VERSION ""

NS_ :

BS_:

BU_: Dummy_PHS EBOOST_OBD_PHS EOCM2cp_IMX6_PHS EOCM2cp_K1_PHS EPSb_PHS EBCM_PHS EPSa_PHS CMMb_PHS CGM3a_PHS CMMa_PHS ADIMb_PHS

BO_ 386 Environment_Id_Resp_4_PHS: 8 EBCM_PHS
 SG_ AHAct : 31|1@0+ (1,0) [0|1] ""  CGM3a_PHS
 SG_ AHEnbld : 30|1@0+ (1,0) [0|1] ""  CGM3a_PHS
 SG_ ShfToPrkBfExtngIO : 29|1@0+ (1,0) [0|1] ""  CGM3a_PHS
 SG_ AHServcIO : 28|1@0+ (1,0) [0|1] ""  CGM3a_PHS
 SG_ AHAppBrkPedlIO : 27|1@0+ (1,0) [0|1] ""  CGM3a_PHS
 SG_ AHDisbldStbltIO : 26|1@0+ (1,0) [0|1] ""  CGM3a_PHS
 SG_ AHDisbldDrOpnIO : 25|1@0+ (1,0) [0|1] ""  CGM3a_PHS
 SG_ PMVSS_Disps : 58|3@0+ (1,0) [0|7] ""  CGM3a_PHS
 SG_ PMVSS_Exhst : 61|3@0+ (1,0) [0|7] ""  CGM3a_PHS
 SG_ PMVSS_PsngrSeat : 48|3@0+ (1,0) [0|7] ""  CGM3a_PHS
 SG_ PMVSS_DrvrSeat : 51|3@0+ (1,0) [0|7] ""  CGM3a_PHS
 SG_ PMVSS_AdptCrsCnt : 54|3@0+ (1,0) [0|7] ""  CGM3a_PHS
 SG_ PMVSS_Drvln : 41|3@0+ (1,0) [0|7] ""  CGM3a_PHS
 SG_ PMVSS_Susp : 44|3@0+ (1,0) [0|7] ""  CGM3a_PHS
 SG_ PMVSS_Strng : 47|3@0+ (1,0) [0|7] ""  CGM3a_PHS
 SG_ PMVSS_Trans : 34|3@0+ (1,0) [0|7] ""  CGM3a_PHS
 SG_ PMVSS_Eng : 37|3@0+ (1,0) [0|7] ""  CGM3a_PHS
 SG_ PMVSS_Snd : 24|3@0+ (1,0) [0|7] ""  CGM3a_PHS
 SG_ AdptCruzCtrlStg : 20|3@0+ (1,0) [0|7] ""  CGM3a_PHS
 SG_ AWDRecmndIO : 21|1@0+ (1,0) [0|1] ""  CGM3a_PHS
 SG_ EnvIdRsp4 : 7|16@0+ (1,0) [0|65535] ""  CGM3a_PHS
 SG_ EnvIdRspSt4 : 17|2@0+ (1,0) [0|3] ""  CGM3a_PHS

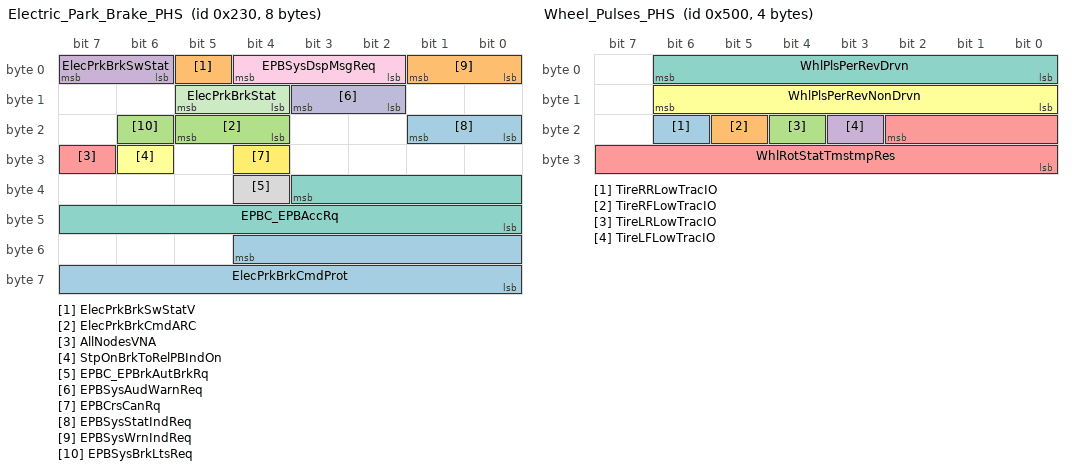
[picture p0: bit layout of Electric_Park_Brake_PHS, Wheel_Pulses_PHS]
BO_ 560 Electric_Park_Brake_PHS: 8 EBCM_PHS
 SG_ ElecPrkBrkCmdProt : 52|13@0+ (1,0) [0|8191] ""  CGM3a_PHS
 SG_ ElecPrkBrkSwStatV : 5|1@0+ (1,0) [0|1] ""  CGM3a_PHS
 SG_ ElecPrkBrkCmdARC : 21|2@0+ (1,0) [0|3] ""  CGM3a_PHS
 SG_ ElecPrkBrkSwStat : 7|2@0+ (1,0) [0|3] ""  CGM3a_PHS
 SG_ AllNodesVNA : 31|1@0+ (1,0) [0|1] ""  CGM3a_PHS
 SG_ StpOnBrkToRelPBIndOn : 30|1@0+ (1,0) [0|1] ""  CGM3a_PHS
 SG_ EPBC_EPBAccRq : 35|12@0- (0.01,0) [-20.48|20.47] "m/s^2"  CGM3a_PHS
 SG_ EPBC_EPBrkAutBrkRq : 36|1@0+ (1,0) [0|1] ""  CGM3a_PHS
 SG_ EPBSysDspMsgReq : 4|3@0+ (1,0) [0|7] ""  CGM3a_PHS
 SG_ EPBSysAudWarnReq : 11|2@0+ (1,0) [0|3] ""  CGM3a_PHS
 SG_ ElecPrkBrkStat : 13|2@0+ (1,0) [0|3] ""  CGM3a_PHS
 SG_ EPBCrsCanRq : 28|1@0+ (1,0) [0|1] ""  CGM3a_PHS
 SG_ EPBSysStatIndReq : 17|2@0+ (1,0) [0|3] ""  CGM3a_PHS
 SG_ EPBSysWrnIndReq : 1|2@0+ (1,0) [0|3] ""  CGM3a_PHS
 SG_ EPBSysBrkLtsReq : 22|1@0+ (1,0) [0|1] ""  CGM3a_PHS

BO_ 1280 Wheel_Pulses_PHS: 4 EBCM_PHS
 SG_ TireRRLowTracIO : 22|1@0+ (1,0) [0|1] ""  CGM3a_PHS,EOCM2cp_K1_PHS
 SG_ TireRFLowTracIO : 21|1@0+ (1,0) [0|1] ""  CGM3a_PHS,EOCM2cp_K1_PHS
 SG_ TireLRLowTracIO : 20|1@0+ (1,0) [0|1] ""  CGM3a_PHS,EOCM2cp_K1_PHS
 SG_ TireLFLowTracIO : 19|1@0+ (1,0) [0|1] ""  CGM3a_PHS,EOCM2cp_K1_PHS
 SG_ WhlRotStatTmstmpRes : 18|11@0+ (0.002,0) [0|4.094] "uSec"  CGM3a_PHS,EOCM2cp_K1_PHS
 SG_ WhlPlsPerRevNonDrvn : 14|7@0+ (1,0) [0|127] ""  CGM3a_PHS,EOCM2cp_K1_PHS
 SG_ WhlPlsPerRevDrvn : 6|7@0+ (1,0) [0|127] ""  CGM3a_PHS,EOCM2cp_K1_PHS

BO_ 761 PPEI_Chassis_Generl_Status_2_PHS: 7 EBCM_PHS
 SG_ BrkSysHRBkCtrlAvail : 24|1@0+ (1,0) [0|1] ""  CGM3a_PHS
 SG_ BrkSysHRBkCtrlStat : 26|2@0+ (1,0) [0|3] ""  CGM3a_PHS
 SG_ BrkSysHSAAval : 27|1@0+ (1,0) [0|1] ""  CGM3a_PHS
 SG_ BrkSysHSAStat : 30|3@0+ (1,0) [0|7] ""  CGM3a_PHS
 SG_ HillDscntCtrlStatPVal : 17|2@0+ (1,0) [0|3] ""  CGM3a_PHS
 SG_ HillDscntCtrlStatARC : 19|2@0+ (1,0) [0|3] ""  CGM3a_PHS
 SG_ HillDscntCtrlStat : 21|2@0+ (1,0) [0|3] ""  CGM3a_PHS
 SG_ AutoBrkFeatInhbtPVal : 49|2@0+ (1,0) [0|3] ""  CGM3a_PHS
 SG_ AutoBrkFeatInhbtARC : 51|2@0+ (1,0) [0|3] ""  CGM3a_PHS
 SG_ ABFI_CollPrepSysInhbt : 52|1@0+ (1,0) [0|1] ""  CGM3a_PHS
 SG_ ABFI_RrVirtlBmprInh : 53|1@0+ (1,0) [0|1] ""  CGM3a_PHS
 SG_ BrkPdlDrvApplPresV : 12|1@0+ (1,0) [0|1] ""  CGM3a_PHS
 SG_ BrkPdlDrvApplPres : 47|8@0+ (75,0) [0|19125] "kPa"  CGM3a_PHS
 SG_ AutoBrkPTReqStat : 15|3@0+ (1,0) [0|7] ""  CGM3a_PHS
 SG_ WhlSpdSnsgDTCIndex : 7|5@0+ (1,0) [0|31] ""  CGM3a_PHS
 SG_ WhlSpdSnsgDTCStat : 2|3@0+ (1,0) [0|7] ""  CGM3a_PHS
 SG_ SprTireSt : 10|3@0+ (1,0) [0|7] ""  CGM3a_PHS

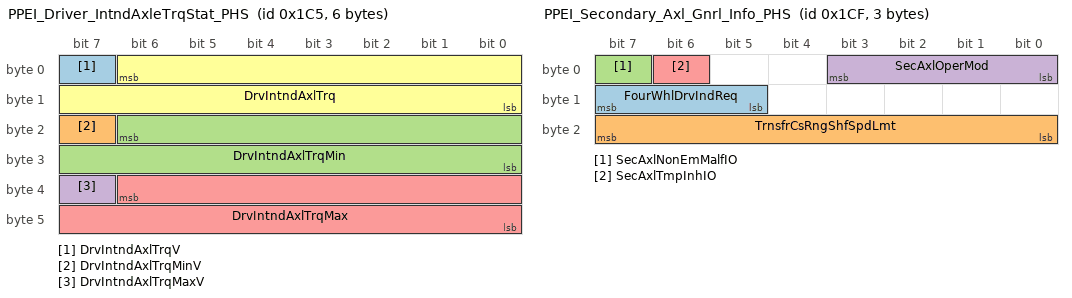
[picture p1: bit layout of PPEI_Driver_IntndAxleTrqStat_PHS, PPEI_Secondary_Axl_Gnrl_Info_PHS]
BO_ 453 PPEI_Driver_IntndAxleTrqStat_PHS: 6 CGM3a_PHS
 SG_ DrvIntndAxlTrqV : 7|1@0+ (1,0) [0|1] ""  EBCM_PHS
 SG_ DrvIntndAxlTrqMinV : 23|1@0+ (1,0) [0|1] "" Vector__XXX
 SG_ DrvIntndAxlTrqMin : 22|15@0+ (2,-22534) [-22534|43000] "Nm" Vector__XXX
 SG_ DrvIntndAxlTrqMaxV : 39|1@0+ (1,0) [0|1] "" Vector__XXX
 SG_ DrvIntndAxlTrqMax : 38|15@0+ (2,-22534) [-22534|43000] "Nm" Vector__XXX
 SG_ DrvIntndAxlTrq : 6|15@0+ (2,-22534) [-22534|43000] "Nm"  EBCM_PHS

BO_ 463 PPEI_Secondary_Axl_Gnrl_Info_PHS: 3 CGM3a_PHS
 SG_ FourWhlDrvIndReq : 15|3@0+ (1,0) [0|7] "" Vector__XXX
 SG_ TrnsfrCsRngShfSpdLmt : 23|8@0+ (1,0) [0|255] "km / h" Vector__XXX
 SG_ SecAxlNonEmMalfIO : 7|1@0+ (1,0) [0|1] "" Vector__XXX
 SG_ SecAxlOperMod : 3|4@0+ (1,0) [0|15] ""  EBCM_PHS
 SG_ SecAxlTmpInhIO : 6|1@0+ (1,0) [0|1] "" Vector__XXX

BO_ 419 PTEI_Engine_Common_Use_1_PHS: 1 CGM3a_PHS
 SG_ ClrCGMLgsDgInf : 6|1@0+ (1,0) [0|1] ""  EBCM_PHS
 SG_ EngRunng : 7|1@0+ (1,0) [0|1] ""  EBCM_PHS

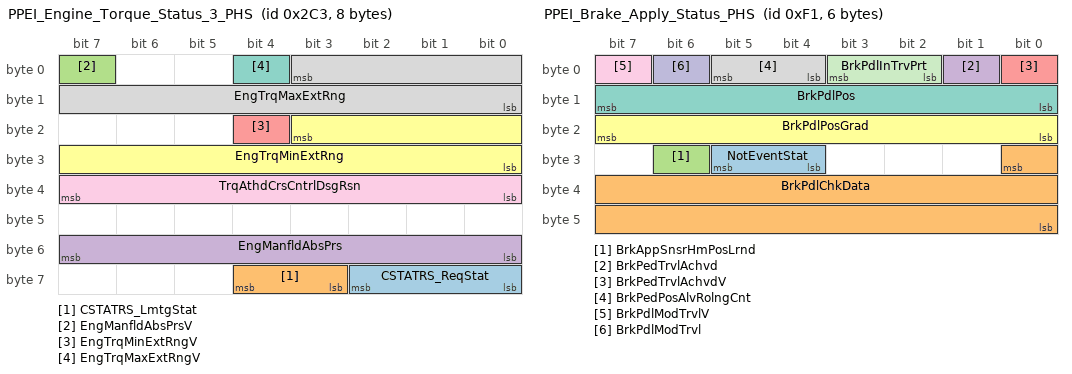
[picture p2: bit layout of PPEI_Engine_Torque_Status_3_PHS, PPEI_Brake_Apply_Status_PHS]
BO_ 707 PPEI_Engine_Torque_Status_3_PHS: 8 CGM3a_PHS
 SG_ CSTATRS_ReqStat : 58|3@0+ (1,0) [0|7] ""  EBCM_PHS
 SG_ CSTATRS_LmtgStat : 60|2@0+ (1,0) [0|3] ""  EBCM_PHS
 SG_ EngManfldAbsPrsV : 7|1@0+ (1,0) [0|1] ""  EBCM_PHS
 SG_ EngManfldAbsPrs : 55|8@0+ (0.5,0) [0|127.5] "kPa"  EBCM_PHS
 SG_ EngTrqMinExtRngV : 20|1@0+ (1,0) [0|1] ""  EBCM_PHS
 SG_ EngTrqMinExtRng : 19|12@0+ (0.5,-848) [-848|1199.5] "Nm"  EBCM_PHS
 SG_ EngTrqMaxExtRngV : 4|1@0+ (1,0) [0|1] ""  EBCM_PHS
 SG_ EngTrqMaxExtRng : 3|12@0+ (0.5,-848) [-848|1199.5] "Nm"  EBCM_PHS
 SG_ TrqAthdCrsCntrlDsgRsn : 39|8@0+ (1,0) [0|255] "" Vector__XXX

BO_ 451 PPEI_Engine_Torque_Status_2_PHS: 8 CGM3a_PHS
 SG_ HillDscntCtrlSwStatPVal : 57|2@0+ (1,0) [0|3] ""  EBCM_PHS
 SG_ HillDscntCtrlSwStatARC : 45|2@0+ (1,0) [0|3] ""  EBCM_PHS
 SG_ HillDscntCtrlSwStat : 47|2@0+ (1,0) [0|3] ""  EBCM_PHS
 SG_ GlwPlgCrnkDelAct : 58|1@0+ (1,0) [0|1] "" Vector__XXX
 SG_ AuxHtrAlwd : 23|1@0+ (1,0) [0|1] "" Vector__XXX
 SG_ AppCltchAutSrtIO : 59|1@0+ (1,0) [0|1] "" Vector__XXX
 SG_ AccPosV : 21|1@0+ (1,0) [0|1] ""  EBCM_PHS
 SG_ AccPos : 55|8@0+ (0.392157,0) [0|100.000035] "%"  EBCM_PHS
 SG_ FuelFltRmnLf : 39|8@0+ (0.392157,0) [0|100.000035] "%" Vector__XXX
 SG_ EngTrqRdFlrSt : 7|3@0+ (1,0) [0|7] ""  EBCM_PHS
 SG_ EngTrqDrRqdExtRngV : 20|1@0+ (1,0) [0|1] ""  EBCM_PHS
 SG_ EngTrqDrRqdExtRng : 19|12@0+ (0.5,-848) [-848|1199.5] "Nm"  EBCM_PHS
 SG_ EngTrqActExtRngV : 4|1@0+ (1,0) [0|1] ""  EBCM_PHS
 SG_ EngTrqActExtRng : 3|12@0+ (0.5,-848) [-848|1199.5] "Nm"  EBCM_PHS
 SG_ TrqAthdCrsCntrlAtv : 22|1@0+ (1,0) [0|1] "" Vector__XXX
 SG_ CrsCntrlRsmSet : 41|1@0+ (1,0) [0|1] "" Vector__XXX
 SG_ CrsCntrlSetSpdRtnd : 42|1@0+ (1,0) [0|1] "" Vector__XXX
 SG_ CrsCntrlSet : 40|1@0+ (1,0) [0|1] "" Vector__XXX

BO_ 241 PPEI_Brake_Apply_Status_PHS: 6 CGM3a_PHS
 SG_ NotEventStat : 29|2@0+ (1,0) [0|3] ""  EOCM2cp_K1_PHS
 SG_ BrkPdlChkData : 24|17@0+ (1,0) [0|131071] ""  EOCM2cp_K1_PHS
 SG_ BrkAppSnsrHmPosLrnd : 30|1@0+ (1,0) [0|1] ""  EOCM2cp_K1_PHS,EBCM_PHS
 SG_ BrkPedTrvlAchvd : 1|1@0+ (1,0) [0|1] ""  EOCM2cp_K1_PHS,EBCM_PHS
 SG_ BrkPedTrvlAchvdV : 0|1@0+ (1,0) [0|1] ""  EOCM2cp_K1_PHS,EBCM_PHS
 SG_ BrkPdlPosGrad : 23|8@0- (40,0) [-5120|5080] "%/s"  EOCM2cp_K1_PHS,EBCM_PHS
 SG_ BrkPdlPos : 15|8@0+ (0.392157,0) [0|100.000035] "% full"  EOCM2cp_K1_PHS,EBCM_PHS
 SG_ BrkPedPosAlvRolngCnt : 5|2@0+ (1,0) [0|3] ""  EOCM2cp_K1_PHS,EBCM_PHS
 SG_ BrkPdlModTrvlV : 7|1@0+ (1,0) [0|1] ""  EOCM2cp_K1_PHS
 SG_ BrkPdlModTrvl : 6|1@0+ (1,0) [0|1] ""  EOCM2cp_K1_PHS
 SG_ BrkPdlInTrvPrt : 3|2@0+ (1,0) [0|3] ""  EOCM2cp_K1_PHS,EBCM_PHS

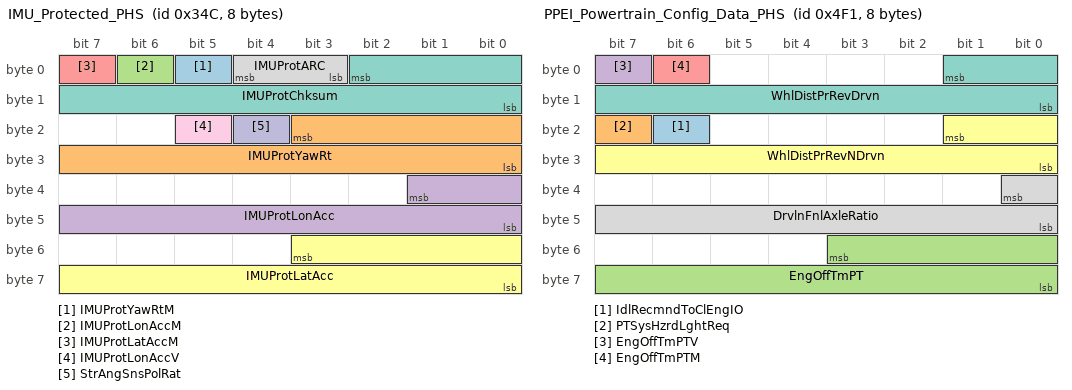
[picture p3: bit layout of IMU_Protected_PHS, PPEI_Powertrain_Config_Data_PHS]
BO_ 844 IMU_Protected_PHS: 8 EBCM_PHS
 SG_ IMUProtYawRtM : 5|1@0+ (1,0) [0|1] ""  CGM3a_PHS
 SG_ IMUProtYawRt : 19|12@0- (0.0625,0) [-128|127.9375] "deg/sec"  CGM3a_PHS
 SG_ IMUProtLonAccM : 6|1@0+ (1,0) [0|1] ""  CGM3a_PHS
 SG_ IMUProtLonAcc : 33|10@0- (0.03,0) [-15.36|15.33] "m/s^2"  CGM3a_PHS
 SG_ IMUProtLatAccM : 7|1@0+ (1,0) [0|1] ""  CGM3a_PHS
 SG_ IMUProtLatAcc : 51|12@0- (0.015625,0) [-32|31.984375] "m/s^2"  CGM3a_PHS
 SG_ IMUProtChksum : 2|11@0+ (1,0) [0|2047] ""  CGM3a_PHS
 SG_ IMUProtARC : 4|2@0+ (1,0) [0|3] ""  CGM3a_PHS
 SG_ IMUProtLonAccV : 21|1@0+ (1,0) [0|1] ""  CGM3a_PHS
 SG_ StrAngSnsPolRat : 20|1@0+ (1,0) [0|1] ""  CGM3a_PHS

BO_ 501 PPEI_Trans_General_Status_2_PHS: 8 CGM3a_PHS
 SG_ ElcRngSelDrvAct : 39|1@0+ (1,0) [0|1] "" Vector__XXX
 SG_ TmpDrvrShftCtlAct : 45|1@0+ (1,0) [0|1] ""  EOCM2cp_K1_PHS
 SG_ EngRecDwnshftIO : 54|1@0+ (1,0) [0|1] ""  EOCM2cp_K1_PHS
 SG_ TrnsPattSelEcnMdOCm : 52|1@0+ (1,0) [0|1] ""  EOCM2cp_K1_PHS
 SG_ CltStartSwAtvV : 38|1@0+ (1,0) [0|1] ""  EOCM2cp_K1_PHS
 SG_ CltStartSwAtv : 37|1@0+ (1,0) [0|1] ""  EOCM2cp_K1_PHS
 SG_ CltchPdlActPosV : 55|1@0+ (1,0) [0|1] ""  EBCM_PHS,EOCM2cp_K1_PHS
 SG_ CltchPdlActPos : 63|8@0+ (0.392157,0) [0|100.000035] "%"  EBCM_PHS,EOCM2cp_K1_PHS
 SG_ TrnsEngdStateV : 50|1@0+ (1,0) [0|1] ""  EOCM2cp_IMX6_PHS,EOCM2cp_K1_PHS,EBCM_PHS
 SG_ TrnsEngdState : 49|2@0+ (1,0) [0|3] ""  EOCM2cp_IMX6_PHS,EOCM2cp_K1_PHS,EBCM_PHS
 SG_ TrnsShftLvrLckRqd : 47|1@0+ (1,0) [0|1] ""  EOCM2cp_K1_PHS
 SG_ TransTUDMdStat : 41|2@0+ (1,0) [0|3] ""  EBCM_PHS,EOCM2cp_K1_PHS
 SG_ TrnCrpMdAtv : 46|1@0+ (1,0) [0|1] ""  EOCM2cp_K1_PHS
 SG_ TrnsSkpShftIO : 23|1@0+ (1,0) [0|1] ""  EOCM2cp_K1_PHS
 SG_ TrnsSftMdStat : 34|3@0+ (1,0) [0|7] ""  EBCM_PHS,EOCM2cp_K1_PHS
 SG_ TrnsRngInhbtStat : 31|3@0+ (1,0) [0|7] ""  EOCM2cp_K1_PHS
 SG_ TopTrvlCltchSwActV : 15|1@0+ (1,0) [0|1] ""  EOCM2cp_K1_PHS,EBCM_PHS
 SG_ TopTrvlCltchSwAct : 14|1@0+ (1,0) [0|1] ""  EOCM2cp_K1_PHS,EBCM_PHS
 SG_ EngRecmndUpshftIO : 22|1@0+ (1,0) [0|1] ""  EOCM2cp_K1_PHS
 SG_ DrvtShftCntrlTrgtGear : 19|4@0+ (1,0) [0|15] ""  EOCM2cp_K1_PHS
 SG_ DrShftCntrlReqDndIO : 21|1@0+ (1,0) [0|1] ""  EOCM2cp_K1_PHS
 SG_ TrnShftPtrnActStat : 44|3@0+ (1,0) [0|7] ""  EOCM2cp_K1_PHS,EBCM_PHS
 SG_ TrnsFldPrsPrsnt : 51|1@0+ (1,0) [0|1] ""  EOCM2cp_K1_PHS
 SG_ TrnsShftLvrPos : 27|4@0+ (1,0) [0|15] ""  EOCM2cp_IMX6_PHS,EOCM2cp_K1_PHS,EBCM_PHS
 SG_ TrnsShftLvrPosV : 28|1@0+ (1,0) [0|1] ""  EOCM2cp_IMX6_PHS,EOCM2cp_K1_PHS,EBCM_PHS
 SG_ TrnsTrqCnvCltCmndMd : 7|3@0+ (1,0) [0|7] ""  EOCM2cp_K1_PHS
 SG_ AutoTransComndGear : 11|4@0+ (1,0) [0|15] ""  EOCM2cp_IMX6_PHS,EBCM_PHS,EOCM2cp_K1_PHS
 SG_ AutoTransGrSftDirect : 13|2@0+ (1,0) [0|3] ""  EOCM2cp_IMX6_PHS,EBCM_PHS,EOCM2cp_K1_PHS
 SG_ TransEstGear : 3|4@0+ (1,0) [0|15] ""  EOCM2cp_IMX6_PHS,EOCM2cp_K1_PHS,EBCM_PHS
 SG_ TransEstGearV : 4|1@0+ (1,0) [0|1] ""  EOCM2cp_IMX6_PHS,EOCM2cp_K1_PHS,EBCM_PHS

BO_ 211 PPEI_Hybrid_General_Status_3_PHS: 2 CGM3a_PHS
 SG_ ActAxleTrqV : 7|1@0+ (1,0) [0|1] ""  EBCM_PHS
 SG_ ActAxleTrq : 6|15@0+ (2,-22534) [-22534|43000] "Nm"  EBCM_PHS

BO_ 1265 PPEI_Powertrain_Config_Data_PHS: 8 CGM3a_PHS
 SG_ IdlRecmndToClEngIO : 22|1@0+ (1,0) [0|1] "" Vector__XXX
 SG_ PTSysHzrdLghtReq : 23|1@0+ (1,0) [0|1] ""  EOCM2cp_K1_PHS
 SG_ EngOffTmPT : 51|12@0+ (0.5,0) [0|2047.5] "min"  EOCM2cp_K1_PHS,EBCM_PHS
 SG_ EngOffTmPTV : 7|1@0+ (1,0) [0|1] ""  EOCM2cp_K1_PHS,EBCM_PHS
 SG_ EngOffTmPTM : 6|1@0+ (1,0) [0|1] ""  EOCM2cp_K1_PHS,EBCM_PHS
 SG_ WhlDistPrRevNDrvn : 17|10@0+ (3,800) [800|3869] "mm"  EOCM2cp_K1_PHS,EBCM_PHS
 SG_ WhlDistPrRevDrvn : 1|10@0+ (3,800) [800|3869] "mm"  EOCM2cp_K1_PHS,EBCM_PHS
 SG_ DrvlnFnlAxleRatio : 32|9@0+ (0.01,2) [2|7.11] ""  EOCM2cp_K1_PHS,EBCM_PHS

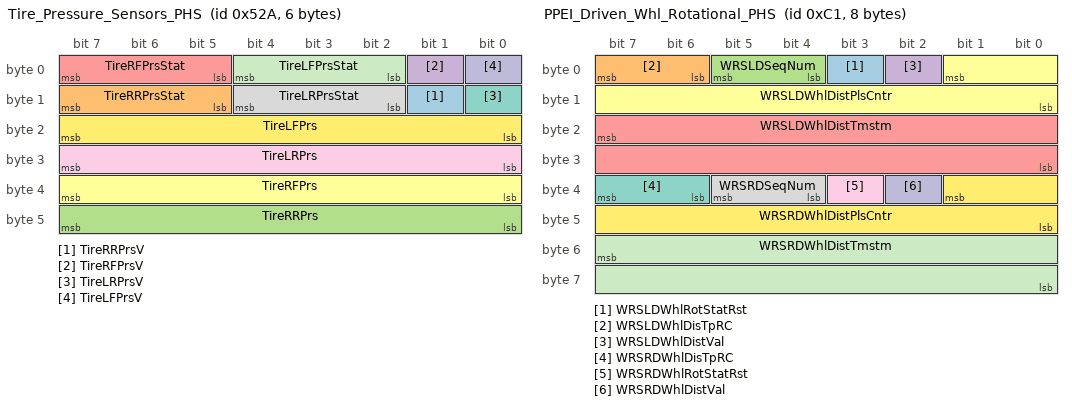
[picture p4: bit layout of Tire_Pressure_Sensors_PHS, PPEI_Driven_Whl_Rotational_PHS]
BO_ 1322 Tire_Pressure_Sensors_PHS: 6 CGM3a_PHS
 SG_ TireRRPrsV : 9|1@0+ (1,0) [0|1] ""  EBCM_PHS
 SG_ TireRRPrsStat : 15|3@0+ (1,0) [0|7] ""  EBCM_PHS
 SG_ TireRRPrs : 47|8@0+ (4,0) [0|1020] "kPaG"  EBCM_PHS
 SG_ TireRFPrsV : 1|1@0+ (1,0) [0|1] ""  EBCM_PHS
 SG_ TireRFPrsStat : 7|3@0+ (1,0) [0|7] ""  EBCM_PHS
 SG_ TireRFPrs : 39|8@0+ (4,0) [0|1020] "kPaG"  EBCM_PHS
 SG_ TireLRPrsV : 8|1@0+ (1,0) [0|1] ""  EBCM_PHS
 SG_ TireLRPrsStat : 12|3@0+ (1,0) [0|7] ""  EBCM_PHS
 SG_ TireLRPrs : 31|8@0+ (4,0) [0|1020] "kPaG"  EBCM_PHS
 SG_ TireLFPrsV : 0|1@0+ (1,0) [0|1] ""  EBCM_PHS
 SG_ TireLFPrsStat : 4|3@0+ (1,0) [0|7] ""  EBCM_PHS
 SG_ TireLFPrs : 23|8@0+ (4,0) [0|1020] "kPaG"  EBCM_PHS

BO_ 193 PPEI_Driven_Whl_Rotational_PHS: 8 EBCM_PHS
 SG_ WRSLDWhlRotStatRst : 3|1@0+ (1,0) [0|1] ""  ADIMb_PHS,CGM3a_PHS
 SG_ WRSLDWhlDisTpRC : 7|2@0+ (1,0) [0|3] "counts"  ADIMb_PHS,CGM3a_PHS
 SG_ WRSLDSeqNum : 5|2@0+ (1,0) [0|3] "counts"  ADIMb_PHS,CGM3a_PHS
 SG_ WRSLDWhlDistVal : 2|1@0+ (1,0) [0|1] ""  ADIMb_PHS,CGM3a_PHS
 SG_ WRSLDWhlDistTmstm : 23|16@0+ (1,0) [0|65535] "counts"  ADIMb_PHS,CGM3a_PHS
 SG_ WRSLDWhlDistPlsCntr : 1|10@0+ (1,0) [0|1023] "counts"  ADIMb_PHS,CGM3a_PHS
 SG_ WRSRDWhlDisTpRC : 39|2@0+ (1,0) [0|3] "counts"  ADIMb_PHS,CGM3a_PHS
 SG_ WRSRDSeqNum : 37|2@0+ (1,0) [0|3] "counts"  ADIMb_PHS,CGM3a_PHS
 SG_ WRSRDWhlRotStatRst : 35|1@0+ (1,0) [0|1] ""  ADIMb_PHS,CGM3a_PHS
 SG_ WRSRDWhlDistVal : 34|1@0+ (1,0) [0|1] ""  ADIMb_PHS,CGM3a_PHS
 SG_ WRSRDWhlDistTmstm : 55|16@0+ (1,0) [0|65535] "counts"  ADIMb_PHS,CGM3a_PHS
 SG_ WRSRDWhlDistPlsCntr : 33|10@0+ (1,0) [0|1023] "counts"  ADIMb_PHS,CGM3a_PHS

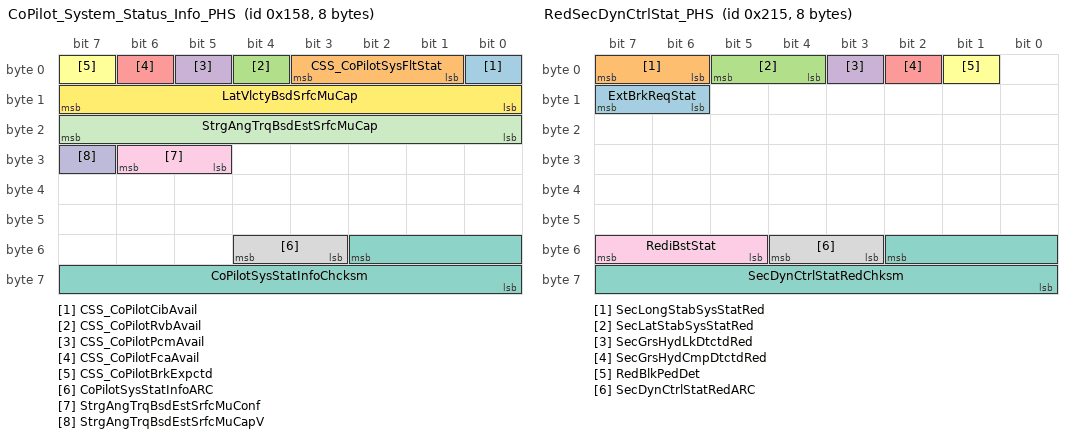
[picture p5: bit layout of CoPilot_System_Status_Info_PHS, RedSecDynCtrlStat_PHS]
BO_ 344 CoPilot_System_Status_Info_PHS: 8 EOCM2cp_K1_PHS
 SG_ CSS_CoPilotCibAvail : 0|1@0+ (1,0) [0|1] ""  EBOOST_OBD_PHS,EBCM_PHS,ADIMb_PHS
 SG_ CSS_CoPilotSysFltStat : 3|3@0+ (1,0) [0|7] ""  EBOOST_OBD_PHS,EBCM_PHS,ADIMb_PHS
 SG_ CSS_CoPilotRvbAvail : 4|1@0+ (1,0) [0|1] ""  EBOOST_OBD_PHS,EBCM_PHS,ADIMb_PHS
 SG_ CSS_CoPilotPcmAvail : 5|1@0+ (1,0) [0|1] ""  EBOOST_OBD_PHS,EBCM_PHS,ADIMb_PHS
 SG_ CSS_CoPilotFcaAvail : 6|1@0+ (1,0) [0|1] ""  EBOOST_OBD_PHS,EBCM_PHS,ADIMb_PHS
 SG_ CSS_CoPilotBrkExpctd : 7|1@0+ (1,0) [0|1] ""  EBOOST_OBD_PHS,EBCM_PHS,ADIMb_PHS
 SG_ CoPilotSysStatInfoChcksm : 50|11@0+ (1,0) [0|2047] ""  EBOOST_OBD_PHS,EBCM_PHS,ADIMb_PHS
 SG_ CoPilotSysStatInfoARC : 52|2@0+ (1,0) [0|0] ""  EBOOST_OBD_PHS,EBCM_PHS,ADIMb_PHS
 SG_ StrgAngTrqBsdEstSrfcMuConf : 30|2@0+ (1,0) [0|3] ""  EBOOST_OBD_PHS,EBCM_PHS,ADIMb_PHS
 SG_ StrgAngTrqBsdEstSrfcMuCapV : 31|1@0+ (1,0) [0|1] ""  EBOOST_OBD_PHS,EBCM_PHS,ADIMb_PHS
 SG_ StrgAngTrqBsdEstSrfcMuCap : 23|8@0+ (0.01,0) [0|2.55] ""  EBOOST_OBD_PHS,EBCM_PHS,ADIMb_PHS
 SG_ LatVlctyBsdSrfcMuCap : 15|8@0+ (0.01,0) [0|2.55] ""  EBOOST_OBD_PHS,EBCM_PHS,ADIMb_PHS

BO_ 533 RedSecDynCtrlStat_PHS: 8 EBOOST_OBD_PHS
 SG_ ExtBrkReqStat : 15|2@0+ (1,0) [0|3] ""  EBCM_PHS
 SG_ SecLongStabSysStatRed : 7|2@0+ (1,0) [0|3] ""  ADIMb_PHS,EBCM_PHS
 SG_ SecLatStabSysStatRed : 5|2@0+ (1,0) [0|0] ""  ADIMb_PHS,EBCM_PHS
 SG_ SecGrsHydLkDtctdRed : 3|1@0+ (1,0) [0|1] ""  ADIMb_PHS,EBCM_PHS
 SG_ SecGrsHydCmpDtctdRed : 2|1@0+ (1,0) [0|1] ""  ADIMb_PHS,EBCM_PHS
 SG_ RedBlkPedDet : 1|1@0+ (1,0) [0|1] ""  ADIMb_PHS,EBCM_PHS
 SG_ SecDynCtrlStatRedChksm : 50|11@0+ (1,0) [0|2047] ""  ADIMb_PHS,EBCM_PHS
 SG_ SecDynCtrlStatRedARC : 52|2@0+ (1,0) [0|3] ""  ADIMb_PHS,EBCM_PHS
 SG_ RediBstStat : 55|3@0+ (1,0) [0|7] ""  EBCM_PHS,ADIMb_PHS

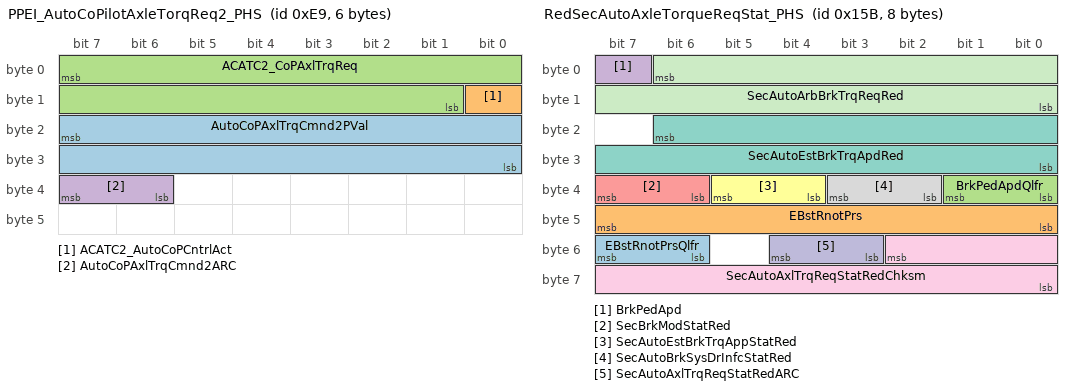
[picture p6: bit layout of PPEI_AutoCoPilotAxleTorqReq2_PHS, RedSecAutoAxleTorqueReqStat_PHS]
BO_ 233 PPEI_AutoCoPilotAxleTorqReq2_PHS: 6 EOCM2cp_K1_PHS
 SG_ AutoCoPAxlTrqCmnd2PVal : 23|16@0+ (1,0) [0|65535] ""  ADIMb_PHS,CGM3a_PHS
 SG_ ACATC2_AutoCoPCntrlAct : 8|1@0+ (1,0) [0|1] ""  ADIMb_PHS,CGM3a_PHS
 SG_ ACATC2_CoPAxlTrqReq : 7|15@0+ (2,-22534) [-22534|43000] "Nm"  ADIMb_PHS,CGM3a_PHS
 SG_ AutoCoPAxlTrqCmnd2ARC : 39|2@0+ (1,0) [0|3] ""  ADIMb_PHS,CGM3a_PHS

BO_ 347 RedSecAutoAxleTorqueReqStat_PHS: 8 EBOOST_OBD_PHS
 SG_ EBstRnotPrsQlfr : 55|2@0+ (1,0) [0|3] ""  EBCM_PHS
 SG_ EBstRnotPrs : 47|8@0+ (1,0) [0|255] "bar"  EBCM_PHS
 SG_ BrkPedApdQlfr : 33|2@0+ (1,0) [0|3] ""  EBCM_PHS
 SG_ BrkPedApd : 7|1@0+ (1,0) [0|1] ""  EBCM_PHS
 SG_ SecBrkModStatRed : 39|2@0+ (1,0) [0|3] ""  EBCM_PHS,ADIMb_PHS
 SG_ SecAutoEstBrkTrqAppStatRed : 37|2@0+ (1,0) [0|3] ""  EBCM_PHS,ADIMb_PHS
 SG_ SecAutoEstBrkTrqApdRed : 22|15@0+ (2,-65534) [-65534|0] "Nm"  EBCM_PHS,ADIMb_PHS
 SG_ SecAutoBrkSysDrInfcStatRed : 35|2@0+ (1,0) [0|3] ""  ADIMb_PHS,EBCM_PHS
 SG_ SecAutoAxlTrqReqStatRedChksm : 50|11@0+ (1,0) [0|2047] ""  EBCM_PHS,ADIMb_PHS
 SG_ SecAutoAxlTrqReqStatRedARC : 52|2@0+ (1,0) [0|3] ""  EBCM_PHS,ADIMb_PHS
 SG_ SecAutoArbBrkTrqReqRed : 6|15@0+ (2,-65534) [-65534|0] "Nm"  EBCM_PHS,ADIMb_PHS

BO_ 479 PPEI_Propulsion_Gen_Stat_1_PHS: 3 CGM3a_PHS
 SG_ EngAutoStpNotProb : 2|1@0+ (1,0) [0|1] "" Vector__XXX
 SG_ EASSI_UnsdRsrvd2 : 8|1@0+ (1,0) [0|1] ""  EBCM_PHS
 SG_ EASSI_StlDetd : 10|1@0+ (1,0) [0|1] ""  EBCM_PHS
 SG_ EASSI_TrqDetd : 11|1@0+ (1,0) [0|1] ""  EBCM_PHS
 SG_ EASSI_FuelReqOn : 12|1@0+ (1,0) [0|1] ""  EBCM_PHS
 SG_ EASSI_StrtTyp : 15|3@0+ (1,0) [0|7] ""  EBCM_PHS
 SG_ EASSI_StrtStpSt : 1|2@0+ (1,0) [0|3] ""  EBCM_PHS
 SG_ EASSI_TorqDetdIndet : 9|1@0+ (1,0) [0|1] ""  EBCM_PHS
 SG_ ASIRI_Indication08 : 16|1@0+ (1,0) [0|1] "" Vector__XXX
 SG_ ASIRI_Indication07 : 17|1@0+ (1,0) [0|1] "" Vector__XXX
 SG_ ASIRI_Indication06 : 18|1@0+ (1,0) [0|1] "" Vector__XXX
 SG_ ASIRI_Indication05 : 19|1@0+ (1,0) [0|1] "" Vector__XXX
 SG_ ASIRI_Indication04 : 20|1@0+ (1,0) [0|1] "" Vector__XXX
 SG_ ASIRI_Indication03 : 21|1@0+ (1,0) [0|1] "" Vector__XXX
 SG_ ASIRI_Indication02 : 22|1@0+ (1,0) [0|1] "" Vector__XXX
 SG_ ASIRI_Indication01 : 23|1@0+ (1,0) [0|1] "" Vector__XXX
 SG_ PTWrmgWtToShftIO : 5|1@0+ (1,0) [0|1] "" Vector__XXX
 SG_ PrplsnSysAtv : 7|1@0+ (1,0) [0|1] ""  CMMb_PHS,CMMa_PHS,EBOOST_OBD_PHS,EBCM_PHS
 SG_ PTShftLvrLckRqd : 6|1@0+ (1,0) [0|1] "" Vector__XXX

BO_ 452 PPEI_Torque_Request_Status_PHS: 8 CGM3a_PHS
 SG_ FSpRgACCSwADdPVal : 50|2@0+ (1,0) [0|3] ""  EBCM_PHS
 SG_ FSpRgACCSwADdARC : 6|2@0+ (1,0) [0|3] ""  EBCM_PHS
 SG_ FSpRgACCSwADd : 7|1@0+ (1,0) [0|1] ""  EBCM_PHS
 SG_ AutBrkAccActPsStRC : 34|2@0+ (1,0) [0|3] ""  EBCM_PHS
 SG_ AutBrkAccActPsStPVal : 48|9@0+ (1,0) [0|511] ""  EBCM_PHS
 SG_ ABAAPS_AccPos : 47|8@0+ (0.392157,0) [0|100.000035] "%"  EBCM_PHS
 SG_ ABAAPS_AccPosV : 32|1@0+ (1,0) [0|1] ""  EBCM_PHS
 SG_ ACCATCS_LmtgStat : 12|2@0+ (1,0) [0|3] "" Vector__XXX
 SG_ ACCATCS_RqStat : 15|3@0+ (1,0) [0|7] "" Vector__XXX
 SG_ RdLdNomAxlTrq : 10|19@0+ (0.125,-22534) [-22534|43001.875] "Nm" Vector__XXX
 SG_ AccPdlOvrrdAtvProtVal : 1|2@0+ (1,0) [0|3] ""  EBCM_PHS
 SG_ AccPdlOvrrdAtvARC : 3|2@0+ (1,0) [0|3] ""  EBCM_PHS
 SG_ AccPdlOvrrdAtv : 4|1@0+ (1,0) [0|1] ""  EBCM_PHS
 SG_ CPSATCS_ReqStatus : 37|3@0+ (1,0) [0|7] "" Vector__XXX
 SG_ CPSATCS_LmtngStatus : 39|2@0+ (1,0) [0|3] "" Vector__XXX
 SG_ RVBATCS_ReqStat : 53|3@0+ (1,0) [0|7] "" Vector__XXX
 SG_ RVBATCS_LmtngStat : 55|2@0+ (1,0) [0|3] "" Vector__XXX

BO_ 298 Body_Information_PHS: 8 CGM3a_PHS
 SG_ DrvrDrAjrSwVDA : 58|1@0+ (1,0) [0|1] "" Vector__XXX
 SG_ ValetMdAct : 59|1@0+ (1,0) [0|1] ""  EBCM_PHS
 SG_ AutoMdSpdLmtCnfrmd : 57|1@0+ (1,0) [0|1] ""  EOCM2cp_IMX6_PHS
 SG_ TCSysDisSwAtvARC : 61|2@0+ (1,0) [0|3] ""  EOCM2cp_IMX6_PHS,EBCM_PHS
 SG_ TCSysDisSwAtv_12A : 62|1@0+ (1,0) [0|1] ""  EOCM2cp_IMX6_PHS
 SG_ ChmAct : 55|1@0+ (1,0) [0|1] ""  EOCM2cp_IMX6_PHS
 SG_ Ky_IdDevPr : 56|1@0+ (1,0) [0|1] ""  EOCM2cp_IMX6_PHS,EBCM_PHS
 SG_ DDAjrSwAtvM : 63|1@0+ (1,0) [0|1] ""  EOCM2cp_IMX6_PHS,EBCM_PHS
 SG_ PsSbltAtcV : 54|1@0+ (1,0) [0|1] ""  EOCM2cp_IMX6_PHS
 SG_ PsSbltAtc : 53|1@0+ (1,0) [0|1] ""  EOCM2cp_IMX6_PHS
 SG_ TrlrBrkDsplyAct : 51|1@0+ (1,0) [0|1] ""  EOCM2cp_IMX6_PHS
 SG_ RdSpdCatType : 45|2@0+ (1,0) [0|3] ""  EOCM2cp_IMX6_PHS
 SG_ LnCat : 47|2@0+ (1,0) [0|3] ""  EOCM2cp_IMX6_PHS
 SG_ FncRdClass : 50|3@0+ (1,0) [0|7] ""  EOCM2cp_IMX6_PHS
 SG_ SprtLnRd : 43|1@0+ (1,0) [0|1] ""  EOCM2cp_IMX6_PHS
 SG_ CntrldAccRd : 39|1@0+ (1,0) [0|1] ""  EOCM2cp_IMX6_PHS
 SG_ BldUpArDet : 11|1@0+ (1,0) [0|1] ""  EOCM2cp_IMX6_PHS
 SG_ MpDataAvlbl : 3|1@0+ (1,0) [0|1] ""  EOCM2cp_IMX6_PHS
 SG_ SusCustStngReq : 42|3@0+ (1,0) [0|7] ""  EOCM2cp_IMX6_PHS,EBCM_PHS
 SG_ StrCustStngReq : 38|3@0+ (1,0) [0|7] ""  EOCM2cp_IMX6_PHS,EBCM_PHS
 SG_ RstrCustFctrDef : 35|1@0+ (1,0) [0|1] ""  EOCM2cp_IMX6_PHS,EBCM_PHS
 SG_ DrvlnCustStngReq : 34|3@0+ (1,0) [0|7] ""  EOCM2cp_IMX6_PHS,EBCM_PHS
 SG_ ChmMstrVDA : 22|1@0+ (1,0) [0|1] ""  EOCM2cp_IMX6_PHS
 SG_ IPCVDA : 21|1@0+ (1,0) [0|1] ""  EOCM2cp_IMX6_PHS,EBCM_PHS
 SG_ HeadUpDispVDA : 20|1@0+ (1,0) [0|1] ""  EOCM2cp_IMX6_PHS
 SG_ HapticSeatVDA : 52|1@0+ (1,0) [0|1] ""  EOCM2cp_IMX6_PHS
 SG_ RRDoorAjarSwAct : 23|1@0+ (1,0) [0|1] ""  EOCM2cp_IMX6_PHS
 SG_ PDAjrSwAtv : 10|1@0+ (1,0) [0|1] ""  EOCM2cp_IMX6_PHS
 SG_ DDAjrSwAtv : 9|1@0+ (1,0) [0|1] ""  EOCM2cp_IMX6_PHS,EBCM_PHS
 SG_ TrlrHWIntrfcVDA : 4|1@0+ (1,0) [0|1] ""  EOCM2cp_IMX6_PHS,EBCM_PHS
 SG_ DrId : 15|3@0+ (1,0) [0|7] ""  EOCM2cp_IMX6_PHS,EBCM_PHS
 SG_ EnrgMgtLdShdRq : 19|4@0+ (1,0) [0|15] ""  EOCM2cp_IMX6_PHS,EBOOST_OBD_PHS,EPSb_PHS,EBCM_PHS,EPSa_PHS
 SG_ DrSbltAtcV : 2|1@0+ (1,0) [0|1] ""  EOCM2cp_IMX6_PHS,EBCM_PHS
 SG_ TrlrHtchSwAtv : 0|1@0+ (1,0) [0|1] ""  EOCM2cp_IMX6_PHS,EBCM_PHS
 SG_ TreInfMonSysRstReq : 7|1@0+ (1,0) [0|1] ""  EOCM2cp_IMX6_PHS,EBCM_PHS
 SG_ HUDActv : 6|1@0+ (1,0) [0|1] ""  EOCM2cp_IMX6_PHS
 SG_ BatVltV : 1|1@0+ (1,0) [0|1] ""  EOCM2cp_IMX6_PHS
 SG_ BatVlt : 31|8@0+ (0.1,3) [3|28.5] "volts"  EOCM2cp_IMX6_PHS
 SG_ RLDoorAjarSwAct : 8|1@0+ (1,0) [0|1] ""  EOCM2cp_IMX6_PHS
 SG_ DrSbltAtc : 12|1@0+ (1,0) [0|1] ""  EOCM2cp_IMX6_PHS,EBCM_PHS

BO_ 1366 UUDT_Resp_From_CMMb_PHS: 8 CMMb_PHS
 SG_ DgnInf_HS556 : 7|64@0+ (1,0) [0|1.84467440737096E+019] ""  CGM3a_PHS

CM_ SG_ 707 TrqAthdCrsCntrlDsgRsn "VeACZC_e_DisengageCodeTmp";
CM_ SG_ 451 TrqAthdCrsCntrlAtv "VeCRZC_b_TorqAuthEnbldCruise";
CM_ SG_ 451 CrsCntrlRsmSet "VeACZC_b_RsmHasBeenSet";
CM_ SG_ 451 CrsCntrlSetSpdRtnd "VeACZC_b_MAIN_HasMemSpd";
CM_ SG_ 451 CrsCntrlSet "VeACZC_b_CruzHasBeenSet";
CM_ SG_ 241 BrkPdlModTrvlV "Indicates that the brake pedal position has passed a threshold for brake torque management and some 2 channel Vehicle Dynamics Control systems.";
CM_ SG_ 241 BrkPdlModTrvl "Indicates that the brake pedal position has passed a threshold for brake torque management and some 2 channel Vehicle Dynamics Control systems.";
CM_ SG_ 501 TrnShftPtrnActStat "(PT = Powertrain)";
CM_ SG_ 344 CSS_CoPilotCibAvail "Indicates if the CIB function is currently operational";
CM_ SG_ 344 CSS_CoPilotSysFltStat "

";
CM_ SG_ 344 CSS_CoPilotRvbAvail "CoPilot RVB Available";
CM_ SG_ 344 CSS_CoPilotPcmAvail "Indicates if the PCM function is currently operational";
CM_ SG_ 344 CSS_CoPilotFcaAvail "Indicates if the FCA function is currentlay operational";
CM_ SG_ 344 CSS_CoPilotBrkExpctd "Is Emergency Braking function expected to be functioning";
CM_ SG_ 298 DrId "Driver 8 changed to Unknown on 3/30/99";
BA_DEF_ SG_  "VNSigSLHSSharedDiagnostic" ENUM  "No","Yes";
BA_DEF_ SG_  "SignalType" STRING ;
BA_DEF_ SG_  "PacketOrder" INT 0 65535;
BA_DEF_ SG_  "SignalLongName" STRING ;
BA_DEF_ SG_  "GenSigStartValue" INT 0 65535;
BA_DEF_ SG_  "VNSigAllNodes" ENUM  "No","Yes";
BA_DEF_ SG_  "GenSigSendType" ENUM  "not used","not used","not used","not used","not used","not used","not used","NoSigSendType","not used","not used","OnAnyChange","OnChangeIfActive","OnDelta";
BA_DEF_ SG_  "GenSigSendOnInit" ENUM  "Not Initialized","Application","Handler";
BA_DEF_ BO_  "AppGenMsgCycleTime" INT 0 0;
BA_DEF_ BO_  "GenMsgILSupport" ENUM  "No","Yes";
BA_DEF_ BO_  "TpApplType" STRING ;
BA_DEF_ BO_  "Prio" INT 0 7;
BA_DEF_ BO_  "MessageSubnet" ENUM  "LS","HS","CE","PE","HV","FO","LE","HE2","PHS","PCE","DLCLS","DLCHS","DLCCE","DLCFO";
BA_DEF_ BO_  "DiagState" ENUM  "No","Yes";
BA_DEF_ BO_  "GenMsgStartDelayTime" INT 0 100000;
BA_DEF_ BO_  "GenMsgDelayTime" INT 0 100000;
BA_DEF_ BO_  "GenMsgCycleTime" INT 0 100000;
BA_DEF_ BO_  "GenMsgSendType" ENUM  "cyclicX","spontanX","cyclicIfActiveX","spontanWithDelay","cyclicAndSpontanX","cyclicAndSpontanWithDelay","spontanWithRepitition","cyclicIfActiveAndSpontanWD";
BA_DEF_ BO_  "DiagResponse" ENUM  "No","Yes";
BA_DEF_ BO_  "DiagRequest" ENUM  "No","Yes";
BA_DEF_ BO_  "NmMessage" ENUM  "No","Yes";
BA_DEF_REL_ BU_SG_REL_  "GenSigSuprvRespComment" STRING ;
BA_DEF_REL_ BU_SG_REL_  "GenSigVBitResp" ENUM  "No","Yes";
BA_DEF_REL_ BU_SG_REL_  "GenSigVBitRespComment" STRING ;
BA_DEF_REL_ BU_SG_REL_  "GenSigVDAFailComment" STRING ;
BA_DEF_REL_ BU_SG_REL_  "GenSigVDAFailResp" ENUM  "No","Yes";
BA_DEF_REL_ BU_SG_REL_  "GenSigRxStartValue" STRING ;
BA_DEF_REL_ BU_SG_REL_  "GenSigSuprvResp" ENUM  "None","Notify App","Substitute Default";
BA_DEF_REL_ BU_SG_REL_  "GenSigTimeoutMsg" HEX 0 268435455;
BA_DEF_REL_ BU_SG_REL_  "GenSigTimeoutTime" INT 0 15000;
BA_DEF_DEF_  "VNSigSLHSSharedDiagnostic" "No";
BA_DEF_DEF_  "SignalType" "";
BA_DEF_DEF_  "PacketOrder" 0;
BA_DEF_DEF_  "SignalLongName" "";
BA_DEF_DEF_  "GenSigStartValue" 0;
BA_DEF_DEF_  "VNSigAllNodes" "No";
BA_DEF_DEF_  "GenSigSendType" "NoSigSendType";
BA_DEF_DEF_  "GenSigSendOnInit" "Not Initialized";
BA_DEF_DEF_  "AppGenMsgCycleTime" 0;
BA_DEF_DEF_  "GenMsgILSupport" "Yes";
BA_DEF_DEF_  "TpApplType" "";
BA_DEF_DEF_  "Prio" 4;
BA_DEF_DEF_  "MessageSubnet" "LS";
BA_DEF_DEF_  "DiagState" "No";
BA_DEF_DEF_  "GenMsgStartDelayTime" 0;
BA_DEF_DEF_  "GenMsgDelayTime" 0;
BA_DEF_DEF_  "GenMsgCycleTime" 0;
BA_DEF_DEF_  "GenMsgSendType" "spontanX";
BA_DEF_DEF_  "DiagResponse" "No";
BA_DEF_DEF_  "DiagRequest" "No";
BA_DEF_DEF_  "NmMessage" "No";
BA_DEF_DEF_REL_ "GenSigSuprvRespComment" "";
BA_DEF_DEF_REL_ "GenSigVBitResp" "No";
BA_DEF_DEF_REL_ "GenSigVBitRespComment" "";
BA_DEF_DEF_REL_ "GenSigVDAFailComment" "";
BA_DEF_DEF_REL_ "GenSigVDAFailResp" "No";
BA_DEF_DEF_REL_ "GenSigRxStartValue" "";
BA_DEF_DEF_REL_ "GenSigSuprvResp" "None";
BA_DEF_DEF_REL_ "GenSigTimeoutMsg" 0;
BA_DEF_DEF_REL_ "GenSigTimeoutTime" 0;
BA_ "Prio" BO_ 386 0;
BA_ "MessageSubnet" BO_ 386 8;
BA_ "GenMsgCycleTime" BO_ 386 100;
BA_ "GenMsgSendType" BO_ 386 0;
BA_ "Prio" BO_ 560 0;
BA_ "MessageSubnet" BO_ 560 8;
BA_ "GenMsgCycleTime" BO_ 560 50;
BA_ "GenMsgSendType" BO_ 560 0;
BA_ "Prio" BO_ 1280 0;
BA_ "MessageSubnet" BO_ 1280 8;
BA_ "GenMsgCycleTime" BO_ 1280 1000;
BA_ "GenMsgSendType" BO_ 1280 0;
BA_ "Prio" BO_ 761 0;
BA_ "MessageSubnet" BO_ 761 8;
BA_ "GenMsgCycleTime" BO_ 761 50;
BA_ "GenMsgSendType" BO_ 761 0;
BA_ "Prio" BO_ 453 0;
BA_ "MessageSubnet" BO_ 453 8;
BA_ "GenMsgCycleTime" BO_ 453 25;
BA_ "GenMsgSendType" BO_ 453 0;
BA_ "Prio" BO_ 463 0;
BA_ "MessageSubnet" BO_ 463 8;
BA_ "GenMsgCycleTime" BO_ 463 100;
BA_ "GenMsgSendType" BO_ 463 0;
BA_ "Prio" BO_ 419 0;
BA_ "MessageSubnet" BO_ 419 8;
BA_ "GenMsgCycleTime" BO_ 419 25;
BA_ "GenMsgSendType" BO_ 419 0;
BA_ "Prio" BO_ 707 0;
BA_ "MessageSubnet" BO_ 707 8;
BA_ "GenMsgCycleTime" BO_ 707 50;
BA_ "GenMsgSendType" BO_ 707 0;
BA_ "Prio" BO_ 451 0;
BA_ "MessageSubnet" BO_ 451 8;
BA_ "GenMsgCycleTime" BO_ 451 25;
BA_ "GenMsgSendType" BO_ 451 0;
BA_ "Prio" BO_ 241 0;
BA_ "MessageSubnet" BO_ 241 8;
BA_ "GenMsgCycleTime" BO_ 241 10;
BA_ "GenMsgSendType" BO_ 241 0;
BA_ "Prio" BO_ 844 0;
BA_ "MessageSubnet" BO_ 844 8;
BA_ "GenMsgCycleTime" BO_ 844 50;
BA_ "GenMsgSendType" BO_ 844 0;
BA_ "Prio" BO_ 501 0;
BA_ "MessageSubnet" BO_ 501 8;
BA_ "GenMsgCycleTime" BO_ 501 25;
BA_ "GenMsgSendType" BO_ 501 0;
BA_ "Prio" BO_ 211 0;
BA_ "MessageSubnet" BO_ 211 8;
BA_ "GenMsgCycleTime" BO_ 211 12;
BA_ "GenMsgSendType" BO_ 211 0;
BA_ "Prio" BO_ 1265 0;
BA_ "MessageSubnet" BO_ 1265 8;
BA_ "GenMsgCycleTime" BO_ 1265 1000;
BA_ "GenMsgSendType" BO_ 1265 0;
BA_ "Prio" BO_ 1322 0;
BA_ "MessageSubnet" BO_ 1322 8;
BA_ "GenMsgStartDelayTime" BO_ 1322 40;
BA_ "GenMsgCycleTime" BO_ 1322 1000;
BA_ "GenMsgSendType" BO_ 1322 0;
BA_ "Prio" BO_ 193 0;
BA_ "MessageSubnet" BO_ 193 8;
BA_ "GenMsgCycleTime" BO_ 193 10;
BA_ "GenMsgSendType" BO_ 193 0;
BA_ "Prio" BO_ 344 0;
BA_ "MessageSubnet" BO_ 344 8;
BA_ "GenMsgCycleTime" BO_ 344 10;
BA_ "GenMsgSendType" BO_ 344 0;
BA_ "Prio" BO_ 533 0;
BA_ "MessageSubnet" BO_ 533 8;
BA_ "GenMsgCycleTime" BO_ 533 20;
BA_ "GenMsgSendType" BO_ 533 0;
BA_ "MessageSubnet" BO_ 233 8;
BA_ "GenMsgCycleTime" BO_ 233 10;
BA_ "GenMsgSendType" BO_ 233 0;
BA_ "Prio" BO_ 347 0;
BA_ "MessageSubnet" BO_ 347 8;
BA_ "GenMsgCycleTime" BO_ 347 10;
BA_ "GenMsgSendType" BO_ 347 0;
BA_ "Prio" BO_ 479 0;
BA_ "MessageSubnet" BO_ 479 8;
BA_ "GenMsgCycleTime" BO_ 479 25;
BA_ "GenMsgSendType" BO_ 479 0;
BA_ "Prio" BO_ 452 0;
BA_ "MessageSubnet" BO_ 452 8;
BA_ "GenMsgCycleTime" BO_ 452 25;
BA_ "GenMsgSendType" BO_ 452 0;
BA_ "Prio" BO_ 298 0;
BA_ "MessageSubnet" BO_ 298 8;
BA_ "GenMsgStartDelayTime" BO_ 298 40;
BA_ "GenMsgCycleTime" BO_ 298 100;
BA_ "GenMsgSendType" BO_ 298 0;
BA_ "GenMsgILSupport" BO_ 1366 0;
BA_ "TpApplType" BO_ 1366 "DiagUUDTResponse";
BA_ "Prio" BO_ 1366 0;
BA_ "MessageSubnet" BO_ 1366 8;
BA_ "SignalType" SG_ 386 AHAct "BLN";
BA_ "SignalLongName" SG_ 386 AHAct "Auto Hold Active";
BA_ "VNSigAllNodes" SG_ 386 AHAct 1;
BA_ "SignalType" SG_ 386 AHEnbld "BLN";
BA_ "SignalLongName" SG_ 386 AHEnbld "Auto Hold Enabled";
BA_ "VNSigAllNodes" SG_ 386 AHEnbld 1;
BA_ "SignalType" SG_ 386 ShfToPrkBfExtngIO "BLN";
BA_ "SignalLongName" SG_ 386 ShfToPrkBfExtngIO "Shift To Park Before Exiting Indication On";
BA_ "VNSigAllNodes" SG_ 386 ShfToPrkBfExtngIO 1;
BA_ "SignalType" SG_ 386 AHServcIO "BLN";
BA_ "SignalLongName" SG_ 386 AHServcIO "Auto Hold Service Indication On";
BA_ "VNSigAllNodes" SG_ 386 AHServcIO 1;
BA_ "SignalType" SG_ 386 AHAppBrkPedlIO "BLN";
BA_ "SignalLongName" SG_ 386 AHAppBrkPedlIO "Auto Hold Apply Brake Pedal Indication On";
BA_ "VNSigAllNodes" SG_ 386 AHAppBrkPedlIO 1;
BA_ "SignalType" SG_ 386 AHDisbldStbltIO "BLN";
BA_ "SignalLongName" SG_ 386 AHDisbldStbltIO "Auto Hold Disabled Seatbelt Indication On";
BA_ "VNSigAllNodes" SG_ 386 AHDisbldStbltIO 1;
BA_ "SignalType" SG_ 386 AHDisbldDrOpnIO "BLN";
BA_ "SignalLongName" SG_ 386 AHDisbldDrOpnIO "Auto Hold Disabled Door Open Indication On";
BA_ "VNSigAllNodes" SG_ 386 AHDisbldDrOpnIO 1;
BA_ "SignalType" SG_ 386 PMVSS_Disps "ENM";
BA_ "PacketOrder" SG_ 386 PMVSS_Disps 11;
BA_ "SignalLongName" SG_ 386 PMVSS_Disps "Performance Mode Visualization Screen Status : Displays";
BA_ "VNSigAllNodes" SG_ 386 PMVSS_Disps 1;
BA_ "SignalType" SG_ 386 PMVSS_Exhst "ENM";
BA_ "PacketOrder" SG_ 386 PMVSS_Exhst 10;
BA_ "SignalLongName" SG_ 386 PMVSS_Exhst "Performance Mode Visualization Screen Status : Exhaust";
BA_ "VNSigAllNodes" SG_ 386 PMVSS_Exhst 1;
BA_ "SignalType" SG_ 386 PMVSS_PsngrSeat "ENM";
BA_ "PacketOrder" SG_ 386 PMVSS_PsngrSeat 9;
BA_ "SignalLongName" SG_ 386 PMVSS_PsngrSeat "Performance Mode Visualization Screen Status : Passenger Seat";
BA_ "VNSigAllNodes" SG_ 386 PMVSS_PsngrSeat 1;
BA_ "SignalType" SG_ 386 PMVSS_DrvrSeat "ENM";
BA_ "PacketOrder" SG_ 386 PMVSS_DrvrSeat 8;
BA_ "SignalLongName" SG_ 386 PMVSS_DrvrSeat "Performance Mode Visualization Screen Status : Driver Seat";
BA_ "VNSigAllNodes" SG_ 386 PMVSS_DrvrSeat 1;
BA_ "SignalType" SG_ 386 PMVSS_AdptCrsCnt "ENM";
BA_ "PacketOrder" SG_ 386 PMVSS_AdptCrsCnt 7;
BA_ "SignalLongName" SG_ 386 PMVSS_AdptCrsCnt "Performance Mode Visualization Screen Status : Adaptive Cruise Control";
BA_ "VNSigAllNodes" SG_ 386 PMVSS_AdptCrsCnt 1;
BA_ "SignalType" SG_ 386 PMVSS_Drvln "ENM";
BA_ "PacketOrder" SG_ 386 PMVSS_Drvln 6;
BA_ "SignalLongName" SG_ 386 PMVSS_Drvln "Performance Mode Visualization Screen Status : Driveline";
BA_ "VNSigAllNodes" SG_ 386 PMVSS_Drvln 1;
BA_ "SignalType" SG_ 386 PMVSS_Susp "ENM";
BA_ "PacketOrder" SG_ 386 PMVSS_Susp 5;
BA_ "SignalLongName" SG_ 386 PMVSS_Susp "Performance Mode Visualization Screen Status : Suspension";
BA_ "VNSigAllNodes" SG_ 386 PMVSS_Susp 1;
BA_ "SignalType" SG_ 386 PMVSS_Strng "ENM";
BA_ "PacketOrder" SG_ 386 PMVSS_Strng 4;
BA_ "SignalLongName" SG_ 386 PMVSS_Strng "Performance Mode Visualization Screen Status : Steering";
BA_ "VNSigAllNodes" SG_ 386 PMVSS_Strng 1;
BA_ "SignalType" SG_ 386 PMVSS_Trans "ENM";
BA_ "PacketOrder" SG_ 386 PMVSS_Trans 3;
BA_ "SignalLongName" SG_ 386 PMVSS_Trans "Performance Mode Visualization Screen Status : Transmission";
BA_ "VNSigAllNodes" SG_ 386 PMVSS_Trans 1;
BA_ "SignalType" SG_ 386 PMVSS_Eng "ENM";
BA_ "PacketOrder" SG_ 386 PMVSS_Eng 2;
BA_ "SignalLongName" SG_ 386 PMVSS_Eng "Performance Mode Visualization Screen Status : Engine";
BA_ "VNSigAllNodes" SG_ 386 PMVSS_Eng 1;
BA_ "SignalType" SG_ 386 PMVSS_Snd "ENM";
BA_ "PacketOrder" SG_ 386 PMVSS_Snd 1;
BA_ "SignalLongName" SG_ 386 PMVSS_Snd "Performance Mode Visualization Screen Status : Sound";
BA_ "VNSigAllNodes" SG_ 386 PMVSS_Snd 1;
BA_ "SignalType" SG_ 386 AdptCruzCtrlStg "ENM";
BA_ "SignalLongName" SG_ 386 AdptCruzCtrlStg "Adaptive Cruise Control Setting";
BA_ "VNSigAllNodes" SG_ 386 AdptCruzCtrlStg 1;
BA_ "SignalType" SG_ 386 AWDRecmndIO "BLN";
BA_ "SignalLongName" SG_ 386 AWDRecmndIO "All Wheel Drive Recommended Indication On";
BA_ "VNSigAllNodes" SG_ 386 AWDRecmndIO 1;
BA_ "SignalType" SG_ 386 EnvIdRsp4 "UNM";
BA_ "SignalLongName" SG_ 386 EnvIdRsp4 "Environment Identification Response 4";
BA_ "VNSigAllNodes" SG_ 386 EnvIdRsp4 1;
BA_ "SignalType" SG_ 386 EnvIdRspSt4 "ENM";
BA_ "SignalLongName" SG_ 386 EnvIdRspSt4 "Environment Identification Response Status 4";
BA_ "VNSigAllNodes" SG_ 386 EnvIdRspSt4 1;
BA_ "SignalType" SG_ 560 ElecPrkBrkCmdProt "UNM";
BA_ "SignalLongName" SG_ 560 ElecPrkBrkCmdProt "Electric Park Brake Command Protection";
BA_ "VNSigAllNodes" SG_ 560 ElecPrkBrkCmdProt 1;
BA_ "SignalType" SG_ 560 ElecPrkBrkSwStatV "ENM";
BA_ "SignalLongName" SG_ 560 ElecPrkBrkSwStatV "Electric Park Brake Switch Status Validity";
BA_ "VNSigAllNodes" SG_ 560 ElecPrkBrkSwStatV 1;
BA_ "SignalType" SG_ 560 ElecPrkBrkCmdARC "UNM";
BA_ "SignalLongName" SG_ 560 ElecPrkBrkCmdARC "Electric Park Brake Command Alive Rolling Count";
BA_ "VNSigAllNodes" SG_ 560 ElecPrkBrkCmdARC 1;
BA_ "SignalType" SG_ 560 ElecPrkBrkSwStat "ENM";
BA_ "SignalLongName" SG_ 560 ElecPrkBrkSwStat "Electric Park Brake Switch Status";
BA_ "VNSigAllNodes" SG_ 560 ElecPrkBrkSwStat 1;
BA_ "SignalType" SG_ 560 AllNodesVNA "ENM";
BA_ "SignalLongName" SG_ 560 AllNodesVNA "All Nodes Virtual Network Activation";
BA_ "VNSigAllNodes" SG_ 560 AllNodesVNA 1;
BA_ "SignalType" SG_ 560 StpOnBrkToRelPBIndOn "BLN";
BA_ "SignalLongName" SG_ 560 StpOnBrkToRelPBIndOn "Step On Brake To Release Park Brake Indication On";
BA_ "VNSigAllNodes" SG_ 560 StpOnBrkToRelPBIndOn 1;
BA_ "SignalType" SG_ 560 EPBC_EPBAccRq "SNM";
BA_ "PacketOrder" SG_ 560 EPBC_EPBAccRq 2;
BA_ "SignalLongName" SG_ 560 EPBC_EPBAccRq "Electric Park Brake Command : Electric Park Brake Acceleration Requested";
BA_ "VNSigAllNodes" SG_ 560 EPBC_EPBAccRq 1;
BA_ "SignalType" SG_ 560 EPBC_EPBrkAutBrkRq "BLN";
BA_ "PacketOrder" SG_ 560 EPBC_EPBrkAutBrkRq 1;
BA_ "SignalLongName" SG_ 560 EPBC_EPBrkAutBrkRq "Electric Park Brake Command : Electric Park Brake Automatic Braking Requested";
BA_ "VNSigAllNodes" SG_ 560 EPBC_EPBrkAutBrkRq 1;
BA_ "SignalType" SG_ 560 EPBSysDspMsgReq "ENM";
BA_ "SignalLongName" SG_ 560 EPBSysDspMsgReq "Electric Park Brake System Display Message Request";
BA_ "VNSigAllNodes" SG_ 560 EPBSysDspMsgReq 1;
BA_ "SignalType" SG_ 560 EPBSysAudWarnReq "ENM";
BA_ "SignalLongName" SG_ 560 EPBSysAudWarnReq "Electric Park Brake System Audible Warning Request";
BA_ "VNSigAllNodes" SG_ 560 EPBSysAudWarnReq 1;
BA_ "SignalType" SG_ 560 ElecPrkBrkStat "ENM";
BA_ "SignalLongName" SG_ 560 ElecPrkBrkStat "Electric Park Brake Status";
BA_ "VNSigAllNodes" SG_ 560 ElecPrkBrkStat 1;
BA_ "SignalType" SG_ 560 EPBCrsCanRq "BLN";
BA_ "SignalLongName" SG_ 560 EPBCrsCanRq "Electric Park Brake Cruise Control Cancel Requested";
BA_ "VNSigAllNodes" SG_ 560 EPBCrsCanRq 1;
BA_ "SignalType" SG_ 560 EPBSysStatIndReq "ENM";
BA_ "SignalLongName" SG_ 560 EPBSysStatIndReq "Electric Park Brake System Status Indication Request";
BA_ "VNSigAllNodes" SG_ 560 EPBSysStatIndReq 1;
BA_ "SignalType" SG_ 560 EPBSysWrnIndReq "ENM";
BA_ "SignalLongName" SG_ 560 EPBSysWrnIndReq "Electric Park Brake System Warning Indication Request";
BA_ "VNSigAllNodes" SG_ 560 EPBSysWrnIndReq 1;
BA_ "SignalType" SG_ 560 EPBSysBrkLtsReq "BLN";
BA_ "SignalLongName" SG_ 560 EPBSysBrkLtsReq "Electric Park Brake System Brake Lights Requested";
BA_ "VNSigAllNodes" SG_ 560 EPBSysBrkLtsReq 1;
BA_ "SignalType" SG_ 1280 TireRRLowTracIO "BLN";
BA_ "SignalLongName" SG_ 1280 TireRRLowTracIO "Tire Right Rear Low Traction Indication On";
BA_ "VNSigAllNodes" SG_ 1280 TireRRLowTracIO 1;
BA_ "SignalType" SG_ 1280 TireRFLowTracIO "BLN";
BA_ "SignalLongName" SG_ 1280 TireRFLowTracIO "Tire Right Front Low Traction Indication On";
BA_ "VNSigAllNodes" SG_ 1280 TireRFLowTracIO 1;
BA_ "SignalType" SG_ 1280 TireLRLowTracIO "BLN";
BA_ "SignalLongName" SG_ 1280 TireLRLowTracIO "Tire Left Rear Low Traction Indication On";
BA_ "VNSigAllNodes" SG_ 1280 TireLRLowTracIO 1;
BA_ "SignalType" SG_ 1280 TireLFLowTracIO "BLN";
BA_ "SignalLongName" SG_ 1280 TireLFLowTracIO "Tire Left Front Low Traction Indication On";
BA_ "VNSigAllNodes" SG_ 1280 TireLFLowTracIO 1;
BA_ "SignalType" SG_ 1280 WhlRotStatTmstmpRes "UNM";
BA_ "SignalLongName" SG_ 1280 WhlRotStatTmstmpRes "Wheel Rotational Status Timestamp Resolution";
BA_ "VNSigAllNodes" SG_ 1280 WhlRotStatTmstmpRes 1;
BA_ "SignalType" SG_ 1280 WhlPlsPerRevNonDrvn "UNM";
BA_ "SignalLongName" SG_ 1280 WhlPlsPerRevNonDrvn "Wheel Pulses Per Revolution Non Driven";
BA_ "VNSigAllNodes" SG_ 1280 WhlPlsPerRevNonDrvn 1;
BA_ "SignalType" SG_ 1280 WhlPlsPerRevDrvn "UNM";
BA_ "SignalLongName" SG_ 1280 WhlPlsPerRevDrvn "Wheel Pulses Per Revolution Driven";
BA_ "VNSigAllNodes" SG_ 1280 WhlPlsPerRevDrvn 1;
BA_ "SignalType" SG_ 761 BrkSysHRBkCtrlAvail "BLN";
BA_ "SignalLongName" SG_ 761 BrkSysHRBkCtrlAvail "Brake System Hill Rollback Control Available";
BA_ "VNSigAllNodes" SG_ 761 BrkSysHRBkCtrlAvail 1;
BA_ "SignalType" SG_ 761 BrkSysHRBkCtrlStat "ENM";
BA_ "SignalLongName" SG_ 761 BrkSysHRBkCtrlStat "Brake System Hill Rollback Control Status";
BA_ "VNSigAllNodes" SG_ 761 BrkSysHRBkCtrlStat 1;
BA_ "SignalType" SG_ 761 BrkSysHSAAval "BLN";
BA_ "SignalLongName" SG_ 761 BrkSysHSAAval "Brake System Hill Start Assist Available";
BA_ "VNSigAllNodes" SG_ 761 BrkSysHSAAval 1;
BA_ "SignalType" SG_ 761 BrkSysHSAStat "ENM";
BA_ "SignalLongName" SG_ 761 BrkSysHSAStat "Brake System Hill Start Assist Status";
BA_ "VNSigAllNodes" SG_ 761 BrkSysHSAStat 1;
BA_ "SignalType" SG_ 761 HillDscntCtrlStatPVal "UNM";
BA_ "SignalLongName" SG_ 761 HillDscntCtrlStatPVal "Hill Descent Control Status Protection Value";
BA_ "VNSigAllNodes" SG_ 761 HillDscntCtrlStatPVal 1;
BA_ "SignalType" SG_ 761 HillDscntCtrlStatARC "UNM";
BA_ "SignalLongName" SG_ 761 HillDscntCtrlStatARC "Hill Descent Control Status Alive Rolling Count";
BA_ "VNSigAllNodes" SG_ 761 HillDscntCtrlStatARC 1;
BA_ "SignalType" SG_ 761 HillDscntCtrlStat "ENM";
BA_ "SignalLongName" SG_ 761 HillDscntCtrlStat "Hill Descent Control Status";
BA_ "VNSigAllNodes" SG_ 761 HillDscntCtrlStat 1;
BA_ "SignalType" SG_ 761 AutoBrkFeatInhbtPVal "UNM";
BA_ "SignalLongName" SG_ 761 AutoBrkFeatInhbtPVal "Automatic Braking Feature Inhibit Protection Value";
BA_ "VNSigAllNodes" SG_ 761 AutoBrkFeatInhbtPVal 1;
BA_ "SignalType" SG_ 761 AutoBrkFeatInhbtARC "UNM";
BA_ "SignalLongName" SG_ 761 AutoBrkFeatInhbtARC "Automatic Braking Feature Inhibit Alive Rolling Count";
BA_ "VNSigAllNodes" SG_ 761 AutoBrkFeatInhbtARC 1;
BA_ "SignalType" SG_ 761 ABFI_CollPrepSysInhbt "BLN";
BA_ "PacketOrder" SG_ 761 ABFI_CollPrepSysInhbt 2;
BA_ "SignalLongName" SG_ 761 ABFI_CollPrepSysInhbt "Automatic Braking Feature Inhibit : Collision Preparation System Inhibit";
BA_ "VNSigAllNodes" SG_ 761 ABFI_CollPrepSysInhbt 1;
BA_ "SignalType" SG_ 761 ABFI_RrVirtlBmprInh "BLN";
BA_ "PacketOrder" SG_ 761 ABFI_RrVirtlBmprInh 1;
BA_ "SignalLongName" SG_ 761 ABFI_RrVirtlBmprInh "Automatic Braking Feature Inhibit : Rear Virtual Bumper Inhibit";
BA_ "VNSigAllNodes" SG_ 761 ABFI_RrVirtlBmprInh 1;
BA_ "SignalType" SG_ 761 BrkPdlDrvApplPresV "ENM";
BA_ "SignalLongName" SG_ 761 BrkPdlDrvApplPresV "Brake Pedal Driver Applied Pressure Validity";
BA_ "VNSigAllNodes" SG_ 761 BrkPdlDrvApplPresV 1;
BA_ "SignalType" SG_ 761 BrkPdlDrvApplPres "UNM";
BA_ "SignalLongName" SG_ 761 BrkPdlDrvApplPres "Brake Pedal Driver Applied Pressure";
BA_ "VNSigAllNodes" SG_ 761 BrkPdlDrvApplPres 1;
BA_ "SignalType" SG_ 761 AutoBrkPTReqStat "ENM";
BA_ "SignalLongName" SG_ 761 AutoBrkPTReqStat "Automatic Braking Powertrain Request Status";
BA_ "VNSigAllNodes" SG_ 761 AutoBrkPTReqStat 1;
BA_ "SignalType" SG_ 761 WhlSpdSnsgDTCIndex "UNM";
BA_ "PacketOrder" SG_ 761 WhlSpdSnsgDTCIndex 1;
BA_ "SignalLongName" SG_ 761 WhlSpdSnsgDTCIndex "Wheel Speed Sensing Legislated Diagnostic Status : Diagnostic Trouble Code Index";
BA_ "VNSigAllNodes" SG_ 761 WhlSpdSnsgDTCIndex 1;
BA_ "SignalType" SG_ 761 WhlSpdSnsgDTCStat "ENM";
BA_ "PacketOrder" SG_ 761 WhlSpdSnsgDTCStat 2;
BA_ "SignalLongName" SG_ 761 WhlSpdSnsgDTCStat "Wheel Speed Sensing Legislated Diagnostic Status : Diagnostic Trouble Code Status";
BA_ "VNSigAllNodes" SG_ 761 WhlSpdSnsgDTCStat 1;
BA_ "SignalType" SG_ 761 SprTireSt "ENM";
BA_ "SignalLongName" SG_ 761 SprTireSt "Spare Tire Status";
BA_ "VNSigAllNodes" SG_ 761 SprTireSt 1;
BA_ "SignalType" SG_ 453 DrvIntndAxlTrqV "ENM";
BA_ "SignalLongName" SG_ 453 DrvIntndAxlTrqV "Driver Intended Axle Torque Validity";
BA_ "VNSigAllNodes" SG_ 453 DrvIntndAxlTrqV 1;
BA_ "SignalType" SG_ 453 DrvIntndAxlTrqMinV "ENM";
BA_ "SignalLongName" SG_ 453 DrvIntndAxlTrqMinV "Driver Intended Axle Torque Minimum Validity";
BA_ "VNSigAllNodes" SG_ 453 DrvIntndAxlTrqMinV 1;
BA_ "SignalType" SG_ 453 DrvIntndAxlTrqMin "UNM";
BA_ "SignalLongName" SG_ 453 DrvIntndAxlTrqMin "Driver Intended Axle Torque Minimum";
BA_ "VNSigAllNodes" SG_ 453 DrvIntndAxlTrqMin 1;
BA_ "SignalType" SG_ 453 DrvIntndAxlTrqMaxV "ENM";
BA_ "SignalLongName" SG_ 453 DrvIntndAxlTrqMaxV "Driver Intended Axle Torque Maximum Validity";
BA_ "VNSigAllNodes" SG_ 453 DrvIntndAxlTrqMaxV 1;
BA_ "SignalType" SG_ 453 DrvIntndAxlTrqMax "UNM";
BA_ "SignalLongName" SG_ 453 DrvIntndAxlTrqMax "Driver Intended Axle Torque Maximum";
BA_ "GenSigStartValue" SG_ 453 DrvIntndAxlTrqMax 32767;
BA_ "VNSigAllNodes" SG_ 453 DrvIntndAxlTrqMax 1;
BA_ "SignalType" SG_ 453 DrvIntndAxlTrq "UNM";
BA_ "SignalLongName" SG_ 453 DrvIntndAxlTrq "Driver Intended Axle Torque";
BA_ "GenSigStartValue" SG_ 453 DrvIntndAxlTrq 11267;
BA_ "VNSigAllNodes" SG_ 453 DrvIntndAxlTrq 1;
BA_ "SignalType" SG_ 463 FourWhlDrvIndReq "ENM";
BA_ "SignalLongName" SG_ 463 FourWhlDrvIndReq "Four Wheel Drive Indication Request";
BA_ "VNSigAllNodes" SG_ 463 FourWhlDrvIndReq 1;
BA_ "SignalType" SG_ 463 TrnsfrCsRngShfSpdLmt "UNM";
BA_ "SignalLongName" SG_ 463 TrnsfrCsRngShfSpdLmt "Transfer Case Range Shift Speed Limit";
BA_ "VNSigAllNodes" SG_ 463 TrnsfrCsRngShfSpdLmt 1;
BA_ "SignalType" SG_ 463 SecAxlNonEmMalfIO "BLN";
BA_ "SignalLongName" SG_ 463 SecAxlNonEmMalfIO "Secondary Axle Non-emissions Malf Ind On";
BA_ "VNSigAllNodes" SG_ 463 SecAxlNonEmMalfIO 1;
BA_ "SignalType" SG_ 463 SecAxlOperMod "ENM";
BA_ "SignalLongName" SG_ 463 SecAxlOperMod "Secondary Axle Operational Mode";
BA_ "VNSigAllNodes" SG_ 463 SecAxlOperMod 1;
BA_ "SignalType" SG_ 463 SecAxlTmpInhIO "BLN";
BA_ "SignalLongName" SG_ 463 SecAxlTmpInhIO "Secondary Axle Temporary Inhibit Indication On";
BA_ "VNSigAllNodes" SG_ 463 SecAxlTmpInhIO 1;
BA_ "SignalType" SG_ 419 ClrCGMLgsDgInf "BLN";
BA_ "SignalLongName" SG_ 419 ClrCGMLgsDgInf "Clear Central Gateway Module Legislated Diagnostic Information";
BA_ "VNSigAllNodes" SG_ 419 ClrCGMLgsDgInf 1;
BA_ "SignalType" SG_ 419 EngRunng "BLN";
BA_ "SignalLongName" SG_ 419 EngRunng "Engine Running";
BA_ "VNSigAllNodes" SG_ 419 EngRunng 1;
BA_ "SignalType" SG_ 707 CSTATRS_ReqStat "ENM";
BA_ "PacketOrder" SG_ 707 CSTATRS_ReqStat 2;
BA_ "SignalLongName" SG_ 707 CSTATRS_ReqStat "Chassis System Total Axle Torque Request Status : Request Status";
BA_ "VNSigAllNodes" SG_ 707 CSTATRS_ReqStat 1;
BA_ "SignalType" SG_ 707 CSTATRS_LmtgStat "ENM";
BA_ "PacketOrder" SG_ 707 CSTATRS_LmtgStat 1;
BA_ "SignalLongName" SG_ 707 CSTATRS_LmtgStat "Chassis System Total Axle Torque Request Status : Limiting Status";
BA_ "VNSigAllNodes" SG_ 707 CSTATRS_LmtgStat 1;
BA_ "SignalType" SG_ 707 EngManfldAbsPrsV "ENM";
BA_ "SignalLongName" SG_ 707 EngManfldAbsPrsV "Engine Manifold Absolute Pressure Validity";
BA_ "VNSigAllNodes" SG_ 707 EngManfldAbsPrsV 1;
BA_ "SignalType" SG_ 707 EngManfldAbsPrs "UNM";
BA_ "SignalLongName" SG_ 707 EngManfldAbsPrs "Engine Manifold Absolute Pressure";
BA_ "VNSigAllNodes" SG_ 707 EngManfldAbsPrs 1;
BA_ "SignalType" SG_ 707 EngTrqMinExtRngV "ENM";
BA_ "SignalLongName" SG_ 707 EngTrqMinExtRngV "Engine Torque Minimum Extended Range Validity";
BA_ "VNSigAllNodes" SG_ 707 EngTrqMinExtRngV 1;
BA_ "SignalType" SG_ 707 EngTrqMinExtRng "UNM";
BA_ "SignalLongName" SG_ 707 EngTrqMinExtRng "Engine Torque Minimum Extended Range";
BA_ "GenSigStartValue" SG_ 707 EngTrqMinExtRng 1696;
BA_ "VNSigAllNodes" SG_ 707 EngTrqMinExtRng 1;
BA_ "SignalType" SG_ 707 EngTrqMaxExtRngV "ENM";
BA_ "SignalLongName" SG_ 707 EngTrqMaxExtRngV "Engine Torque Maximum Extended Range Validity";
BA_ "VNSigAllNodes" SG_ 707 EngTrqMaxExtRngV 1;
BA_ "SignalType" SG_ 707 EngTrqMaxExtRng "UNM";
BA_ "SignalLongName" SG_ 707 EngTrqMaxExtRng "Engine Torque Maximum Extended Range";
BA_ "GenSigStartValue" SG_ 707 EngTrqMaxExtRng 1696;
BA_ "VNSigAllNodes" SG_ 707 EngTrqMaxExtRng 1;
BA_ "SignalType" SG_ 707 TrqAthdCrsCntrlDsgRsn "ENM";
BA_ "SignalLongName" SG_ 707 TrqAthdCrsCntrlDsgRsn "Torque Authorized Cruise Control Disengage Reason";
BA_ "GenSigStartValue" SG_ 707 TrqAthdCrsCntrlDsgRsn 12;
BA_ "VNSigAllNodes" SG_ 707 TrqAthdCrsCntrlDsgRsn 1;
BA_ "SignalType" SG_ 451 HillDscntCtrlSwStatPVal "UNM";
BA_ "SignalLongName" SG_ 451 HillDscntCtrlSwStatPVal "Hill Descent Control Switch Status Protection Value";
BA_ "VNSigAllNodes" SG_ 451 HillDscntCtrlSwStatPVal 1;
BA_ "SignalType" SG_ 451 HillDscntCtrlSwStatARC "UNM";
BA_ "SignalLongName" SG_ 451 HillDscntCtrlSwStatARC "Hill Descent Control Switch Status Alive Rolling Count";
BA_ "VNSigAllNodes" SG_ 451 HillDscntCtrlSwStatARC 1;
BA_ "SignalType" SG_ 451 HillDscntCtrlSwStat "ENM";
BA_ "SignalLongName" SG_ 451 HillDscntCtrlSwStat "Hill Descent Control Switch Status";
BA_ "VNSigAllNodes" SG_ 451 HillDscntCtrlSwStat 1;
BA_ "SignalType" SG_ 451 GlwPlgCrnkDelAct "BLN";
BA_ "SignalLongName" SG_ 451 GlwPlgCrnkDelAct "Glow Plugs Crank Delay Active";
BA_ "VNSigAllNodes" SG_ 451 GlwPlgCrnkDelAct 1;
BA_ "SignalType" SG_ 451 AuxHtrAlwd "BLN";
BA_ "SignalLongName" SG_ 451 AuxHtrAlwd "Auxiliary Heater Allowed";
BA_ "VNSigAllNodes" SG_ 451 AuxHtrAlwd 1;
BA_ "SignalType" SG_ 451 AppCltchAutSrtIO "BLN";
BA_ "SignalLongName" SG_ 451 AppCltchAutSrtIO "Apply Clutch For Automatic Start Indication On";
BA_ "VNSigAllNodes" SG_ 451 AppCltchAutSrtIO 1;
BA_ "SignalType" SG_ 451 AccPosV "ENM";
BA_ "SignalLongName" SG_ 451 AccPosV "Accelerator Effective Position Validity";
BA_ "VNSigAllNodes" SG_ 451 AccPosV 1;
BA_ "SignalType" SG_ 451 AccPos "UNM";
BA_ "SignalLongName" SG_ 451 AccPos "Accelerator Effective Position";
BA_ "VNSigAllNodes" SG_ 451 AccPos 1;
BA_ "SignalType" SG_ 451 FuelFltRmnLf "UNM";
BA_ "SignalLongName" SG_ 451 FuelFltRmnLf "Fuel Filter Remaining Life";
BA_ "VNSigAllNodes" SG_ 451 FuelFltRmnLf 1;
BA_ "SignalType" SG_ 451 EngTrqRdFlrSt "ENM";
BA_ "SignalLongName" SG_ 451 EngTrqRdFlrSt "Engine Torque Reduction Failure Status";
BA_ "VNSigAllNodes" SG_ 451 EngTrqRdFlrSt 1;
BA_ "SignalType" SG_ 451 EngTrqDrRqdExtRngV "ENM";
BA_ "SignalLongName" SG_ 451 EngTrqDrRqdExtRngV "Engine Torque Driver Requested Extended Range Validity";
BA_ "VNSigAllNodes" SG_ 451 EngTrqDrRqdExtRngV 1;
BA_ "SignalType" SG_ 451 EngTrqDrRqdExtRng "UNM";
BA_ "SignalLongName" SG_ 451 EngTrqDrRqdExtRng "Engine Torque Driver Requested Extended Range";
BA_ "GenSigStartValue" SG_ 451 EngTrqDrRqdExtRng 1696;
BA_ "VNSigAllNodes" SG_ 451 EngTrqDrRqdExtRng 1;
BA_ "SignalType" SG_ 451 EngTrqActExtRngV "ENM";
BA_ "SignalLongName" SG_ 451 EngTrqActExtRngV "Engine Torque Actual Extended Range Validity";
BA_ "VNSigAllNodes" SG_ 451 EngTrqActExtRngV 1;
BA_ "SignalType" SG_ 451 EngTrqActExtRng "UNM";
BA_ "SignalLongName" SG_ 451 EngTrqActExtRng "Engine Torque Actual Extended Range";
BA_ "GenSigStartValue" SG_ 451 EngTrqActExtRng 1696;
BA_ "VNSigAllNodes" SG_ 451 EngTrqActExtRng 1;
BA_ "SignalType" SG_ 451 TrqAthdCrsCntrlAtv "BLN";
BA_ "SignalLongName" SG_ 451 TrqAthdCrsCntrlAtv "Torque Authorized Cruise Control Active";
BA_ "VNSigAllNodes" SG_ 451 TrqAthdCrsCntrlAtv 1;
BA_ "SignalType" SG_ 451 CrsCntrlRsmSet "BLN";
BA_ "SignalLongName" SG_ 451 CrsCntrlRsmSet "Cruise Control Resume Set";
BA_ "VNSigAllNodes" SG_ 451 CrsCntrlRsmSet 1;
BA_ "SignalType" SG_ 451 CrsCntrlSetSpdRtnd "BLN";
BA_ "SignalLongName" SG_ 451 CrsCntrlSetSpdRtnd "Cruise Control Set Speed Retained";
BA_ "VNSigAllNodes" SG_ 451 CrsCntrlSetSpdRtnd 1;
BA_ "SignalType" SG_ 451 CrsCntrlSet "BLN";
BA_ "SignalLongName" SG_ 451 CrsCntrlSet "Cruise Control Set";
BA_ "VNSigAllNodes" SG_ 451 CrsCntrlSet 1;
BA_ "SignalType" SG_ 241 NotEventStat "ENM";
BA_ "SignalLongName" SG_ 241 NotEventStat "Notification Event Status";
BA_ "VNSigAllNodes" SG_ 241 NotEventStat 1;
BA_ "SignalType" SG_ 241 BrkPdlChkData "UNM";
BA_ "SignalLongName" SG_ 241 BrkPdlChkData "Brake Pedal Check Data";
BA_ "VNSigAllNodes" SG_ 241 BrkPdlChkData 1;
BA_ "SignalType" SG_ 241 BrkAppSnsrHmPosLrnd "BLN";
BA_ "SignalLongName" SG_ 241 BrkAppSnsrHmPosLrnd "Brake Apply Sensor Home Position Learned";
BA_ "VNSigAllNodes" SG_ 241 BrkAppSnsrHmPosLrnd 1;
BA_ "SignalType" SG_ 241 BrkPedTrvlAchvd "BLN";
BA_ "PacketOrder" SG_ 241 BrkPedTrvlAchvd 1;
BA_ "SignalLongName" SG_ 241 BrkPedTrvlAchvd "Brake Pedal Initial Travel Achieved Status : Brake Pedal Initial Travel Achieved";
BA_ "VNSigAllNodes" SG_ 241 BrkPedTrvlAchvd 1;
BA_ "SignalType" SG_ 241 BrkPedTrvlAchvdV "ENM";
BA_ "PacketOrder" SG_ 241 BrkPedTrvlAchvdV 2;
BA_ "SignalLongName" SG_ 241 BrkPedTrvlAchvdV "Brake Pedal Initial Travel Achieved Status : Brake Pedal Initial Travel Achieved Validity";
BA_ "VNSigAllNodes" SG_ 241 BrkPedTrvlAchvdV 1;
BA_ "SignalType" SG_ 241 BrkPdlPosGrad "SNM";
BA_ "SignalLongName" SG_ 241 BrkPdlPosGrad "Brake Pedal Position Gradient";
BA_ "VNSigAllNodes" SG_ 241 BrkPdlPosGrad 1;
BA_ "SignalType" SG_ 241 BrkPdlPos "UNM";
BA_ "SignalLongName" SG_ 241 BrkPdlPos "Brake Pedal Position";
BA_ "VNSigAllNodes" SG_ 241 BrkPdlPos 1;
BA_ "SignalType" SG_ 241 BrkPedPosAlvRolngCnt "UNM";
BA_ "SignalLongName" SG_ 241 BrkPedPosAlvRolngCnt "Brake Pedal Position Alive Rolling Count";
BA_ "VNSigAllNodes" SG_ 241 BrkPedPosAlvRolngCnt 1;
BA_ "SignalType" SG_ 241 BrkPdlModTrvlV "ENM";
BA_ "SignalLongName" SG_ 241 BrkPdlModTrvlV "Brake Pedal Moderate Travel Achieved Validity";
BA_ "VNSigAllNodes" SG_ 241 BrkPdlModTrvlV 1;
BA_ "SignalType" SG_ 241 BrkPdlModTrvl "BLN";
BA_ "SignalLongName" SG_ 241 BrkPdlModTrvl "Brake Pedal Moderate Travel Achieved";
BA_ "VNSigAllNodes" SG_ 241 BrkPdlModTrvl 1;
BA_ "SignalType" SG_ 241 BrkPdlInTrvPrt "UNM";
BA_ "SignalLongName" SG_ 241 BrkPdlInTrvPrt "Brake Pedal Initial Travel Achieved Protection";
BA_ "VNSigAllNodes" SG_ 241 BrkPdlInTrvPrt 1;
BA_ "SignalType" SG_ 844 IMUProtYawRtM "ENM";
BA_ "SignalLongName" SG_ 844 IMUProtYawRtM "Inertial Measurement Unit Protected Yaw Rate Mask";
BA_ "VNSigAllNodes" SG_ 844 IMUProtYawRtM 1;
BA_ "SignalType" SG_ 844 IMUProtYawRt "SNM";
BA_ "SignalLongName" SG_ 844 IMUProtYawRt "Inertial Measurement Unit Protected Yaw Rate";
BA_ "VNSigAllNodes" SG_ 844 IMUProtYawRt 1;
BA_ "SignalType" SG_ 844 IMUProtLonAccM "ENM";
BA_ "SignalLongName" SG_ 844 IMUProtLonAccM "Inertial Measurement Unit Protected Longitudinal Acceleration Mask";
BA_ "VNSigAllNodes" SG_ 844 IMUProtLonAccM 1;
BA_ "SignalType" SG_ 844 IMUProtLonAcc "SNM";
BA_ "SignalLongName" SG_ 844 IMUProtLonAcc "Inertial Measurement Unit Protected Longitudinal Acceleration";
BA_ "VNSigAllNodes" SG_ 844 IMUProtLonAcc 1;
BA_ "SignalType" SG_ 844 IMUProtLatAccM "ENM";
BA_ "SignalLongName" SG_ 844 IMUProtLatAccM "Inertial Measurement Unit Protected Lateral Acceleration Mask";
BA_ "VNSigAllNodes" SG_ 844 IMUProtLatAccM 1;
BA_ "SignalType" SG_ 844 IMUProtLatAcc "SNM";
BA_ "SignalLongName" SG_ 844 IMUProtLatAcc "Inertial Measurement Unit Protected Lateral Acceleration";
BA_ "VNSigAllNodes" SG_ 844 IMUProtLatAcc 1;
BA_ "SignalType" SG_ 844 IMUProtChksum "UNM";
BA_ "SignalLongName" SG_ 844 IMUProtChksum "Inertial Measurement Unit Protected Checksum";
BA_ "VNSigAllNodes" SG_ 844 IMUProtChksum 1;
BA_ "SignalType" SG_ 844 IMUProtARC "UNM";
BA_ "SignalLongName" SG_ 844 IMUProtARC "Inertial Measurement Unit Protected Alive Rolling Count";
BA_ "VNSigAllNodes" SG_ 844 IMUProtARC 1;
BA_ "SignalType" SG_ 844 IMUProtLonAccV "ENM";
BA_ "SignalLongName" SG_ 844 IMUProtLonAccV "Inertial Measurement Unit Protected Longitudinal Acceleration Validity";
BA_ "VNSigAllNodes" SG_ 844 IMUProtLonAccV 1;
BA_ "SignalType" SG_ 844 StrAngSnsPolRat "ENM";
BA_ "SignalLongName" SG_ 844 StrAngSnsPolRat "Steering Angle Sensor Polarity Rationality";
BA_ "VNSigAllNodes" SG_ 844 StrAngSnsPolRat 1;
BA_ "SignalType" SG_ 501 ElcRngSelDrvAct "BLN";
BA_ "SignalLongName" SG_ 501 ElcRngSelDrvAct "Electronic Range Selection In Drive Active";
BA_ "VNSigAllNodes" SG_ 501 ElcRngSelDrvAct 1;
BA_ "SignalType" SG_ 501 TmpDrvrShftCtlAct "BLN";
BA_ "SignalLongName" SG_ 501 TmpDrvrShftCtlAct "Temporary Driver Shift Control Active";
BA_ "VNSigAllNodes" SG_ 501 TmpDrvrShftCtlAct 1;
BA_ "SignalType" SG_ 501 EngRecDwnshftIO "BLN";
BA_ "SignalLongName" SG_ 501 EngRecDwnshftIO "Engine Recommended Downshift Indication On";
BA_ "VNSigAllNodes" SG_ 501 EngRecDwnshftIO 1;
BA_ "SignalType" SG_ 501 TrnsPattSelEcnMdOCm "BLN";
BA_ "SignalLongName" SG_ 501 TrnsPattSelEcnMdOCm "Transmission Pattern Selection Economy Mode Override Commanded";
BA_ "VNSigAllNodes" SG_ 501 TrnsPattSelEcnMdOCm 1;
BA_ "SignalType" SG_ 501 CltStartSwAtvV "ENM";
BA_ "SignalLongName" SG_ 501 CltStartSwAtvV "Clutch Start Switch Active Validity";
BA_ "VNSigAllNodes" SG_ 501 CltStartSwAtvV 1;
BA_ "SignalType" SG_ 501 CltStartSwAtv "BLN";
BA_ "SignalLongName" SG_ 501 CltStartSwAtv "Clutch Start Switch Active";
BA_ "GenSigStartValue" SG_ 501 CltStartSwAtv 1;
BA_ "VNSigAllNodes" SG_ 501 CltStartSwAtv 1;
BA_ "SignalType" SG_ 501 CltchPdlActPosV "ENM";
BA_ "SignalLongName" SG_ 501 CltchPdlActPosV "Clutch Pedal Actual Position Validity";
BA_ "VNSigAllNodes" SG_ 501 CltchPdlActPosV 1;
BA_ "SignalType" SG_ 501 CltchPdlActPos "UNM";
BA_ "SignalLongName" SG_ 501 CltchPdlActPos "Clutch Pedal Actual Position";
BA_ "VNSigAllNodes" SG_ 501 CltchPdlActPos 1;
BA_ "SignalType" SG_ 501 TrnsEngdStateV "ENM";
BA_ "SignalLongName" SG_ 501 TrnsEngdStateV "Transmission Engaged State Validity";
BA_ "VNSigAllNodes" SG_ 501 TrnsEngdStateV 1;
BA_ "SignalType" SG_ 501 TrnsEngdState "ENM";
BA_ "SignalLongName" SG_ 501 TrnsEngdState "Transmission Engaged State";
BA_ "VNSigAllNodes" SG_ 501 TrnsEngdState 1;
BA_ "SignalType" SG_ 501 TrnsShftLvrLckRqd "BLN";
BA_ "SignalLongName" SG_ 501 TrnsShftLvrLckRqd "Transmission Shift Lever Lock Requested";
BA_ "VNSigAllNodes" SG_ 501 TrnsShftLvrLckRqd 1;
BA_ "SignalType" SG_ 501 TransTUDMdStat "ENM";
BA_ "SignalLongName" SG_ 501 TransTUDMdStat "Transmission Tap Up/Tap Down Mode Status";
BA_ "VNSigAllNodes" SG_ 501 TransTUDMdStat 1;
BA_ "SignalType" SG_ 501 TrnCrpMdAtv "BLN";
BA_ "SignalLongName" SG_ 501 TrnCrpMdAtv "Transmission Creep Mode Active";
BA_ "VNSigAllNodes" SG_ 501 TrnCrpMdAtv 1;
BA_ "SignalType" SG_ 501 TrnsSkpShftIO "BLN";
BA_ "SignalLongName" SG_ 501 TrnsSkpShftIO "Transmission Skip Shift Indication On";
BA_ "VNSigAllNodes" SG_ 501 TrnsSkpShftIO 1;
BA_ "SignalType" SG_ 501 TrnsSftMdStat "ENM";
BA_ "SignalLongName" SG_ 501 TrnsSftMdStat "Transmission Shift Mode Status";
BA_ "VNSigAllNodes" SG_ 501 TrnsSftMdStat 1;
BA_ "SignalType" SG_ 501 TrnsRngInhbtStat "ENM";
BA_ "SignalLongName" SG_ 501 TrnsRngInhbtStat "Transmission Range Inhibit Status";
BA_ "VNSigAllNodes" SG_ 501 TrnsRngInhbtStat 1;
BA_ "SignalType" SG_ 501 TopTrvlCltchSwActV "ENM";
BA_ "SignalLongName" SG_ 501 TopTrvlCltchSwActV "Top of Travel Clutch Switch Active Validity";
BA_ "VNSigAllNodes" SG_ 501 TopTrvlCltchSwActV 1;
BA_ "SignalType" SG_ 501 TopTrvlCltchSwAct "BLN";
BA_ "SignalLongName" SG_ 501 TopTrvlCltchSwAct "Top of Travel Clutch Switch Active";
BA_ "VNSigAllNodes" SG_ 501 TopTrvlCltchSwAct 1;
BA_ "SignalType" SG_ 501 EngRecmndUpshftIO "BLN";
BA_ "SignalLongName" SG_ 501 EngRecmndUpshftIO "Engine Recommended Upshift Indication On";
BA_ "VNSigAllNodes" SG_ 501 EngRecmndUpshftIO 1;
BA_ "SignalType" SG_ 501 DrvtShftCntrlTrgtGear "ENM";
BA_ "SignalLongName" SG_ 501 DrvtShftCntrlTrgtGear "Driver Shift Control Target Gear";
BA_ "VNSigAllNodes" SG_ 501 DrvtShftCntrlTrgtGear 1;
BA_ "SignalType" SG_ 501 DrShftCntrlReqDndIO "BLN";
BA_ "SignalLongName" SG_ 501 DrShftCntrlReqDndIO "Driver Shift Control Request Denied Indication On";
BA_ "VNSigAllNodes" SG_ 501 DrShftCntrlReqDndIO 1;
BA_ "SignalType" SG_ 501 TrnShftPtrnActStat "ENM";
BA_ "SignalLongName" SG_ 501 TrnShftPtrnActStat "Transmission Shift Pattern Active Status";
BA_ "VNSigAllNodes" SG_ 501 TrnShftPtrnActStat 1;
BA_ "SignalType" SG_ 501 TrnsFldPrsPrsnt "BLN";
BA_ "SignalLongName" SG_ 501 TrnsFldPrsPrsnt "Transmission Fluid Pressure Present";
BA_ "VNSigAllNodes" SG_ 501 TrnsFldPrsPrsnt 1;
BA_ "SignalType" SG_ 501 TrnsShftLvrPos "ENM";
BA_ "SignalLongName" SG_ 501 TrnsShftLvrPos "Transmission Shift Lever Position";
BA_ "VNSigAllNodes" SG_ 501 TrnsShftLvrPos 1;
BA_ "SignalType" SG_ 501 TrnsShftLvrPosV "ENM";
BA_ "SignalLongName" SG_ 501 TrnsShftLvrPosV "Transmission Shift Lever Position Validity";
BA_ "VNSigAllNodes" SG_ 501 TrnsShftLvrPosV 1;
BA_ "SignalType" SG_ 501 TrnsTrqCnvCltCmndMd "ENM";
BA_ "SignalLongName" SG_ 501 TrnsTrqCnvCltCmndMd "Transmission Torque Converter Clutch Commanded Mode";
BA_ "GenSigStartValue" SG_ 501 TrnsTrqCnvCltCmndMd 7;
BA_ "VNSigAllNodes" SG_ 501 TrnsTrqCnvCltCmndMd 1;
BA_ "SignalType" SG_ 501 AutoTransComndGear "ENM";
BA_ "SignalLongName" SG_ 501 AutoTransComndGear "Automatic Transmission Commanded Gear";
BA_ "GenSigStartValue" SG_ 501 AutoTransComndGear 15;
BA_ "VNSigAllNodes" SG_ 501 AutoTransComndGear 1;
BA_ "SignalType" SG_ 501 AutoTransGrSftDirect "ENM";
BA_ "SignalLongName" SG_ 501 AutoTransGrSftDirect "Automatic Transmission Gear Shift Direction";
BA_ "VNSigAllNodes" SG_ 501 AutoTransGrSftDirect 1;
BA_ "SignalType" SG_ 501 TransEstGear "ENM";
BA_ "SignalLongName" SG_ 501 TransEstGear "Transmission Estimated Gear";
BA_ "GenSigStartValue" SG_ 501 TransEstGear 15;
BA_ "VNSigAllNodes" SG_ 501 TransEstGear 1;
BA_ "SignalType" SG_ 501 TransEstGearV "ENM";
BA_ "SignalLongName" SG_ 501 TransEstGearV "Transmission Estimated Gear Validity";
BA_ "VNSigAllNodes" SG_ 501 TransEstGearV 1;
BA_ "SignalType" SG_ 211 ActAxleTrqV "ENM";
BA_ "SignalLongName" SG_ 211 ActAxleTrqV "Actual Axle Torque Validity";
BA_ "VNSigAllNodes" SG_ 211 ActAxleTrqV 1;
BA_ "SignalType" SG_ 211 ActAxleTrq "UNM";
BA_ "SignalLongName" SG_ 211 ActAxleTrq "Actual Axle Torque";
BA_ "VNSigAllNodes" SG_ 211 ActAxleTrq 1;
BA_ "SignalType" SG_ 1265 IdlRecmndToClEngIO "BLN";
BA_ "SignalLongName" SG_ 1265 IdlRecmndToClEngIO "Idle Recommended to Cool Engine Indication On";
BA_ "VNSigAllNodes" SG_ 1265 IdlRecmndToClEngIO 1;
BA_ "SignalType" SG_ 1265 PTSysHzrdLghtReq "BLN";
BA_ "SignalLongName" SG_ 1265 PTSysHzrdLghtReq "Powertrain System Hazard Lights Request";
BA_ "VNSigAllNodes" SG_ 1265 PTSysHzrdLghtReq 1;
BA_ "SignalType" SG_ 1265 EngOffTmPT "UNM";
BA_ "SignalLongName" SG_ 1265 EngOffTmPT "Engine Off Time Powertrain";
BA_ "VNSigAllNodes" SG_ 1265 EngOffTmPT 1;
BA_ "SignalType" SG_ 1265 EngOffTmPTV "ENM";
BA_ "SignalLongName" SG_ 1265 EngOffTmPTV "Engine Off Time Powertrain Validity";
BA_ "VNSigAllNodes" SG_ 1265 EngOffTmPTV 1;
BA_ "SignalType" SG_ 1265 EngOffTmPTM "ENM";
BA_ "SignalLongName" SG_ 1265 EngOffTmPTM "Engine Off Time Powertrain Mask";
BA_ "VNSigAllNodes" SG_ 1265 EngOffTmPTM 1;
BA_ "SignalType" SG_ 1265 WhlDistPrRevNDrvn "UNM";
BA_ "SignalLongName" SG_ 1265 WhlDistPrRevNDrvn "Wheel Distance Per Revolution Non Driven";
BA_ "VNSigAllNodes" SG_ 1265 WhlDistPrRevNDrvn 1;
BA_ "SignalType" SG_ 1265 WhlDistPrRevDrvn "UNM";
BA_ "SignalLongName" SG_ 1265 WhlDistPrRevDrvn "Wheel Distance Per Revolution Driven";
BA_ "VNSigAllNodes" SG_ 1265 WhlDistPrRevDrvn 1;
BA_ "SignalType" SG_ 1265 DrvlnFnlAxleRatio "UNM";
BA_ "SignalLongName" SG_ 1265 DrvlnFnlAxleRatio "Driveline Final Axle Ratio";
BA_ "VNSigAllNodes" SG_ 1265 DrvlnFnlAxleRatio 1;
BA_ "SignalType" SG_ 1322 TireRRPrsV "ENM";
BA_ "SignalLongName" SG_ 1322 TireRRPrsV "Tire Right Rear Pressure Validity";
BA_ "VNSigAllNodes" SG_ 1322 TireRRPrsV 1;
BA_ "SignalType" SG_ 1322 TireRRPrsStat "ENM";
BA_ "SignalLongName" SG_ 1322 TireRRPrsStat "Tire Right Rear Pressure Status";
BA_ "VNSigAllNodes" SG_ 1322 TireRRPrsStat 1;
BA_ "SignalType" SG_ 1322 TireRRPrs "UNM";
BA_ "SignalLongName" SG_ 1322 TireRRPrs "Tire Right Rear Pressure";
BA_ "GenSigStartValue" SG_ 1322 TireRRPrs 255;
BA_ "VNSigAllNodes" SG_ 1322 TireRRPrs 1;
BA_ "SignalType" SG_ 1322 TireRFPrsV "ENM";
BA_ "SignalLongName" SG_ 1322 TireRFPrsV "Tire Right Front Pressure Validity";
BA_ "VNSigAllNodes" SG_ 1322 TireRFPrsV 1;
BA_ "SignalType" SG_ 1322 TireRFPrsStat "ENM";
BA_ "SignalLongName" SG_ 1322 TireRFPrsStat "Tire Right Front Pressure Status";
BA_ "VNSigAllNodes" SG_ 1322 TireRFPrsStat 1;
BA_ "SignalType" SG_ 1322 TireRFPrs "UNM";
BA_ "SignalLongName" SG_ 1322 TireRFPrs "Tire Right Front Pressure";
BA_ "GenSigStartValue" SG_ 1322 TireRFPrs 255;
BA_ "VNSigAllNodes" SG_ 1322 TireRFPrs 1;
BA_ "SignalType" SG_ 1322 TireLRPrsV "ENM";
BA_ "SignalLongName" SG_ 1322 TireLRPrsV "Tire Left Rear Pressure Validity";
BA_ "VNSigAllNodes" SG_ 1322 TireLRPrsV 1;
BA_ "SignalType" SG_ 1322 TireLRPrsStat "ENM";
BA_ "SignalLongName" SG_ 1322 TireLRPrsStat "Tire Left Rear Pressure Status";
BA_ "VNSigAllNodes" SG_ 1322 TireLRPrsStat 1;
BA_ "SignalType" SG_ 1322 TireLRPrs "UNM";
BA_ "SignalLongName" SG_ 1322 TireLRPrs "Tire Left Rear Pressure";
BA_ "GenSigStartValue" SG_ 1322 TireLRPrs 255;
BA_ "VNSigAllNodes" SG_ 1322 TireLRPrs 1;
BA_ "SignalType" SG_ 1322 TireLFPrsV "ENM";
BA_ "SignalLongName" SG_ 1322 TireLFPrsV "Tire Left Front Pressure Validity";
BA_ "VNSigAllNodes" SG_ 1322 TireLFPrsV 1;
BA_ "SignalType" SG_ 1322 TireLFPrsStat "ENM";
BA_ "SignalLongName" SG_ 1322 TireLFPrsStat "Tire Left Front Pressure Status";
BA_ "VNSigAllNodes" SG_ 1322 TireLFPrsStat 1;
BA_ "SignalType" SG_ 1322 TireLFPrs "UNM";
BA_ "SignalLongName" SG_ 1322 TireLFPrs "Tire Left Front Pressure";
BA_ "GenSigStartValue" SG_ 1322 TireLFPrs 255;
BA_ "VNSigAllNodes" SG_ 1322 TireLFPrs 1;
BA_ "SignalType" SG_ 193 WRSLDWhlRotStatRst "BLN";
BA_ "PacketOrder" SG_ 193 WRSLDWhlRotStatRst 3;
BA_ "SignalLongName" SG_ 193 WRSLDWhlRotStatRst "Wheel Rotational Status Left Driven : Wheel Rotational Status Reset Occurred";
BA_ "VNSigAllNodes" SG_ 193 WRSLDWhlRotStatRst 1;
BA_ "SignalType" SG_ 193 WRSLDWhlDisTpRC "UNM";
BA_ "PacketOrder" SG_ 193 WRSLDWhlDisTpRC 1;
BA_ "SignalLongName" SG_ 193 WRSLDWhlDisTpRC "Wheel Rotational Status Left Driven : Wheel Distance Timestamp Rollover Counter";
BA_ "VNSigAllNodes" SG_ 193 WRSLDWhlDisTpRC 1;
BA_ "SignalType" SG_ 193 WRSLDSeqNum "UNM";
BA_ "PacketOrder" SG_ 193 WRSLDSeqNum 2;
BA_ "SignalLongName" SG_ 193 WRSLDSeqNum "Wheel Rotational Status Left Driven : Sequence Number";
BA_ "VNSigAllNodes" SG_ 193 WRSLDSeqNum 1;
BA_ "SignalType" SG_ 193 WRSLDWhlDistVal "ENM";
BA_ "PacketOrder" SG_ 193 WRSLDWhlDistVal 4;
BA_ "SignalLongName" SG_ 193 WRSLDWhlDistVal "Wheel Rotational Status Left Driven : Wheel Distance Validity";
BA_ "VNSigAllNodes" SG_ 193 WRSLDWhlDistVal 1;
BA_ "SignalType" SG_ 193 WRSLDWhlDistTmstm "UNM";
BA_ "PacketOrder" SG_ 193 WRSLDWhlDistTmstm 6;
BA_ "SignalLongName" SG_ 193 WRSLDWhlDistTmstm "Wheel Rotational Status Left Driven : Wheel Distance Timestamp";
BA_ "VNSigAllNodes" SG_ 193 WRSLDWhlDistTmstm 1;
BA_ "SignalType" SG_ 193 WRSLDWhlDistPlsCntr "UNM";
BA_ "PacketOrder" SG_ 193 WRSLDWhlDistPlsCntr 5;
BA_ "SignalLongName" SG_ 193 WRSLDWhlDistPlsCntr "Wheel Rotational Status Left Driven : Wheel Distance Pulse Counter";
BA_ "VNSigAllNodes" SG_ 193 WRSLDWhlDistPlsCntr 1;
BA_ "SignalType" SG_ 193 WRSRDWhlDisTpRC "UNM";
BA_ "PacketOrder" SG_ 193 WRSRDWhlDisTpRC 1;
BA_ "SignalLongName" SG_ 193 WRSRDWhlDisTpRC "Wheel Rotational Status Right Driven : Wheel Distance Timestamp Rollover Counter";
BA_ "VNSigAllNodes" SG_ 193 WRSRDWhlDisTpRC 1;
BA_ "SignalType" SG_ 193 WRSRDSeqNum "UNM";
BA_ "PacketOrder" SG_ 193 WRSRDSeqNum 2;
BA_ "SignalLongName" SG_ 193 WRSRDSeqNum "Wheel Rotational Status Right Driven : Sequence Number";
BA_ "VNSigAllNodes" SG_ 193 WRSRDSeqNum 1;
BA_ "SignalType" SG_ 193 WRSRDWhlRotStatRst "BLN";
BA_ "PacketOrder" SG_ 193 WRSRDWhlRotStatRst 3;
BA_ "SignalLongName" SG_ 193 WRSRDWhlRotStatRst "Wheel Rotational Status Right Driven : Wheel Rotational Status Reset Occurred";
BA_ "VNSigAllNodes" SG_ 193 WRSRDWhlRotStatRst 1;
BA_ "SignalType" SG_ 193 WRSRDWhlDistVal "ENM";
BA_ "PacketOrder" SG_ 193 WRSRDWhlDistVal 4;
BA_ "SignalLongName" SG_ 193 WRSRDWhlDistVal "Wheel Rotational Status Right Driven : Wheel Distance Validity";
BA_ "VNSigAllNodes" SG_ 193 WRSRDWhlDistVal 1;
BA_ "SignalType" SG_ 193 WRSRDWhlDistTmstm "UNM";
BA_ "PacketOrder" SG_ 193 WRSRDWhlDistTmstm 6;
BA_ "SignalLongName" SG_ 193 WRSRDWhlDistTmstm "Wheel Rotational Status Right Driven : Wheel Distance Timestamp";
BA_ "VNSigAllNodes" SG_ 193 WRSRDWhlDistTmstm 1;
BA_ "SignalType" SG_ 193 WRSRDWhlDistPlsCntr "UNM";
BA_ "PacketOrder" SG_ 193 WRSRDWhlDistPlsCntr 5;
BA_ "SignalLongName" SG_ 193 WRSRDWhlDistPlsCntr "Wheel Rotational Status Right Driven : Wheel Distance Pulse Counter";
BA_ "VNSigAllNodes" SG_ 193 WRSRDWhlDistPlsCntr 1;
BA_ "SignalType" SG_ 344 CSS_CoPilotCibAvail "BLN";
BA_ "SignalLongName" SG_ 344 CSS_CoPilotCibAvail "CoPilot System Status : CoPilot Collision Imminent Braking Available";
BA_ "VNSigAllNodes" SG_ 344 CSS_CoPilotCibAvail 1;
BA_ "SignalType" SG_ 344 CSS_CoPilotSysFltStat "ENM";
BA_ "SignalLongName" SG_ 344 CSS_CoPilotSysFltStat "CoPilot System Status : CoPilot System Fault Status";
BA_ "VNSigAllNodes" SG_ 344 CSS_CoPilotSysFltStat 1;
BA_ "SignalType" SG_ 344 CSS_CoPilotRvbAvail "BLN";
BA_ "SignalLongName" SG_ 344 CSS_CoPilotRvbAvail "CoPilot System Status : CoPilot Rear Virtual Bumper Available";
BA_ "VNSigAllNodes" SG_ 344 CSS_CoPilotRvbAvail 1;
BA_ "SignalType" SG_ 344 CSS_CoPilotPcmAvail "BLN";
BA_ "SignalLongName" SG_ 344 CSS_CoPilotPcmAvail "CoPilot System Status : CoPilot Pedestrian Collision Mitigation Available";
BA_ "VNSigAllNodes" SG_ 344 CSS_CoPilotPcmAvail 1;
BA_ "SignalType" SG_ 344 CSS_CoPilotFcaAvail "BLN";
BA_ "SignalLongName" SG_ 344 CSS_CoPilotFcaAvail "CoPilot System Status : CoPilot Forward Collision Alert Available";
BA_ "VNSigAllNodes" SG_ 344 CSS_CoPilotFcaAvail 1;
BA_ "SignalType" SG_ 344 CSS_CoPilotBrkExpctd "BLN";
BA_ "SignalLongName" SG_ 344 CSS_CoPilotBrkExpctd "CoPilot System Status : CoPilot Braking Expected";
BA_ "VNSigAllNodes" SG_ 344 CSS_CoPilotBrkExpctd 1;
BA_ "SignalType" SG_ 344 CoPilotSysStatInfoChcksm "UNM";
BA_ "SignalLongName" SG_ 344 CoPilotSysStatInfoChcksm "CoPilot System Status Info Checksum";
BA_ "VNSigAllNodes" SG_ 344 CoPilotSysStatInfoChcksm 1;
BA_ "SignalType" SG_ 344 CoPilotSysStatInfoARC "UNM";
BA_ "SignalLongName" SG_ 344 CoPilotSysStatInfoARC "CoPilot System Status Info Alive Rolling Count";
BA_ "VNSigAllNodes" SG_ 344 CoPilotSysStatInfoARC 1;
BA_ "SignalType" SG_ 344 StrgAngTrqBsdEstSrfcMuConf "ENM";
BA_ "SignalLongName" SG_ 344 StrgAngTrqBsdEstSrfcMuConf "Steering Angle Torque Based Estimated Surface Mu Confidence";
BA_ "VNSigAllNodes" SG_ 344 StrgAngTrqBsdEstSrfcMuConf 1;
BA_ "SignalType" SG_ 344 StrgAngTrqBsdEstSrfcMuCapV "ENM";
BA_ "SignalLongName" SG_ 344 StrgAngTrqBsdEstSrfcMuCapV "Steering Angle Torque Based Estimated Surface Mu Capacity Validity";
BA_ "VNSigAllNodes" SG_ 344 StrgAngTrqBsdEstSrfcMuCapV 1;
BA_ "SignalType" SG_ 344 StrgAngTrqBsdEstSrfcMuCap "UNM";
BA_ "SignalLongName" SG_ 344 StrgAngTrqBsdEstSrfcMuCap "Steering Angle Torque Based Estimated Surface Mu Capacity";
BA_ "VNSigAllNodes" SG_ 344 StrgAngTrqBsdEstSrfcMuCap 1;
BA_ "SignalType" SG_ 344 LatVlctyBsdSrfcMuCap "UNM";
BA_ "SignalLongName" SG_ 344 LatVlctyBsdSrfcMuCap "Lateral Velocity Based Surface Mu Capacity";
BA_ "VNSigAllNodes" SG_ 344 LatVlctyBsdSrfcMuCap 1;
BA_ "SignalType" SG_ 533 ExtBrkReqStat "ENM";
BA_ "SignalLongName" SG_ 533 ExtBrkReqStat "External Brake Request Status";
BA_ "VNSigAllNodes" SG_ 533 ExtBrkReqStat 1;
BA_ "SignalType" SG_ 533 SecLongStabSysStatRed "ENM";
BA_ "SignalLongName" SG_ 533 SecLongStabSysStatRed "Secondary Longitudinal Stability System Status Redundant";
BA_ "VNSigAllNodes" SG_ 533 SecLongStabSysStatRed 1;
BA_ "SignalType" SG_ 533 SecLatStabSysStatRed "ENM";
BA_ "SignalLongName" SG_ 533 SecLatStabSysStatRed "Secondary Lateral Stability System Status Redundant";
BA_ "VNSigAllNodes" SG_ 533 SecLatStabSysStatRed 1;
BA_ "SignalType" SG_ 533 SecGrsHydLkDtctdRed "BLN";
BA_ "SignalLongName" SG_ 533 SecGrsHydLkDtctdRed "Secondary Gross Hydraulic Leak Detected Redundant";
BA_ "VNSigAllNodes" SG_ 533 SecGrsHydLkDtctdRed 1;
BA_ "SignalType" SG_ 533 SecGrsHydCmpDtctdRed "BLN";
BA_ "SignalLongName" SG_ 533 SecGrsHydCmpDtctdRed "Secondary Gross Hydraulic Compliance Detected Redundant";
BA_ "VNSigAllNodes" SG_ 533 SecGrsHydCmpDtctdRed 1;
BA_ "SignalType" SG_ 533 RedBlkPedDet "BLN";
BA_ "SignalLongName" SG_ 533 RedBlkPedDet "Blocked Pedal Detected Redundant";
BA_ "VNSigAllNodes" SG_ 533 RedBlkPedDet 1;
BA_ "SignalType" SG_ 533 SecDynCtrlStatRedChksm "UNM";
BA_ "SignalLongName" SG_ 533 SecDynCtrlStatRedChksm "Secondary Dynamic Control Status Redundant Checksum";
BA_ "VNSigAllNodes" SG_ 533 SecDynCtrlStatRedChksm 1;
BA_ "SignalType" SG_ 533 SecDynCtrlStatRedARC "UNM";
BA_ "SignalLongName" SG_ 533 SecDynCtrlStatRedARC "Secondary Dynamic Control Status Redundant Alive Rolling Count";
BA_ "VNSigAllNodes" SG_ 533 SecDynCtrlStatRedARC 1;
BA_ "SignalType" SG_ 533 RediBstStat "ENM";
BA_ "SignalLongName" SG_ 533 RediBstStat "iBooster Status Redundant";
BA_ "VNSigAllNodes" SG_ 533 RediBstStat 1;
BA_ "SignalType" SG_ 233 AutoCoPAxlTrqCmnd2PVal "UNM";
BA_ "SignalLongName" SG_ 233 AutoCoPAxlTrqCmnd2PVal "Autonomous CoPilot Axle Torque Command 2 Protection Value";
BA_ "VNSigAllNodes" SG_ 233 AutoCoPAxlTrqCmnd2PVal 1;
BA_ "SignalType" SG_ 233 ACATC2_AutoCoPCntrlAct "BLN";
BA_ "SignalLongName" SG_ 233 ACATC2_AutoCoPCntrlAct "Autonomous CoPilot Axle Torque Command 2: Autonomous CoPilot Control Active";
BA_ "VNSigAllNodes" SG_ 233 ACATC2_AutoCoPCntrlAct 1;
BA_ "SignalType" SG_ 233 ACATC2_CoPAxlTrqReq "UNM";
BA_ "SignalLongName" SG_ 233 ACATC2_CoPAxlTrqReq "Autonomous CoPilot Axle Torque Command 2: CoPilot Axle Torque Request";
BA_ "GenSigStartValue" SG_ 233 ACATC2_CoPAxlTrqReq 11267;
BA_ "VNSigAllNodes" SG_ 233 ACATC2_CoPAxlTrqReq 1;
BA_ "SignalType" SG_ 233 AutoCoPAxlTrqCmnd2ARC "UNM";
BA_ "SignalLongName" SG_ 233 AutoCoPAxlTrqCmnd2ARC "Autonomous CoPilot Axle Torque Command 2 Alive Rolling Count";
BA_ "VNSigAllNodes" SG_ 233 AutoCoPAxlTrqCmnd2ARC 1;
BA_ "SignalType" SG_ 347 EBstRnotPrsQlfr "ENM";
BA_ "SignalLongName" SG_ 347 EBstRnotPrsQlfr "Eboost Runout Pressure Qualifier";
BA_ "VNSigAllNodes" SG_ 347 EBstRnotPrsQlfr 1;
BA_ "SignalType" SG_ 347 EBstRnotPrs "UNM";
BA_ "SignalLongName" SG_ 347 EBstRnotPrs "Eboost Runout Pressure";
BA_ "VNSigAllNodes" SG_ 347 EBstRnotPrs 1;
BA_ "SignalType" SG_ 347 BrkPedApdQlfr "ENM";
BA_ "SignalLongName" SG_ 347 BrkPedApdQlfr "Brake Pedal Applied Qualifier";
BA_ "VNSigAllNodes" SG_ 347 BrkPedApdQlfr 1;
BA_ "SignalType" SG_ 347 BrkPedApd "BLN";
BA_ "SignalLongName" SG_ 347 BrkPedApd "Brake Pedal Applied";
BA_ "VNSigAllNodes" SG_ 347 BrkPedApd 1;
BA_ "SignalType" SG_ 347 SecBrkModStatRed "ENM";
BA_ "SignalLongName" SG_ 347 SecBrkModStatRed "Secondary Brake Module Status Redundant";
BA_ "VNSigAllNodes" SG_ 347 SecBrkModStatRed 1;
BA_ "SignalType" SG_ 347 SecAutoEstBrkTrqAppStatRed "ENM";
BA_ "SignalLongName" SG_ 347 SecAutoEstBrkTrqAppStatRed "Secondary Autonomous Estimated Brake Torque Applied Status Redundant";
BA_ "VNSigAllNodes" SG_ 347 SecAutoEstBrkTrqAppStatRed 1;
BA_ "SignalType" SG_ 347 SecAutoEstBrkTrqApdRed "UNM";
BA_ "SignalLongName" SG_ 347 SecAutoEstBrkTrqApdRed "Secondary Autonomous Estimated Brake Torque Applied Redundant";
BA_ "GenSigStartValue" SG_ 347 SecAutoEstBrkTrqApdRed 32767;
BA_ "VNSigAllNodes" SG_ 347 SecAutoEstBrkTrqApdRed 1;
BA_ "SignalType" SG_ 347 SecAutoBrkSysDrInfcStatRed "ENM";
BA_ "SignalLongName" SG_ 347 SecAutoBrkSysDrInfcStatRed "Secondary Autonomous Brake System Driver Interference Detected Status Redundant";
BA_ "VNSigAllNodes" SG_ 347 SecAutoBrkSysDrInfcStatRed 1;
BA_ "SignalType" SG_ 347 SecAutoAxlTrqReqStatRedChksm "UNM";
BA_ "SignalLongName" SG_ 347 SecAutoAxlTrqReqStatRedChksm "Secondary Autonomous Axle Torque Request Status Redundant Checksum";
BA_ "VNSigAllNodes" SG_ 347 SecAutoAxlTrqReqStatRedChksm 1;
BA_ "SignalType" SG_ 347 SecAutoAxlTrqReqStatRedARC "UNM";
BA_ "SignalLongName" SG_ 347 SecAutoAxlTrqReqStatRedARC "Secondary Autonomous Axle Torque Request Status Redundant Alive Rolling Count";
BA_ "VNSigAllNodes" SG_ 347 SecAutoAxlTrqReqStatRedARC 1;
BA_ "SignalType" SG_ 347 SecAutoArbBrkTrqReqRed "UNM";
BA_ "SignalLongName" SG_ 347 SecAutoArbBrkTrqReqRed "Secondary Automomous Arbitrated Brake Torque Request Redundant";
BA_ "GenSigStartValue" SG_ 347 SecAutoArbBrkTrqReqRed 32767;
BA_ "VNSigAllNodes" SG_ 347 SecAutoArbBrkTrqReqRed 1;
BA_ "SignalType" SG_ 479 EngAutoStpNotProb "BLN";
BA_ "SignalLongName" SG_ 479 EngAutoStpNotProb "Engine Auto Stop Not Probable";
BA_ "VNSigAllNodes" SG_ 479 EngAutoStpNotProb 1;
BA_ "SignalType" SG_ 479 EASSI_UnsdRsrvd2 "BLN";
BA_ "PacketOrder" SG_ 479 EASSI_UnsdRsrvd2 7;
BA_ "SignalLongName" SG_ 479 EASSI_UnsdRsrvd2 "Engine Auto Start Stop Information : Unused and Reserved 2";
BA_ "VNSigAllNodes" SG_ 479 EASSI_UnsdRsrvd2 1;
BA_ "SignalType" SG_ 479 EASSI_StlDetd "BLN";
BA_ "PacketOrder" SG_ 479 EASSI_StlDetd 5;
BA_ "SignalLongName" SG_ 479 EASSI_StlDetd "Engine Auto Start Stop Information : Stall Detected";
BA_ "VNSigAllNodes" SG_ 479 EASSI_StlDetd 1;
BA_ "SignalType" SG_ 479 EASSI_TrqDetd "BLN";
BA_ "PacketOrder" SG_ 479 EASSI_TrqDetd 4;
BA_ "SignalLongName" SG_ 479 EASSI_TrqDetd "Engine Auto Start Stop Information : Torque Detected";
BA_ "VNSigAllNodes" SG_ 479 EASSI_TrqDetd 1;
BA_ "SignalType" SG_ 479 EASSI_FuelReqOn "BLN";
BA_ "PacketOrder" SG_ 479 EASSI_FuelReqOn 3;
BA_ "SignalLongName" SG_ 479 EASSI_FuelReqOn "Engine Auto Start Stop Information : Fuel Requested On";
BA_ "VNSigAllNodes" SG_ 479 EASSI_FuelReqOn 1;
BA_ "SignalType" SG_ 479 EASSI_StrtTyp "ENM";
BA_ "PacketOrder" SG_ 479 EASSI_StrtTyp 2;
BA_ "SignalLongName" SG_ 479 EASSI_StrtTyp "Engine Auto Start Stop Information : Start Type";
BA_ "VNSigAllNodes" SG_ 479 EASSI_StrtTyp 1;
BA_ "SignalType" SG_ 479 EASSI_StrtStpSt "ENM";
BA_ "PacketOrder" SG_ 479 EASSI_StrtStpSt 1;
BA_ "SignalLongName" SG_ 479 EASSI_StrtStpSt "Engine Auto Start Stop Information : Start Stop State";
BA_ "VNSigAllNodes" SG_ 479 EASSI_StrtStpSt 1;
BA_ "SignalType" SG_ 479 EASSI_TorqDetdIndet "BLN";
BA_ "PacketOrder" SG_ 479 EASSI_TorqDetdIndet 6;
BA_ "SignalLongName" SG_ 479 EASSI_TorqDetdIndet "Engine Auto Start Stop Information : Torque Detected Indeterminate";
BA_ "VNSigAllNodes" SG_ 479 EASSI_TorqDetdIndet 1;
BA_ "SignalType" SG_ 479 ASIRI_Indication08 "BLN";
BA_ "PacketOrder" SG_ 479 ASIRI_Indication08 8;
BA_ "SignalLongName" SG_ 479 ASIRI_Indication08 "Auto Stop Inhibit Reason Indication : Indication 8";
BA_ "VNSigAllNodes" SG_ 479 ASIRI_Indication08 1;
BA_ "SignalType" SG_ 479 ASIRI_Indication07 "BLN";
BA_ "PacketOrder" SG_ 479 ASIRI_Indication07 7;
BA_ "SignalLongName" SG_ 479 ASIRI_Indication07 "Auto Stop Inhibit Reason Indication : Indication 7";
BA_ "VNSigAllNodes" SG_ 479 ASIRI_Indication07 1;
BA_ "SignalType" SG_ 479 ASIRI_Indication06 "BLN";
BA_ "PacketOrder" SG_ 479 ASIRI_Indication06 6;
BA_ "SignalLongName" SG_ 479 ASIRI_Indication06 "Auto Stop Inhibit Reason Indication : Indication 6";
BA_ "VNSigAllNodes" SG_ 479 ASIRI_Indication06 1;
BA_ "SignalType" SG_ 479 ASIRI_Indication05 "BLN";
BA_ "PacketOrder" SG_ 479 ASIRI_Indication05 5;
BA_ "SignalLongName" SG_ 479 ASIRI_Indication05 "Auto Stop Inhibit Reason Indication : Indication 5";
BA_ "VNSigAllNodes" SG_ 479 ASIRI_Indication05 1;
BA_ "SignalType" SG_ 479 ASIRI_Indication04 "BLN";
BA_ "PacketOrder" SG_ 479 ASIRI_Indication04 4;
BA_ "SignalLongName" SG_ 479 ASIRI_Indication04 "Auto Stop Inhibit Reason Indication : Indication 4";
BA_ "VNSigAllNodes" SG_ 479 ASIRI_Indication04 1;
BA_ "SignalType" SG_ 479 ASIRI_Indication03 "BLN";
BA_ "PacketOrder" SG_ 479 ASIRI_Indication03 3;
BA_ "SignalLongName" SG_ 479 ASIRI_Indication03 "Auto Stop Inhibit Reason Indication : Indication 3";
BA_ "VNSigAllNodes" SG_ 479 ASIRI_Indication03 1;
BA_ "SignalType" SG_ 479 ASIRI_Indication02 "BLN";
BA_ "PacketOrder" SG_ 479 ASIRI_Indication02 2;
BA_ "SignalLongName" SG_ 479 ASIRI_Indication02 "Auto Stop Inhibit Reason Indication : Indication 2";
BA_ "VNSigAllNodes" SG_ 479 ASIRI_Indication02 1;
BA_ "SignalType" SG_ 479 ASIRI_Indication01 "BLN";
BA_ "PacketOrder" SG_ 479 ASIRI_Indication01 1;
BA_ "SignalLongName" SG_ 479 ASIRI_Indication01 "Auto Stop Inhibit Reason Indication : Indication 1";
BA_ "VNSigAllNodes" SG_ 479 ASIRI_Indication01 1;
BA_ "SignalType" SG_ 479 PTWrmgWtToShftIO "BLN";
BA_ "SignalLongName" SG_ 479 PTWrmgWtToShftIO "Powertrain Warming Wait To Shift Indication On";
BA_ "VNSigAllNodes" SG_ 479 PTWrmgWtToShftIO 1;
BA_ "SignalType" SG_ 479 PrplsnSysAtv "BLN";
BA_ "SignalLongName" SG_ 479 PrplsnSysAtv "Propulsion System Active";
BA_ "VNSigAllNodes" SG_ 479 PrplsnSysAtv 1;
BA_ "SignalType" SG_ 479 PTShftLvrLckRqd "BLN";
BA_ "SignalLongName" SG_ 479 PTShftLvrLckRqd "Powertrain Shift Lever Lock Requested";
BA_ "VNSigAllNodes" SG_ 479 PTShftLvrLckRqd 1;
BA_ "SignalType" SG_ 452 FSpRgACCSwADdPVal "UNM";
BA_ "SignalLongName" SG_ 452 FSpRgACCSwADdPVal "Full Speed Range ACC Cruise Switch Action Detected Protection Value";
BA_ "VNSigAllNodes" SG_ 452 FSpRgACCSwADdPVal 1;
BA_ "SignalType" SG_ 452 FSpRgACCSwADdARC "UNM";
BA_ "SignalLongName" SG_ 452 FSpRgACCSwADdARC "Full Speed Range ACC Cruise Switch Action Detected Alive Rolling Count";
BA_ "VNSigAllNodes" SG_ 452 FSpRgACCSwADdARC 1;
BA_ "SignalType" SG_ 452 FSpRgACCSwADd "BLN";
BA_ "SignalLongName" SG_ 452 FSpRgACCSwADd "Full Speed Range ACC Cruise Switch Action Detected";
BA_ "VNSigAllNodes" SG_ 452 FSpRgACCSwADd 1;
BA_ "SignalType" SG_ 452 AutBrkAccActPsStRC "UNM";
BA_ "SignalLongName" SG_ 452 AutBrkAccActPsStRC "Autonomous Braking Accelerator Actual Position Status Rolling Count";
BA_ "VNSigAllNodes" SG_ 452 AutBrkAccActPsStRC 1;
BA_ "SignalType" SG_ 452 AutBrkAccActPsStPVal "UNM";
BA_ "SignalLongName" SG_ 452 AutBrkAccActPsStPVal "Autonomous Braking Accelerator Actual Position Status Protection Value";
BA_ "VNSigAllNodes" SG_ 452 AutBrkAccActPsStPVal 1;
BA_ "SignalType" SG_ 452 ABAAPS_AccPos "UNM";
BA_ "PacketOrder" SG_ 452 ABAAPS_AccPos 2;
BA_ "SignalLongName" SG_ 452 ABAAPS_AccPos "Autonomous Braking Accelerator Actual Position Status : Accelerator Position";
BA_ "VNSigAllNodes" SG_ 452 ABAAPS_AccPos 1;
BA_ "SignalType" SG_ 452 ABAAPS_AccPosV "ENM";
BA_ "PacketOrder" SG_ 452 ABAAPS_AccPosV 1;
BA_ "SignalLongName" SG_ 452 ABAAPS_AccPosV "Autonomous Braking Accelerator Actual Position Status : Accelerator Position Validity";
BA_ "VNSigAllNodes" SG_ 452 ABAAPS_AccPosV 1;
BA_ "SignalType" SG_ 452 ACCATCS_LmtgStat "ENM";
BA_ "PacketOrder" SG_ 452 ACCATCS_LmtgStat 2;
BA_ "SignalLongName" SG_ 452 ACCATCS_LmtgStat "Adaptive Cruise Control Axle Torque Command Status : Limiting Status";
BA_ "VNSigAllNodes" SG_ 452 ACCATCS_LmtgStat 1;
BA_ "SignalType" SG_ 452 ACCATCS_RqStat "ENM";
BA_ "PacketOrder" SG_ 452 ACCATCS_RqStat 1;
BA_ "SignalLongName" SG_ 452 ACCATCS_RqStat "Adaptive Cruise Control Axle Torque Command Status : Request Status";
BA_ "VNSigAllNodes" SG_ 452 ACCATCS_RqStat 1;
BA_ "SignalType" SG_ 452 RdLdNomAxlTrq "UNM";
BA_ "SignalLongName" SG_ 452 RdLdNomAxlTrq "Road Load Nominal Axle Torque";
BA_ "VNSigAllNodes" SG_ 452 RdLdNomAxlTrq 1;
BA_ "SignalType" SG_ 452 AccPdlOvrrdAtvProtVal "UNM";
BA_ "SignalLongName" SG_ 452 AccPdlOvrrdAtvProtVal "Accelerator Pedal Override Active Protection Value";
BA_ "VNSigAllNodes" SG_ 452 AccPdlOvrrdAtvProtVal 1;
BA_ "SignalType" SG_ 452 AccPdlOvrrdAtvARC "UNM";
BA_ "SignalLongName" SG_ 452 AccPdlOvrrdAtvARC "Accelerator Pedal Override Active Alive Rolling Count";
BA_ "VNSigAllNodes" SG_ 452 AccPdlOvrrdAtvARC 1;
BA_ "SignalType" SG_ 452 AccPdlOvrrdAtv "BLN";
BA_ "SignalLongName" SG_ 452 AccPdlOvrrdAtv "Accelerator Pedal Override Active";
BA_ "VNSigAllNodes" SG_ 452 AccPdlOvrrdAtv 1;
BA_ "SignalType" SG_ 452 CPSATCS_ReqStatus "ENM";
BA_ "PacketOrder" SG_ 452 CPSATCS_ReqStatus 2;
BA_ "SignalLongName" SG_ 452 CPSATCS_ReqStatus "Collision Preparation System Axle Torque Command Status : Request Status";
BA_ "VNSigAllNodes" SG_ 452 CPSATCS_ReqStatus 1;
BA_ "SignalType" SG_ 452 CPSATCS_LmtngStatus "ENM";
BA_ "PacketOrder" SG_ 452 CPSATCS_LmtngStatus 1;
BA_ "SignalLongName" SG_ 452 CPSATCS_LmtngStatus "Collision Preparation System Axle Torque Command Status : Limiting Status";
BA_ "VNSigAllNodes" SG_ 452 CPSATCS_LmtngStatus 1;
BA_ "SignalType" SG_ 452 RVBATCS_ReqStat "ENM";
BA_ "PacketOrder" SG_ 452 RVBATCS_ReqStat 2;
BA_ "SignalLongName" SG_ 452 RVBATCS_ReqStat "Rear Virtual Bumper Axle Torque Command Status : Request Status";
BA_ "VNSigAllNodes" SG_ 452 RVBATCS_ReqStat 1;
BA_ "SignalType" SG_ 452 RVBATCS_LmtngStat "ENM";
BA_ "PacketOrder" SG_ 452 RVBATCS_LmtngStat 1;
BA_ "SignalLongName" SG_ 452 RVBATCS_LmtngStat "Rear Virtual Bumper Axle Torque Command Status : Limiting Status";
BA_ "VNSigAllNodes" SG_ 452 RVBATCS_LmtngStat 1;
BA_ "SignalType" SG_ 298 DrvrDrAjrSwVDA "ENM";
BA_ "SignalLongName" SG_ 298 DrvrDrAjrSwVDA "Driver Door Ajar Switch Virtual Device Availability";
BA_ "VNSigAllNodes" SG_ 298 DrvrDrAjrSwVDA 1;
BA_ "SignalType" SG_ 298 ValetMdAct "BLN";
BA_ "SignalLongName" SG_ 298 ValetMdAct "Valet Mode Active";
BA_ "VNSigAllNodes" SG_ 298 ValetMdAct 1;
BA_ "SignalType" SG_ 298 AutoMdSpdLmtCnfrmd "BLN";
BA_ "SignalLongName" SG_ 298 AutoMdSpdLmtCnfrmd "Auto Mode Speed Limit Confirmed";
BA_ "VNSigAllNodes" SG_ 298 AutoMdSpdLmtCnfrmd 1;
BA_ "SignalType" SG_ 298 TCSysDisSwAtvARC "UNM";
BA_ "SignalLongName" SG_ 298 TCSysDisSwAtvARC "Traction Control System Disable Switch Active Alive Rolling Count";
BA_ "VNSigAllNodes" SG_ 298 TCSysDisSwAtvARC 1;
BA_ "SignalType" SG_ 298 TCSysDisSwAtv_12A "BLN";
BA_ "SignalLongName" SG_ 298 TCSysDisSwAtv_12A "Traction Control System Disable Switch Active";
BA_ "VNSigAllNodes" SG_ 298 TCSysDisSwAtv_12A 1;
BA_ "SignalType" SG_ 298 ChmAct "BLN";
BA_ "SignalLongName" SG_ 298 ChmAct "Chime Active";
BA_ "VNSigAllNodes" SG_ 298 ChmAct 1;
BA_ "SignalType" SG_ 298 Ky_IdDevPr "BLN";
BA_ "SignalLongName" SG_ 298 Ky_IdDevPr "Key / Identification Device Present";
BA_ "VNSigAllNodes" SG_ 298 Ky_IdDevPr 1;
BA_ "SignalType" SG_ 298 DDAjrSwAtvM "ENM";
BA_ "SignalLongName" SG_ 298 DDAjrSwAtvM "Driver Door Ajar Switch Active Mask";
BA_ "VNSigAllNodes" SG_ 298 DDAjrSwAtvM 1;
BA_ "SignalType" SG_ 298 PsSbltAtcV "ENM";
BA_ "SignalLongName" SG_ 298 PsSbltAtcV "Passenger Seatbelt Attached Validity";
BA_ "VNSigAllNodes" SG_ 298 PsSbltAtcV 1;
BA_ "SignalType" SG_ 298 PsSbltAtc "BLN";
BA_ "SignalLongName" SG_ 298 PsSbltAtc "Passenger Seatbelt Attached";
BA_ "VNSigAllNodes" SG_ 298 PsSbltAtc 1;
BA_ "SignalType" SG_ 298 TrlrBrkDsplyAct "BLN";
BA_ "SignalLongName" SG_ 298 TrlrBrkDsplyAct "Trailer Brake Display Active";
BA_ "VNSigAllNodes" SG_ 298 TrlrBrkDsplyAct 1;
BA_ "SignalType" SG_ 298 RdSpdCatType "ENM";
BA_ "SignalLongName" SG_ 298 RdSpdCatType "Road Speed Category Type";
BA_ "VNSigAllNodes" SG_ 298 RdSpdCatType 1;
BA_ "SignalType" SG_ 298 LnCat "ENM";
BA_ "SignalLongName" SG_ 298 LnCat "Lane Category";
BA_ "VNSigAllNodes" SG_ 298 LnCat 1;
BA_ "SignalType" SG_ 298 FncRdClass "ENM";
BA_ "SignalLongName" SG_ 298 FncRdClass "Functional Road Class";
BA_ "VNSigAllNodes" SG_ 298 FncRdClass 1;
BA_ "SignalType" SG_ 298 SprtLnRd "BLN";
BA_ "SignalLongName" SG_ 298 SprtLnRd "Separate Lane Road";
BA_ "VNSigAllNodes" SG_ 298 SprtLnRd 1;
BA_ "SignalType" SG_ 298 CntrldAccRd "BLN";
BA_ "SignalLongName" SG_ 298 CntrldAccRd "Controlled Access Road";
BA_ "VNSigAllNodes" SG_ 298 CntrldAccRd 1;
BA_ "SignalType" SG_ 298 BldUpArDet "BLN";
BA_ "SignalLongName" SG_ 298 BldUpArDet "Build Up Area Detected";
BA_ "VNSigAllNodes" SG_ 298 BldUpArDet 1;
BA_ "SignalType" SG_ 298 MpDataAvlbl "BLN";
BA_ "SignalLongName" SG_ 298 MpDataAvlbl "Map Data Available";
BA_ "VNSigAllNodes" SG_ 298 MpDataAvlbl 1;
BA_ "SignalType" SG_ 298 SusCustStngReq "ENM";
BA_ "SignalLongName" SG_ 298 SusCustStngReq "Suspension Customization Setting Request";
BA_ "VNSigAllNodes" SG_ 298 SusCustStngReq 1;
BA_ "SignalType" SG_ 298 StrCustStngReq "ENM";
BA_ "SignalLongName" SG_ 298 StrCustStngReq "Steering Customization Setting Request";
BA_ "VNSigAllNodes" SG_ 298 StrCustStngReq 1;
BA_ "SignalType" SG_ 298 RstrCustFctrDef "ENM";
BA_ "SignalLongName" SG_ 298 RstrCustFctrDef "Restore Customization Factory Defaults";
BA_ "VNSigAllNodes" SG_ 298 RstrCustFctrDef 1;
BA_ "SignalType" SG_ 298 DrvlnCustStngReq "ENM";
BA_ "SignalLongName" SG_ 298 DrvlnCustStngReq "Driveline Customization Setting Request";
BA_ "VNSigAllNodes" SG_ 298 DrvlnCustStngReq 1;
BA_ "SignalType" SG_ 298 ChmMstrVDA "ENM";
BA_ "SignalLongName" SG_ 298 ChmMstrVDA "Chime Master Virtual Device Availability";
BA_ "GenSigStartValue" SG_ 298 ChmMstrVDA 1;
BA_ "VNSigAllNodes" SG_ 298 ChmMstrVDA 1;
BA_ "SignalType" SG_ 298 IPCVDA "ENM";
BA_ "SignalLongName" SG_ 298 IPCVDA "Instrument Panel Cluster Virtual Device Availability";
BA_ "GenSigStartValue" SG_ 298 IPCVDA 1;
BA_ "VNSigAllNodes" SG_ 298 IPCVDA 1;
BA_ "SignalType" SG_ 298 HeadUpDispVDA "ENM";
BA_ "SignalLongName" SG_ 298 HeadUpDispVDA "Head Up Display Virtual Device Availability";
BA_ "GenSigStartValue" SG_ 298 HeadUpDispVDA 1;
BA_ "VNSigAllNodes" SG_ 298 HeadUpDispVDA 1;
BA_ "SignalType" SG_ 298 HapticSeatVDA "ENM";
BA_ "SignalLongName" SG_ 298 HapticSeatVDA "Haptic Seat Virtual Device Availability";
BA_ "GenSigStartValue" SG_ 298 HapticSeatVDA 1;
BA_ "VNSigAllNodes" SG_ 298 HapticSeatVDA 1;
BA_ "SignalType" SG_ 298 RRDoorAjarSwAct "BLN";
BA_ "SignalLongName" SG_ 298 RRDoorAjarSwAct "Rear Right Door Ajar Switch Active";
BA_ "VNSigAllNodes" SG_ 298 RRDoorAjarSwAct 1;
BA_ "SignalType" SG_ 298 PDAjrSwAtv "BLN";
BA_ "SignalLongName" SG_ 298 PDAjrSwAtv "Passenger Door Ajar Switch Active";
BA_ "VNSigAllNodes" SG_ 298 PDAjrSwAtv 1;
BA_ "SignalType" SG_ 298 DDAjrSwAtv "BLN";
BA_ "SignalLongName" SG_ 298 DDAjrSwAtv "Driver Door Ajar Switch Active";
BA_ "VNSigAllNodes" SG_ 298 DDAjrSwAtv 1;
BA_ "SignalType" SG_ 298 TrlrHWIntrfcVDA "ENM";
BA_ "SignalLongName" SG_ 298 TrlrHWIntrfcVDA "Trailer Hardware Interface Virtual Device Availability";
BA_ "GenSigStartValue" SG_ 298 TrlrHWIntrfcVDA 1;
BA_ "VNSigAllNodes" SG_ 298 TrlrHWIntrfcVDA 1;
BA_ "SignalType" SG_ 298 DrId "ENM";
BA_ "SignalLongName" SG_ 298 DrId "Driver Identifier";
BA_ "GenSigStartValue" SG_ 298 DrId 7;
BA_ "VNSigAllNodes" SG_ 298 DrId 1;
BA_ "SignalType" SG_ 298 EnrgMgtLdShdRq "ENM";
BA_ "SignalLongName" SG_ 298 EnrgMgtLdShdRq "Energy Management Load Shedding Request";
BA_ "VNSigAllNodes" SG_ 298 EnrgMgtLdShdRq 1;
BA_ "SignalType" SG_ 298 DrSbltAtcV "ENM";
BA_ "SignalLongName" SG_ 298 DrSbltAtcV "Driver Seatbelt Attached Validity";
BA_ "VNSigAllNodes" SG_ 298 DrSbltAtcV 1;
BA_ "SignalType" SG_ 298 TrlrHtchSwAtv "BLN";
BA_ "SignalLongName" SG_ 298 TrlrHtchSwAtv "Trailer Hitch Switch Active";
BA_ "VNSigAllNodes" SG_ 298 TrlrHtchSwAtv 1;
BA_ "SignalType" SG_ 298 TreInfMonSysRstReq "BLN";
BA_ "SignalLongName" SG_ 298 TreInfMonSysRstReq "Tire Inflation Monitoring System Reset Requested";
BA_ "VNSigAllNodes" SG_ 298 TreInfMonSysRstReq 1;
BA_ "SignalType" SG_ 298 HUDActv "BLN";
BA_ "SignalLongName" SG_ 298 HUDActv "Head Up Display Active";
BA_ "VNSigAllNodes" SG_ 298 HUDActv 1;
BA_ "SignalType" SG_ 298 BatVltV "ENM";
BA_ "SignalLongName" SG_ 298 BatVltV "Battery Voltage Validity";
BA_ "VNSigAllNodes" SG_ 298 BatVltV 1;
BA_ "SignalType" SG_ 298 BatVlt "UNM";
BA_ "SignalLongName" SG_ 298 BatVlt "Battery Voltage";
BA_ "VNSigAllNodes" SG_ 298 BatVlt 1;
BA_ "SignalType" SG_ 298 RLDoorAjarSwAct "BLN";
BA_ "SignalLongName" SG_ 298 RLDoorAjarSwAct "Rear Left Door Ajar Switch Active";
BA_ "VNSigAllNodes" SG_ 298 RLDoorAjarSwAct 1;
BA_ "SignalType" SG_ 298 DrSbltAtc "BLN";
BA_ "SignalLongName" SG_ 298 DrSbltAtc "Driver Seatbelt Attached";
BA_ "VNSigAllNodes" SG_ 298 DrSbltAtc 1;
BA_ "VNSigSLHSSharedDiagnostic" SG_ 1366 DgnInf_HS556 1;
BA_ "SignalType" SG_ 1366 DgnInf_HS556 "UNM";
BA_ "SignalLongName" SG_ 1366 DgnInf_HS556 "Diagnostic Information HS556";
BA_ "VNSigAllNodes" SG_ 1366 DgnInf_HS556 1;
BA_REL_ "GenSigVBitResp" BU_SG_REL_ EBCM_PHS SG_ 453 DrvIntndAxlTrq 1;
BA_REL_ "GenSigSuprvResp" BU_SG_REL_ EBCM_PHS SG_ 453 DrvIntndAxlTrq 1;
BA_REL_ "GenSigTimeoutMsg" BU_SG_REL_ EBCM_PHS SG_ 453 DrvIntndAxlTrq 453;
BA_REL_ "GenSigTimeoutTime" BU_SG_REL_ EBCM_PHS SG_ 453 DrvIntndAxlTrq 250;
BA_REL_ "GenSigSuprvResp" BU_SG_REL_ EBCM_PHS SG_ 463 SecAxlOperMod 1;
BA_REL_ "GenSigTimeoutMsg" BU_SG_REL_ EBCM_PHS SG_ 463 SecAxlOperMod 463;
BA_REL_ "GenSigTimeoutTime" BU_SG_REL_ EBCM_PHS SG_ 463 SecAxlOperMod 500;
BA_REL_ "GenSigSuprvResp" BU_SG_REL_ EBCM_PHS SG_ 463 SecAxlOperMod 1;
BA_REL_ "GenSigTimeoutMsg" BU_SG_REL_ EBCM_PHS SG_ 463 SecAxlOperMod 463;
BA_REL_ "GenSigTimeoutTime" BU_SG_REL_ EBCM_PHS SG_ 463 SecAxlOperMod 500;
BA_REL_ "GenSigSuprvResp" BU_SG_REL_ EBCM_PHS SG_ 707 CSTATRS_ReqStat 1;
BA_REL_ "GenSigTimeoutMsg" BU_SG_REL_ EBCM_PHS SG_ 707 CSTATRS_ReqStat 707;
BA_REL_ "GenSigTimeoutTime" BU_SG_REL_ EBCM_PHS SG_ 707 CSTATRS_ReqStat 250;
BA_REL_ "GenSigSuprvResp" BU_SG_REL_ EBCM_PHS SG_ 707 CSTATRS_LmtgStat 1;
BA_REL_ "GenSigTimeoutMsg" BU_SG_REL_ EBCM_PHS SG_ 707 CSTATRS_LmtgStat 707;
BA_REL_ "GenSigTimeoutTime" BU_SG_REL_ EBCM_PHS SG_ 707 CSTATRS_LmtgStat 250;
BA_REL_ "GenSigVBitResp" BU_SG_REL_ EBCM_PHS SG_ 707 EngManfldAbsPrs 1;
BA_REL_ "GenSigSuprvResp" BU_SG_REL_ EBCM_PHS SG_ 707 EngManfldAbsPrs 1;
BA_REL_ "GenSigTimeoutMsg" BU_SG_REL_ EBCM_PHS SG_ 707 EngManfldAbsPrs 707;
BA_REL_ "GenSigTimeoutTime" BU_SG_REL_ EBCM_PHS SG_ 707 EngManfldAbsPrs 250;
BA_REL_ "GenSigSuprvResp" BU_SG_REL_ EBCM_PHS SG_ 707 EngTrqMinExtRng 1;
BA_REL_ "GenSigTimeoutMsg" BU_SG_REL_ EBCM_PHS SG_ 707 EngTrqMinExtRng 707;
BA_REL_ "GenSigTimeoutTime" BU_SG_REL_ EBCM_PHS SG_ 707 EngTrqMinExtRng 250;
BA_REL_ "GenSigSuprvResp" BU_SG_REL_ EBCM_PHS SG_ 707 EngTrqMaxExtRng 1;
BA_REL_ "GenSigTimeoutMsg" BU_SG_REL_ EBCM_PHS SG_ 707 EngTrqMaxExtRng 707;
BA_REL_ "GenSigTimeoutTime" BU_SG_REL_ EBCM_PHS SG_ 707 EngTrqMaxExtRng 250;
BA_REL_ "GenSigSuprvResp" BU_SG_REL_ EBCM_PHS SG_ 451 HillDscntCtrlSwStat 1;
BA_REL_ "GenSigTimeoutMsg" BU_SG_REL_ EBCM_PHS SG_ 451 HillDscntCtrlSwStat 451;
BA_REL_ "GenSigTimeoutTime" BU_SG_REL_ EBCM_PHS SG_ 451 HillDscntCtrlSwStat 250;
BA_REL_ "GenSigVBitResp" BU_SG_REL_ EBCM_PHS SG_ 451 AccPos 1;
BA_REL_ "GenSigSuprvResp" BU_SG_REL_ EBCM_PHS SG_ 451 AccPos 1;
BA_REL_ "GenSigTimeoutMsg" BU_SG_REL_ EBCM_PHS SG_ 451 AccPos 451;
BA_REL_ "GenSigTimeoutTime" BU_SG_REL_ EBCM_PHS SG_ 451 AccPos 250;
BA_REL_ "GenSigSuprvResp" BU_SG_REL_ EBCM_PHS SG_ 451 EngTrqRdFlrSt 1;
BA_REL_ "GenSigTimeoutMsg" BU_SG_REL_ EBCM_PHS SG_ 451 EngTrqRdFlrSt 451;
BA_REL_ "GenSigTimeoutTime" BU_SG_REL_ EBCM_PHS SG_ 451 EngTrqRdFlrSt 250;
BA_REL_ "GenSigVBitResp" BU_SG_REL_ EBCM_PHS SG_ 451 EngTrqDrRqdExtRng 1;
BA_REL_ "GenSigSuprvResp" BU_SG_REL_ EBCM_PHS SG_ 451 EngTrqDrRqdExtRng 1;
BA_REL_ "GenSigTimeoutMsg" BU_SG_REL_ EBCM_PHS SG_ 451 EngTrqDrRqdExtRng 451;
BA_REL_ "GenSigTimeoutTime" BU_SG_REL_ EBCM_PHS SG_ 451 EngTrqDrRqdExtRng 250;
BA_REL_ "GenSigVBitResp" BU_SG_REL_ EBCM_PHS SG_ 451 EngTrqActExtRng 1;
BA_REL_ "GenSigSuprvResp" BU_SG_REL_ EBCM_PHS SG_ 451 EngTrqActExtRng 1;
BA_REL_ "GenSigTimeoutMsg" BU_SG_REL_ EBCM_PHS SG_ 451 EngTrqActExtRng 451;
BA_REL_ "GenSigTimeoutTime" BU_SG_REL_ EBCM_PHS SG_ 451 EngTrqActExtRng 250;
BA_REL_ "GenSigSuprvResp" BU_SG_REL_ EBCM_PHS SG_ 241 BrkAppSnsrHmPosLrnd 1;
BA_REL_ "GenSigTimeoutMsg" BU_SG_REL_ EBCM_PHS SG_ 241 BrkAppSnsrHmPosLrnd 241;
BA_REL_ "GenSigTimeoutTime" BU_SG_REL_ EBCM_PHS SG_ 241 BrkAppSnsrHmPosLrnd 250;
BA_REL_ "GenSigSuprvResp" BU_SG_REL_ EBCM_PHS SG_ 241 BrkAppSnsrHmPosLrnd 1;
BA_REL_ "GenSigTimeoutMsg" BU_SG_REL_ EBCM_PHS SG_ 241 BrkAppSnsrHmPosLrnd 241;
BA_REL_ "GenSigTimeoutTime" BU_SG_REL_ EBCM_PHS SG_ 241 BrkAppSnsrHmPosLrnd 250;
BA_REL_ "GenSigSuprvResp" BU_SG_REL_ EBCM_PHS SG_ 241 BrkAppSnsrHmPosLrnd 1;
BA_REL_ "GenSigTimeoutMsg" BU_SG_REL_ EBCM_PHS SG_ 241 BrkAppSnsrHmPosLrnd 241;
BA_REL_ "GenSigTimeoutTime" BU_SG_REL_ EBCM_PHS SG_ 241 BrkAppSnsrHmPosLrnd 250;
BA_REL_ "GenSigSuprvResp" BU_SG_REL_ EBCM_PHS SG_ 241 BrkPedTrvlAchvd 1;
BA_REL_ "GenSigTimeoutMsg" BU_SG_REL_ EBCM_PHS SG_ 241 BrkPedTrvlAchvd 241;
BA_REL_ "GenSigTimeoutTime" BU_SG_REL_ EBCM_PHS SG_ 241 BrkPedTrvlAchvd 250;
BA_REL_ "GenSigSuprvResp" BU_SG_REL_ EBCM_PHS SG_ 241 BrkPedTrvlAchvd 1;
BA_REL_ "GenSigTimeoutMsg" BU_SG_REL_ EBCM_PHS SG_ 241 BrkPedTrvlAchvd 241;
BA_REL_ "GenSigTimeoutTime" BU_SG_REL_ EBCM_PHS SG_ 241 BrkPedTrvlAchvd 250;
BA_REL_ "GenSigSuprvResp" BU_SG_REL_ EBCM_PHS SG_ 241 BrkPedTrvlAchvd 1;
BA_REL_ "GenSigTimeoutMsg" BU_SG_REL_ EBCM_PHS SG_ 241 BrkPedTrvlAchvd 241;
BA_REL_ "GenSigTimeoutTime" BU_SG_REL_ EBCM_PHS SG_ 241 BrkPedTrvlAchvd 250;
BA_REL_ "GenSigSuprvResp" BU_SG_REL_ EBCM_PHS SG_ 241 BrkPedTrvlAchvd 1;
BA_REL_ "GenSigTimeoutMsg" BU_SG_REL_ EBCM_PHS SG_ 241 BrkPedTrvlAchvd 241;
BA_REL_ "GenSigTimeoutTime" BU_SG_REL_ EBCM_PHS SG_ 241 BrkPedTrvlAchvd 250;
BA_REL_ "GenSigSuprvResp" BU_SG_REL_ EBCM_PHS SG_ 241 BrkPedTrvlAchvdV 1;
BA_REL_ "GenSigTimeoutMsg" BU_SG_REL_ EBCM_PHS SG_ 241 BrkPedTrvlAchvdV 241;
BA_REL_ "GenSigTimeoutTime" BU_SG_REL_ EBCM_PHS SG_ 241 BrkPedTrvlAchvdV 250;
BA_REL_ "GenSigSuprvResp" BU_SG_REL_ EBCM_PHS SG_ 241 BrkPedTrvlAchvdV 1;
BA_REL_ "GenSigTimeoutMsg" BU_SG_REL_ EBCM_PHS SG_ 241 BrkPedTrvlAchvdV 241;
BA_REL_ "GenSigTimeoutTime" BU_SG_REL_ EBCM_PHS SG_ 241 BrkPedTrvlAchvdV 250;
BA_REL_ "GenSigSuprvResp" BU_SG_REL_ EBCM_PHS SG_ 241 BrkPedTrvlAchvdV 1;
BA_REL_ "GenSigTimeoutMsg" BU_SG_REL_ EBCM_PHS SG_ 241 BrkPedTrvlAchvdV 241;
BA_REL_ "GenSigTimeoutTime" BU_SG_REL_ EBCM_PHS SG_ 241 BrkPedTrvlAchvdV 250;
BA_REL_ "GenSigSuprvResp" BU_SG_REL_ EBCM_PHS SG_ 241 BrkPedTrvlAchvdV 1;
BA_REL_ "GenSigTimeoutMsg" BU_SG_REL_ EBCM_PHS SG_ 241 BrkPedTrvlAchvdV 241;
BA_REL_ "GenSigTimeoutTime" BU_SG_REL_ EBCM_PHS SG_ 241 BrkPedTrvlAchvdV 250;
BA_REL_ "GenSigSuprvResp" BU_SG_REL_ EBCM_PHS SG_ 241 BrkPdlPosGrad 1;
BA_REL_ "GenSigTimeoutMsg" BU_SG_REL_ EBCM_PHS SG_ 241 BrkPdlPosGrad 241;
BA_REL_ "GenSigTimeoutTime" BU_SG_REL_ EBCM_PHS SG_ 241 BrkPdlPosGrad 250;
BA_REL_ "GenSigSuprvResp" BU_SG_REL_ EBCM_PHS SG_ 241 BrkPdlPos 1;
BA_REL_ "GenSigTimeoutMsg" BU_SG_REL_ EBCM_PHS SG_ 241 BrkPdlPos 241;
BA_REL_ "GenSigTimeoutTime" BU_SG_REL_ EBCM_PHS SG_ 241 BrkPdlPos 250;
BA_REL_ "GenSigSuprvResp" BU_SG_REL_ EBCM_PHS SG_ 241 BrkPdlPos 1;
BA_REL_ "GenSigTimeoutMsg" BU_SG_REL_ EBCM_PHS SG_ 241 BrkPdlPos 241;
BA_REL_ "GenSigTimeoutTime" BU_SG_REL_ EBCM_PHS SG_ 241 BrkPdlPos 250;
BA_REL_ "GenSigSuprvResp" BU_SG_REL_ EBCM_PHS SG_ 241 BrkPdlPos 1;
BA_REL_ "GenSigTimeoutMsg" BU_SG_REL_ EBCM_PHS SG_ 241 BrkPdlPos 241;
BA_REL_ "GenSigTimeoutTime" BU_SG_REL_ EBCM_PHS SG_ 241 BrkPdlPos 250;
BA_REL_ "GenSigSuprvResp" BU_SG_REL_ EBCM_PHS SG_ 241 BrkPdlInTrvPrt 1;
BA_REL_ "GenSigTimeoutMsg" BU_SG_REL_ EBCM_PHS SG_ 241 BrkPdlInTrvPrt 241;
BA_REL_ "GenSigTimeoutTime" BU_SG_REL_ EBCM_PHS SG_ 241 BrkPdlInTrvPrt 250;
BA_REL_ "GenSigSuprvResp" BU_SG_REL_ EBCM_PHS SG_ 241 BrkPdlInTrvPrt 1;
BA_REL_ "GenSigTimeoutMsg" BU_SG_REL_ EBCM_PHS SG_ 241 BrkPdlInTrvPrt 241;
BA_REL_ "GenSigTimeoutTime" BU_SG_REL_ EBCM_PHS SG_ 241 BrkPdlInTrvPrt 250;
BA_REL_ "GenSigSuprvResp" BU_SG_REL_ EBCM_PHS SG_ 241 BrkPdlInTrvPrt 1;
BA_REL_ "GenSigTimeoutMsg" BU_SG_REL_ EBCM_PHS SG_ 241 BrkPdlInTrvPrt 241;
BA_REL_ "GenSigTimeoutTime" BU_SG_REL_ EBCM_PHS SG_ 241 BrkPdlInTrvPrt 250;
BA_REL_ "GenSigVBitResp" BU_SG_REL_ EBCM_PHS SG_ 501 CltchPdlActPos 1;
BA_REL_ "GenSigSuprvResp" BU_SG_REL_ EBCM_PHS SG_ 501 CltchPdlActPos 1;
BA_REL_ "GenSigTimeoutMsg" BU_SG_REL_ EBCM_PHS SG_ 501 CltchPdlActPos 501;
BA_REL_ "GenSigTimeoutTime" BU_SG_REL_ EBCM_PHS SG_ 501 CltchPdlActPos 500;
BA_REL_ "GenSigVBitResp" BU_SG_REL_ EOCM2cp_IMX6_PHS SG_ 501 TrnsEngdState 1;
BA_REL_ "GenSigVBitResp" BU_SG_REL_ EBCM_PHS SG_ 501 TrnsEngdState 1;
BA_REL_ "GenSigSuprvResp" BU_SG_REL_ EBCM_PHS SG_ 501 TrnsEngdState 1;
BA_REL_ "GenSigTimeoutMsg" BU_SG_REL_ EBCM_PHS SG_ 501 TrnsEngdState 501;
BA_REL_ "GenSigTimeoutTime" BU_SG_REL_ EBCM_PHS SG_ 501 TrnsEngdState 500;
BA_REL_ "GenSigSuprvResp" BU_SG_REL_ EBCM_PHS SG_ 501 TransTUDMdStat 1;
BA_REL_ "GenSigTimeoutMsg" BU_SG_REL_ EBCM_PHS SG_ 501 TransTUDMdStat 501;
BA_REL_ "GenSigTimeoutTime" BU_SG_REL_ EBCM_PHS SG_ 501 TransTUDMdStat 500;
BA_REL_ "GenSigSuprvResp" BU_SG_REL_ EBCM_PHS SG_ 501 TrnsSftMdStat 1;
BA_REL_ "GenSigTimeoutMsg" BU_SG_REL_ EBCM_PHS SG_ 501 TrnsSftMdStat 501;
BA_REL_ "GenSigTimeoutTime" BU_SG_REL_ EBCM_PHS SG_ 501 TrnsSftMdStat 500;
BA_REL_ "GenSigVBitResp" BU_SG_REL_ EBCM_PHS SG_ 501 TopTrvlCltchSwAct 1;
BA_REL_ "GenSigSuprvResp" BU_SG_REL_ EBCM_PHS SG_ 501 TopTrvlCltchSwAct 1;
BA_REL_ "GenSigTimeoutMsg" BU_SG_REL_ EBCM_PHS SG_ 501 TopTrvlCltchSwAct 501;
BA_REL_ "GenSigTimeoutTime" BU_SG_REL_ EBCM_PHS SG_ 501 TopTrvlCltchSwAct 500;
BA_REL_ "GenSigSuprvResp" BU_SG_REL_ EBCM_PHS SG_ 501 TrnShftPtrnActStat 1;
BA_REL_ "GenSigTimeoutMsg" BU_SG_REL_ EBCM_PHS SG_ 501 TrnShftPtrnActStat 501;
BA_REL_ "GenSigTimeoutTime" BU_SG_REL_ EBCM_PHS SG_ 501 TrnShftPtrnActStat 500;
BA_REL_ "GenSigVBitResp" BU_SG_REL_ EOCM2cp_IMX6_PHS SG_ 501 TrnsShftLvrPos 1;
BA_REL_ "GenSigVBitResp" BU_SG_REL_ EBCM_PHS SG_ 501 TrnsShftLvrPos 1;
BA_REL_ "GenSigSuprvResp" BU_SG_REL_ EBCM_PHS SG_ 501 TrnsShftLvrPos 1;
BA_REL_ "GenSigTimeoutMsg" BU_SG_REL_ EBCM_PHS SG_ 501 TrnsShftLvrPos 501;
BA_REL_ "GenSigTimeoutTime" BU_SG_REL_ EBCM_PHS SG_ 501 TrnsShftLvrPos 500;
BA_REL_ "GenSigVBitResp" BU_SG_REL_ EBCM_PHS SG_ 501 TrnsShftLvrPos 1;
BA_REL_ "GenSigSuprvResp" BU_SG_REL_ EBCM_PHS SG_ 501 TrnsShftLvrPos 1;
BA_REL_ "GenSigTimeoutMsg" BU_SG_REL_ EBCM_PHS SG_ 501 TrnsShftLvrPos 501;
BA_REL_ "GenSigTimeoutTime" BU_SG_REL_ EBCM_PHS SG_ 501 TrnsShftLvrPos 500;
BA_REL_ "GenSigVBitResp" BU_SG_REL_ EBCM_PHS SG_ 501 TrnsShftLvrPos 1;
BA_REL_ "GenSigSuprvResp" BU_SG_REL_ EBCM_PHS SG_ 501 TrnsShftLvrPos 1;
BA_REL_ "GenSigTimeoutMsg" BU_SG_REL_ EBCM_PHS SG_ 501 TrnsShftLvrPos 501;
BA_REL_ "GenSigTimeoutTime" BU_SG_REL_ EBCM_PHS SG_ 501 TrnsShftLvrPos 500;
BA_REL_ "GenSigSuprvResp" BU_SG_REL_ EBCM_PHS SG_ 501 AutoTransComndGear 1;
BA_REL_ "GenSigTimeoutMsg" BU_SG_REL_ EBCM_PHS SG_ 501 AutoTransComndGear 501;
BA_REL_ "GenSigTimeoutTime" BU_SG_REL_ EBCM_PHS SG_ 501 AutoTransComndGear 500;
BA_REL_ "GenSigSuprvResp" BU_SG_REL_ EBCM_PHS SG_ 501 AutoTransGrSftDirect 1;
BA_REL_ "GenSigTimeoutMsg" BU_SG_REL_ EBCM_PHS SG_ 501 AutoTransGrSftDirect 501;
BA_REL_ "GenSigTimeoutTime" BU_SG_REL_ EBCM_PHS SG_ 501 AutoTransGrSftDirect 500;
BA_REL_ "GenSigVBitResp" BU_SG_REL_ EOCM2cp_IMX6_PHS SG_ 501 TransEstGear 1;
BA_REL_ "GenSigVBitResp" BU_SG_REL_ EBCM_PHS SG_ 501 TransEstGear 1;
BA_REL_ "GenSigSuprvResp" BU_SG_REL_ EBCM_PHS SG_ 501 TransEstGear 1;
BA_REL_ "GenSigTimeoutMsg" BU_SG_REL_ EBCM_PHS SG_ 501 TransEstGear 501;
BA_REL_ "GenSigTimeoutTime" BU_SG_REL_ EBCM_PHS SG_ 501 TransEstGear 500;
BA_REL_ "GenSigVBitResp" BU_SG_REL_ EBCM_PHS SG_ 501 TransEstGear 1;
BA_REL_ "GenSigSuprvResp" BU_SG_REL_ EBCM_PHS SG_ 501 TransEstGear 1;
BA_REL_ "GenSigTimeoutMsg" BU_SG_REL_ EBCM_PHS SG_ 501 TransEstGear 501;
BA_REL_ "GenSigTimeoutTime" BU_SG_REL_ EBCM_PHS SG_ 501 TransEstGear 500;
BA_REL_ "GenSigVBitResp" BU_SG_REL_ EBCM_PHS SG_ 211 ActAxleTrq 1;
BA_REL_ "GenSigSuprvResp" BU_SG_REL_ EBCM_PHS SG_ 1265 EngOffTmPT 1;
BA_REL_ "GenSigTimeoutMsg" BU_SG_REL_ EBCM_PHS SG_ 1265 EngOffTmPT 1265;
BA_REL_ "GenSigTimeoutTime" BU_SG_REL_ EBCM_PHS SG_ 1265 EngOffTmPT 2500;
BA_REL_ "GenSigSuprvResp" BU_SG_REL_ EBCM_PHS SG_ 1265 WhlDistPrRevNDrvn 1;
BA_REL_ "GenSigTimeoutMsg" BU_SG_REL_ EBCM_PHS SG_ 1265 WhlDistPrRevNDrvn 1265;
BA_REL_ "GenSigTimeoutTime" BU_SG_REL_ EBCM_PHS SG_ 1265 WhlDistPrRevNDrvn 2500;
BA_REL_ "GenSigSuprvResp" BU_SG_REL_ EBCM_PHS SG_ 1265 WhlDistPrRevNDrvn 1;
BA_REL_ "GenSigTimeoutMsg" BU_SG_REL_ EBCM_PHS SG_ 1265 WhlDistPrRevNDrvn 1265;
BA_REL_ "GenSigTimeoutTime" BU_SG_REL_ EBCM_PHS SG_ 1265 WhlDistPrRevNDrvn 2500;
BA_REL_ "GenSigSuprvResp" BU_SG_REL_ EBCM_PHS SG_ 1265 WhlDistPrRevDrvn 1;
BA_REL_ "GenSigTimeoutMsg" BU_SG_REL_ EBCM_PHS SG_ 1265 WhlDistPrRevDrvn 1265;
BA_REL_ "GenSigTimeoutTime" BU_SG_REL_ EBCM_PHS SG_ 1265 WhlDistPrRevDrvn 2500;
BA_REL_ "GenSigSuprvResp" BU_SG_REL_ EBCM_PHS SG_ 1265 WhlDistPrRevDrvn 1;
BA_REL_ "GenSigTimeoutMsg" BU_SG_REL_ EBCM_PHS SG_ 1265 WhlDistPrRevDrvn 1265;
BA_REL_ "GenSigTimeoutTime" BU_SG_REL_ EBCM_PHS SG_ 1265 WhlDistPrRevDrvn 2500;
BA_REL_ "GenSigSuprvResp" BU_SG_REL_ EBCM_PHS SG_ 1265 DrvlnFnlAxleRatio 1;
BA_REL_ "GenSigTimeoutMsg" BU_SG_REL_ EBCM_PHS SG_ 1265 DrvlnFnlAxleRatio 1265;
BA_REL_ "GenSigTimeoutTime" BU_SG_REL_ EBCM_PHS SG_ 1265 DrvlnFnlAxleRatio 2500;
BA_REL_ "GenSigSuprvResp" BU_SG_REL_ EBCM_PHS SG_ 1322 TireRRPrsStat 1;
BA_REL_ "GenSigTimeoutMsg" BU_SG_REL_ EBCM_PHS SG_ 1322 TireRRPrsStat 1322;
BA_REL_ "GenSigTimeoutTime" BU_SG_REL_ EBCM_PHS SG_ 1322 TireRRPrsStat 2500;
BA_REL_ "GenSigSuprvResp" BU_SG_REL_ EBCM_PHS SG_ 1322 TireRRPrsStat 1;
BA_REL_ "GenSigTimeoutMsg" BU_SG_REL_ EBCM_PHS SG_ 1322 TireRRPrsStat 1322;
BA_REL_ "GenSigTimeoutTime" BU_SG_REL_ EBCM_PHS SG_ 1322 TireRRPrsStat 2500;
BA_REL_ "GenSigVBitResp" BU_SG_REL_ EBCM_PHS SG_ 1322 TireRRPrs 1;
BA_REL_ "GenSigSuprvResp" BU_SG_REL_ EBCM_PHS SG_ 1322 TireRRPrs 1;
BA_REL_ "GenSigTimeoutMsg" BU_SG_REL_ EBCM_PHS SG_ 1322 TireRRPrs 1322;
BA_REL_ "GenSigTimeoutTime" BU_SG_REL_ EBCM_PHS SG_ 1322 TireRRPrs 2500;
BA_REL_ "GenSigVBitResp" BU_SG_REL_ EBCM_PHS SG_ 1322 TireRRPrs 1;
BA_REL_ "GenSigSuprvResp" BU_SG_REL_ EBCM_PHS SG_ 1322 TireRRPrs 1;
BA_REL_ "GenSigTimeoutMsg" BU_SG_REL_ EBCM_PHS SG_ 1322 TireRRPrs 1322;
BA_REL_ "GenSigTimeoutTime" BU_SG_REL_ EBCM_PHS SG_ 1322 TireRRPrs 2500;
BA_REL_ "GenSigSuprvResp" BU_SG_REL_ EBCM_PHS SG_ 1322 TireRFPrsStat 1;
BA_REL_ "GenSigTimeoutMsg" BU_SG_REL_ EBCM_PHS SG_ 1322 TireRFPrsStat 1322;
BA_REL_ "GenSigTimeoutTime" BU_SG_REL_ EBCM_PHS SG_ 1322 TireRFPrsStat 2500;
BA_REL_ "GenSigSuprvResp" BU_SG_REL_ EBCM_PHS SG_ 1322 TireRFPrsStat 1;
BA_REL_ "GenSigTimeoutMsg" BU_SG_REL_ EBCM_PHS SG_ 1322 TireRFPrsStat 1322;
BA_REL_ "GenSigTimeoutTime" BU_SG_REL_ EBCM_PHS SG_ 1322 TireRFPrsStat 2500;
BA_REL_ "GenSigVBitResp" BU_SG_REL_ EBCM_PHS SG_ 1322 TireRFPrs 1;
BA_REL_ "GenSigSuprvResp" BU_SG_REL_ EBCM_PHS SG_ 1322 TireRFPrs 1;
BA_REL_ "GenSigTimeoutMsg" BU_SG_REL_ EBCM_PHS SG_ 1322 TireRFPrs 1322;
BA_REL_ "GenSigTimeoutTime" BU_SG_REL_ EBCM_PHS SG_ 1322 TireRFPrs 2500;
BA_REL_ "GenSigVBitResp" BU_SG_REL_ EBCM_PHS SG_ 1322 TireRFPrs 1;
BA_REL_ "GenSigSuprvResp" BU_SG_REL_ EBCM_PHS SG_ 1322 TireRFPrs 1;
BA_REL_ "GenSigTimeoutMsg" BU_SG_REL_ EBCM_PHS SG_ 1322 TireRFPrs 1322;
BA_REL_ "GenSigTimeoutTime" BU_SG_REL_ EBCM_PHS SG_ 1322 TireRFPrs 2500;
BA_REL_ "GenSigSuprvResp" BU_SG_REL_ EBCM_PHS SG_ 1322 TireLRPrsStat 1;
BA_REL_ "GenSigTimeoutMsg" BU_SG_REL_ EBCM_PHS SG_ 1322 TireLRPrsStat 1322;
BA_REL_ "GenSigTimeoutTime" BU_SG_REL_ EBCM_PHS SG_ 1322 TireLRPrsStat 2500;
BA_REL_ "GenSigSuprvResp" BU_SG_REL_ EBCM_PHS SG_ 1322 TireLRPrsStat 1;
BA_REL_ "GenSigTimeoutMsg" BU_SG_REL_ EBCM_PHS SG_ 1322 TireLRPrsStat 1322;
BA_REL_ "GenSigTimeoutTime" BU_SG_REL_ EBCM_PHS SG_ 1322 TireLRPrsStat 2500;
BA_REL_ "GenSigVBitResp" BU_SG_REL_ EBCM_PHS SG_ 1322 TireLRPrs 1;
BA_REL_ "GenSigSuprvResp" BU_SG_REL_ EBCM_PHS SG_ 1322 TireLRPrs 1;
BA_REL_ "GenSigTimeoutMsg" BU_SG_REL_ EBCM_PHS SG_ 1322 TireLRPrs 1322;
BA_REL_ "GenSigTimeoutTime" BU_SG_REL_ EBCM_PHS SG_ 1322 TireLRPrs 2500;
BA_REL_ "GenSigVBitResp" BU_SG_REL_ EBCM_PHS SG_ 1322 TireLRPrs 1;
BA_REL_ "GenSigSuprvResp" BU_SG_REL_ EBCM_PHS SG_ 1322 TireLRPrs 1;
BA_REL_ "GenSigTimeoutMsg" BU_SG_REL_ EBCM_PHS SG_ 1322 TireLRPrs 1322;
BA_REL_ "GenSigTimeoutTime" BU_SG_REL_ EBCM_PHS SG_ 1322 TireLRPrs 2500;
BA_REL_ "GenSigSuprvResp" BU_SG_REL_ EBCM_PHS SG_ 1322 TireLFPrsStat 1;
BA_REL_ "GenSigTimeoutMsg" BU_SG_REL_ EBCM_PHS SG_ 1322 TireLFPrsStat 1322;
BA_REL_ "GenSigTimeoutTime" BU_SG_REL_ EBCM_PHS SG_ 1322 TireLFPrsStat 2500;
BA_REL_ "GenSigSuprvResp" BU_SG_REL_ EBCM_PHS SG_ 1322 TireLFPrsStat 1;
BA_REL_ "GenSigTimeoutMsg" BU_SG_REL_ EBCM_PHS SG_ 1322 TireLFPrsStat 1322;
BA_REL_ "GenSigTimeoutTime" BU_SG_REL_ EBCM_PHS SG_ 1322 TireLFPrsStat 2500;
BA_REL_ "GenSigVBitResp" BU_SG_REL_ EBCM_PHS SG_ 1322 TireLFPrs 1;
BA_REL_ "GenSigSuprvResp" BU_SG_REL_ EBCM_PHS SG_ 1322 TireLFPrs 1;
BA_REL_ "GenSigTimeoutMsg" BU_SG_REL_ EBCM_PHS SG_ 1322 TireLFPrs 1322;
BA_REL_ "GenSigTimeoutTime" BU_SG_REL_ EBCM_PHS SG_ 1322 TireLFPrs 2500;
BA_REL_ "GenSigVBitResp" BU_SG_REL_ EBCM_PHS SG_ 1322 TireLFPrs 1;
BA_REL_ "GenSigSuprvResp" BU_SG_REL_ EBCM_PHS SG_ 1322 TireLFPrs 1;
BA_REL_ "GenSigTimeoutMsg" BU_SG_REL_ EBCM_PHS SG_ 1322 TireLFPrs 1322;
BA_REL_ "GenSigTimeoutTime" BU_SG_REL_ EBCM_PHS SG_ 1322 TireLFPrs 2500;
BA_REL_ "GenSigSuprvResp" BU_SG_REL_ ADIMb_PHS SG_ 344 CSS_CoPilotCibAvail 1;
BA_REL_ "GenSigTimeoutMsg" BU_SG_REL_ ADIMb_PHS SG_ 344 CSS_CoPilotCibAvail 344;
BA_REL_ "GenSigTimeoutTime" BU_SG_REL_ ADIMb_PHS SG_ 344 CSS_CoPilotCibAvail 25;
BA_REL_ "GenSigSuprvResp" BU_SG_REL_ ADIMb_PHS SG_ 344 CSS_CoPilotSysFltStat 1;
BA_REL_ "GenSigTimeoutMsg" BU_SG_REL_ ADIMb_PHS SG_ 344 CSS_CoPilotSysFltStat 344;
BA_REL_ "GenSigTimeoutTime" BU_SG_REL_ ADIMb_PHS SG_ 344 CSS_CoPilotSysFltStat 25;
BA_REL_ "GenSigSuprvResp" BU_SG_REL_ ADIMb_PHS SG_ 344 CSS_CoPilotRvbAvail 1;
BA_REL_ "GenSigTimeoutMsg" BU_SG_REL_ ADIMb_PHS SG_ 344 CSS_CoPilotRvbAvail 344;
BA_REL_ "GenSigTimeoutTime" BU_SG_REL_ ADIMb_PHS SG_ 344 CSS_CoPilotRvbAvail 25;
BA_REL_ "GenSigSuprvResp" BU_SG_REL_ ADIMb_PHS SG_ 344 CSS_CoPilotPcmAvail 1;
BA_REL_ "GenSigTimeoutMsg" BU_SG_REL_ ADIMb_PHS SG_ 344 CSS_CoPilotPcmAvail 344;
BA_REL_ "GenSigTimeoutTime" BU_SG_REL_ ADIMb_PHS SG_ 344 CSS_CoPilotPcmAvail 25;
BA_REL_ "GenSigSuprvResp" BU_SG_REL_ ADIMb_PHS SG_ 344 CSS_CoPilotFcaAvail 1;
BA_REL_ "GenSigTimeoutMsg" BU_SG_REL_ ADIMb_PHS SG_ 344 CSS_CoPilotFcaAvail 344;
BA_REL_ "GenSigTimeoutTime" BU_SG_REL_ ADIMb_PHS SG_ 344 CSS_CoPilotFcaAvail 25;
BA_REL_ "GenSigSuprvResp" BU_SG_REL_ ADIMb_PHS SG_ 344 CSS_CoPilotBrkExpctd 1;
BA_REL_ "GenSigTimeoutMsg" BU_SG_REL_ ADIMb_PHS SG_ 344 CSS_CoPilotBrkExpctd 344;
BA_REL_ "GenSigTimeoutTime" BU_SG_REL_ ADIMb_PHS SG_ 344 CSS_CoPilotBrkExpctd 25;
BA_REL_ "GenSigRxStartValue" BU_SG_REL_ ADIMb_PHS SG_ 344 CoPilotSysStatInfoChcksm "0";
BA_REL_ "GenSigRxStartValue" BU_SG_REL_ ADIMb_PHS SG_ 344 CoPilotSysStatInfoARC "0";
BA_REL_ "GenSigSuprvResp" BU_SG_REL_ ADIMb_PHS SG_ 344 StrgAngTrqBsdEstSrfcMuConf 1;
BA_REL_ "GenSigTimeoutMsg" BU_SG_REL_ ADIMb_PHS SG_ 344 StrgAngTrqBsdEstSrfcMuConf 344;
BA_REL_ "GenSigTimeoutTime" BU_SG_REL_ ADIMb_PHS SG_ 344 StrgAngTrqBsdEstSrfcMuConf 25;
BA_REL_ "GenSigSuprvResp" BU_SG_REL_ ADIMb_PHS SG_ 344 StrgAngTrqBsdEstSrfcMuCapV 1;
BA_REL_ "GenSigTimeoutMsg" BU_SG_REL_ ADIMb_PHS SG_ 344 StrgAngTrqBsdEstSrfcMuCapV 344;
BA_REL_ "GenSigTimeoutTime" BU_SG_REL_ ADIMb_PHS SG_ 344 StrgAngTrqBsdEstSrfcMuCapV 25;
BA_REL_ "GenSigSuprvResp" BU_SG_REL_ ADIMb_PHS SG_ 344 StrgAngTrqBsdEstSrfcMuCap 1;
BA_REL_ "GenSigTimeoutMsg" BU_SG_REL_ ADIMb_PHS SG_ 344 StrgAngTrqBsdEstSrfcMuCap 344;
BA_REL_ "GenSigTimeoutTime" BU_SG_REL_ ADIMb_PHS SG_ 344 StrgAngTrqBsdEstSrfcMuCap 25;
BA_REL_ "GenSigSuprvResp" BU_SG_REL_ ADIMb_PHS SG_ 344 LatVlctyBsdSrfcMuCap 1;
BA_REL_ "GenSigTimeoutMsg" BU_SG_REL_ ADIMb_PHS SG_ 344 LatVlctyBsdSrfcMuCap 344;
BA_REL_ "GenSigTimeoutTime" BU_SG_REL_ ADIMb_PHS SG_ 344 LatVlctyBsdSrfcMuCap 25;
BA_REL_ "GenSigSuprvResp" BU_SG_REL_ EBCM_PHS SG_ 533 ExtBrkReqStat 1;
BA_REL_ "GenSigTimeoutMsg" BU_SG_REL_ EBCM_PHS SG_ 533 ExtBrkReqStat 533;
BA_REL_ "GenSigTimeoutTime" BU_SG_REL_ EBCM_PHS SG_ 533 ExtBrkReqStat 250;
BA_REL_ "GenSigRxStartValue" BU_SG_REL_ ADIMb_PHS SG_ 533 SecLongStabSysStatRed "Unknown";
BA_REL_ "GenSigSuprvResp" BU_SG_REL_ ADIMb_PHS SG_ 533 SecLongStabSysStatRed 1;
BA_REL_ "GenSigTimeoutMsg" BU_SG_REL_ ADIMb_PHS SG_ 533 SecLongStabSysStatRed 533;
BA_REL_ "GenSigTimeoutTime" BU_SG_REL_ ADIMb_PHS SG_ 533 SecLongStabSysStatRed 50;
BA_REL_ "GenSigRxStartValue" BU_SG_REL_ ADIMb_PHS SG_ 533 SecLatStabSysStatRed "Unknown";
BA_REL_ "GenSigSuprvResp" BU_SG_REL_ ADIMb_PHS SG_ 533 SecLatStabSysStatRed 1;
BA_REL_ "GenSigTimeoutMsg" BU_SG_REL_ ADIMb_PHS SG_ 533 SecLatStabSysStatRed 533;
BA_REL_ "GenSigTimeoutTime" BU_SG_REL_ ADIMb_PHS SG_ 533 SecLatStabSysStatRed 50;
BA_REL_ "GenSigRxStartValue" BU_SG_REL_ ADIMb_PHS SG_ 533 SecGrsHydLkDtctdRed "False";
BA_REL_ "GenSigSuprvResp" BU_SG_REL_ ADIMb_PHS SG_ 533 SecGrsHydLkDtctdRed 1;
BA_REL_ "GenSigTimeoutMsg" BU_SG_REL_ ADIMb_PHS SG_ 533 SecGrsHydLkDtctdRed 533;
BA_REL_ "GenSigTimeoutTime" BU_SG_REL_ ADIMb_PHS SG_ 533 SecGrsHydLkDtctdRed 50;
BA_REL_ "GenSigRxStartValue" BU_SG_REL_ ADIMb_PHS SG_ 533 SecGrsHydCmpDtctdRed "False";
BA_REL_ "GenSigSuprvResp" BU_SG_REL_ ADIMb_PHS SG_ 533 SecGrsHydCmpDtctdRed 1;
BA_REL_ "GenSigTimeoutMsg" BU_SG_REL_ ADIMb_PHS SG_ 533 SecGrsHydCmpDtctdRed 533;
BA_REL_ "GenSigTimeoutTime" BU_SG_REL_ ADIMb_PHS SG_ 533 SecGrsHydCmpDtctdRed 50;
BA_REL_ "GenSigRxStartValue" BU_SG_REL_ ADIMb_PHS SG_ 533 RedBlkPedDet "False";
BA_REL_ "GenSigSuprvResp" BU_SG_REL_ ADIMb_PHS SG_ 533 RedBlkPedDet 1;
BA_REL_ "GenSigTimeoutMsg" BU_SG_REL_ ADIMb_PHS SG_ 533 RedBlkPedDet 533;
BA_REL_ "GenSigTimeoutTime" BU_SG_REL_ ADIMb_PHS SG_ 533 RedBlkPedDet 50;
BA_REL_ "GenSigSuprvResp" BU_SG_REL_ EBCM_PHS SG_ 533 RedBlkPedDet 1;
BA_REL_ "GenSigTimeoutMsg" BU_SG_REL_ EBCM_PHS SG_ 533 RedBlkPedDet 533;
BA_REL_ "GenSigTimeoutTime" BU_SG_REL_ EBCM_PHS SG_ 533 RedBlkPedDet 250;
BA_REL_ "GenSigRxStartValue" BU_SG_REL_ ADIMb_PHS SG_ 533 SecDynCtrlStatRedChksm "0";
BA_REL_ "GenSigRxStartValue" BU_SG_REL_ ADIMb_PHS SG_ 533 SecDynCtrlStatRedARC "0";
BA_REL_ "GenSigSuprvResp" BU_SG_REL_ EBCM_PHS SG_ 533 RediBstStat 1;
BA_REL_ "GenSigTimeoutMsg" BU_SG_REL_ EBCM_PHS SG_ 533 RediBstStat 533;
BA_REL_ "GenSigTimeoutTime" BU_SG_REL_ EBCM_PHS SG_ 533 RediBstStat 250;
BA_REL_ "GenSigSuprvResp" BU_SG_REL_ ADIMb_PHS SG_ 533 RediBstStat 1;
BA_REL_ "GenSigTimeoutMsg" BU_SG_REL_ ADIMb_PHS SG_ 533 RediBstStat 533;
BA_REL_ "GenSigTimeoutTime" BU_SG_REL_ ADIMb_PHS SG_ 533 RediBstStat 250;
BA_REL_ "GenSigRxStartValue" BU_SG_REL_ ADIMb_PHS SG_ 233 AutoCoPAxlTrqCmnd2PVal "0";
BA_REL_ "GenSigSuprvResp" BU_SG_REL_ ADIMb_PHS SG_ 233 ACATC2_AutoCoPCntrlAct 1;
BA_REL_ "GenSigTimeoutMsg" BU_SG_REL_ ADIMb_PHS SG_ 233 ACATC2_AutoCoPCntrlAct 233;
BA_REL_ "GenSigTimeoutTime" BU_SG_REL_ ADIMb_PHS SG_ 233 ACATC2_AutoCoPCntrlAct 25;
BA_REL_ "GenSigSuprvResp" BU_SG_REL_ ADIMb_PHS SG_ 233 ACATC2_CoPAxlTrqReq 1;
BA_REL_ "GenSigTimeoutMsg" BU_SG_REL_ ADIMb_PHS SG_ 233 ACATC2_CoPAxlTrqReq 233;
BA_REL_ "GenSigTimeoutTime" BU_SG_REL_ ADIMb_PHS SG_ 233 ACATC2_CoPAxlTrqReq 25;
BA_REL_ "GenSigRxStartValue" BU_SG_REL_ ADIMb_PHS SG_ 233 AutoCoPAxlTrqCmnd2ARC "0";
BA_REL_ "GenSigSuprvResp" BU_SG_REL_ EBCM_PHS SG_ 347 EBstRnotPrsQlfr 1;
BA_REL_ "GenSigTimeoutMsg" BU_SG_REL_ EBCM_PHS SG_ 347 EBstRnotPrsQlfr 347;
BA_REL_ "GenSigTimeoutTime" BU_SG_REL_ EBCM_PHS SG_ 347 EBstRnotPrsQlfr 250;
BA_REL_ "GenSigSuprvResp" BU_SG_REL_ EBCM_PHS SG_ 347 EBstRnotPrs 1;
BA_REL_ "GenSigTimeoutMsg" BU_SG_REL_ EBCM_PHS SG_ 347 EBstRnotPrs 347;
BA_REL_ "GenSigTimeoutTime" BU_SG_REL_ EBCM_PHS SG_ 347 EBstRnotPrs 250;
BA_REL_ "GenSigSuprvResp" BU_SG_REL_ EBCM_PHS SG_ 347 BrkPedApdQlfr 1;
BA_REL_ "GenSigTimeoutMsg" BU_SG_REL_ EBCM_PHS SG_ 347 BrkPedApdQlfr 347;
BA_REL_ "GenSigTimeoutTime" BU_SG_REL_ EBCM_PHS SG_ 347 BrkPedApdQlfr 250;
BA_REL_ "GenSigSuprvResp" BU_SG_REL_ EBCM_PHS SG_ 347 BrkPedApd 1;
BA_REL_ "GenSigTimeoutMsg" BU_SG_REL_ EBCM_PHS SG_ 347 BrkPedApd 347;
BA_REL_ "GenSigTimeoutTime" BU_SG_REL_ EBCM_PHS SG_ 347 BrkPedApd 250;
BA_REL_ "GenSigRxStartValue" BU_SG_REL_ ADIMb_PHS SG_ 347 SecBrkModStatRed "0";
BA_REL_ "GenSigSuprvResp" BU_SG_REL_ ADIMb_PHS SG_ 347 SecBrkModStatRed 1;
BA_REL_ "GenSigTimeoutMsg" BU_SG_REL_ ADIMb_PHS SG_ 347 SecBrkModStatRed 347;
BA_REL_ "GenSigTimeoutTime" BU_SG_REL_ ADIMb_PHS SG_ 347 SecBrkModStatRed 25;
BA_REL_ "GenSigRxStartValue" BU_SG_REL_ ADIMb_PHS SG_ 347 SecAutoEstBrkTrqAppStatRed "0";
BA_REL_ "GenSigSuprvResp" BU_SG_REL_ ADIMb_PHS SG_ 347 SecAutoEstBrkTrqAppStatRed 1;
BA_REL_ "GenSigTimeoutMsg" BU_SG_REL_ ADIMb_PHS SG_ 347 SecAutoEstBrkTrqAppStatRed 347;
BA_REL_ "GenSigTimeoutTime" BU_SG_REL_ ADIMb_PHS SG_ 347 SecAutoEstBrkTrqAppStatRed 25;
BA_REL_ "GenSigRxStartValue" BU_SG_REL_ ADIMb_PHS SG_ 347 SecAutoEstBrkTrqApdRed "0";
BA_REL_ "GenSigSuprvResp" BU_SG_REL_ ADIMb_PHS SG_ 347 SecAutoEstBrkTrqApdRed 1;
BA_REL_ "GenSigTimeoutMsg" BU_SG_REL_ ADIMb_PHS SG_ 347 SecAutoEstBrkTrqApdRed 347;
BA_REL_ "GenSigTimeoutTime" BU_SG_REL_ ADIMb_PHS SG_ 347 SecAutoEstBrkTrqApdRed 25;
BA_REL_ "GenSigRxStartValue" BU_SG_REL_ ADIMb_PHS SG_ 347 SecAutoBrkSysDrInfcStatRed "0";
BA_REL_ "GenSigSuprvResp" BU_SG_REL_ ADIMb_PHS SG_ 347 SecAutoBrkSysDrInfcStatRed 1;
BA_REL_ "GenSigTimeoutMsg" BU_SG_REL_ ADIMb_PHS SG_ 347 SecAutoBrkSysDrInfcStatRed 347;
BA_REL_ "GenSigTimeoutTime" BU_SG_REL_ ADIMb_PHS SG_ 347 SecAutoBrkSysDrInfcStatRed 25;
BA_REL_ "GenSigRxStartValue" BU_SG_REL_ EBCM_PHS SG_ 347 SecAutoBrkSysDrInfcStatRed "Unknown";
BA_REL_ "GenSigSuprvResp" BU_SG_REL_ EBCM_PHS SG_ 347 SecAutoBrkSysDrInfcStatRed 1;
BA_REL_ "GenSigTimeoutMsg" BU_SG_REL_ EBCM_PHS SG_ 347 SecAutoBrkSysDrInfcStatRed 347;
BA_REL_ "GenSigTimeoutTime" BU_SG_REL_ EBCM_PHS SG_ 347 SecAutoBrkSysDrInfcStatRed 250;
BA_REL_ "GenSigRxStartValue" BU_SG_REL_ ADIMb_PHS SG_ 347 SecAutoAxlTrqReqStatRedChksm "0";
BA_REL_ "GenSigRxStartValue" BU_SG_REL_ ADIMb_PHS SG_ 347 SecAutoAxlTrqReqStatRedARC "0";
BA_REL_ "GenSigRxStartValue" BU_SG_REL_ ADIMb_PHS SG_ 347 SecAutoArbBrkTrqReqRed "0";
BA_REL_ "GenSigSuprvResp" BU_SG_REL_ ADIMb_PHS SG_ 347 SecAutoArbBrkTrqReqRed 1;
BA_REL_ "GenSigTimeoutMsg" BU_SG_REL_ ADIMb_PHS SG_ 347 SecAutoArbBrkTrqReqRed 347;
BA_REL_ "GenSigTimeoutTime" BU_SG_REL_ ADIMb_PHS SG_ 347 SecAutoArbBrkTrqReqRed 25;
BA_REL_ "GenSigSuprvResp" BU_SG_REL_ EBCM_PHS SG_ 479 EASSI_UnsdRsrvd2 1;
BA_REL_ "GenSigTimeoutMsg" BU_SG_REL_ EBCM_PHS SG_ 479 EASSI_UnsdRsrvd2 479;
BA_REL_ "GenSigTimeoutTime" BU_SG_REL_ EBCM_PHS SG_ 479 EASSI_UnsdRsrvd2 500;
BA_REL_ "GenSigSuprvResp" BU_SG_REL_ EBCM_PHS SG_ 479 EASSI_StlDetd 1;
BA_REL_ "GenSigTimeoutMsg" BU_SG_REL_ EBCM_PHS SG_ 479 EASSI_StlDetd 479;
BA_REL_ "GenSigTimeoutTime" BU_SG_REL_ EBCM_PHS SG_ 479 EASSI_StlDetd 500;
BA_REL_ "GenSigSuprvResp" BU_SG_REL_ EBCM_PHS SG_ 479 EASSI_TrqDetd 1;
BA_REL_ "GenSigTimeoutMsg" BU_SG_REL_ EBCM_PHS SG_ 479 EASSI_TrqDetd 479;
BA_REL_ "GenSigTimeoutTime" BU_SG_REL_ EBCM_PHS SG_ 479 EASSI_TrqDetd 500;
BA_REL_ "GenSigSuprvResp" BU_SG_REL_ EBCM_PHS SG_ 479 EASSI_FuelReqOn 1;
BA_REL_ "GenSigTimeoutMsg" BU_SG_REL_ EBCM_PHS SG_ 479 EASSI_FuelReqOn 479;
BA_REL_ "GenSigTimeoutTime" BU_SG_REL_ EBCM_PHS SG_ 479 EASSI_FuelReqOn 500;
BA_REL_ "GenSigSuprvResp" BU_SG_REL_ EBCM_PHS SG_ 479 EASSI_StrtTyp 1;
BA_REL_ "GenSigTimeoutMsg" BU_SG_REL_ EBCM_PHS SG_ 479 EASSI_StrtTyp 479;
BA_REL_ "GenSigTimeoutTime" BU_SG_REL_ EBCM_PHS SG_ 479 EASSI_StrtTyp 500;
BA_REL_ "GenSigSuprvResp" BU_SG_REL_ EBCM_PHS SG_ 479 EASSI_StrtStpSt 1;
BA_REL_ "GenSigTimeoutMsg" BU_SG_REL_ EBCM_PHS SG_ 479 EASSI_StrtStpSt 479;
BA_REL_ "GenSigTimeoutTime" BU_SG_REL_ EBCM_PHS SG_ 479 EASSI_StrtStpSt 500;
BA_REL_ "GenSigSuprvResp" BU_SG_REL_ EBCM_PHS SG_ 479 EASSI_TorqDetdIndet 1;
BA_REL_ "GenSigTimeoutMsg" BU_SG_REL_ EBCM_PHS SG_ 479 EASSI_TorqDetdIndet 479;
BA_REL_ "GenSigTimeoutTime" BU_SG_REL_ EBCM_PHS SG_ 479 EASSI_TorqDetdIndet 500;
BA_REL_ "GenSigSuprvResp" BU_SG_REL_ EBOOST_OBD_PHS SG_ 479 PrplsnSysAtv 1;
BA_REL_ "GenSigTimeoutMsg" BU_SG_REL_ EBOOST_OBD_PHS SG_ 479 PrplsnSysAtv 479;
BA_REL_ "GenSigTimeoutTime" BU_SG_REL_ EBOOST_OBD_PHS SG_ 479 PrplsnSysAtv 250;
BA_REL_ "GenSigSuprvResp" BU_SG_REL_ EBCM_PHS SG_ 479 PrplsnSysAtv 1;
BA_REL_ "GenSigTimeoutMsg" BU_SG_REL_ EBCM_PHS SG_ 479 PrplsnSysAtv 479;
BA_REL_ "GenSigTimeoutTime" BU_SG_REL_ EBCM_PHS SG_ 479 PrplsnSysAtv 500;
BA_REL_ "GenSigSuprvResp" BU_SG_REL_ EBCM_PHS SG_ 452 FSpRgACCSwADd 1;
BA_REL_ "GenSigTimeoutMsg" BU_SG_REL_ EBCM_PHS SG_ 452 FSpRgACCSwADd 452;
BA_REL_ "GenSigTimeoutTime" BU_SG_REL_ EBCM_PHS SG_ 452 FSpRgACCSwADd 250;
BA_REL_ "GenSigSuprvResp" BU_SG_REL_ EBCM_PHS SG_ 452 ABAAPS_AccPos 1;
BA_REL_ "GenSigTimeoutMsg" BU_SG_REL_ EBCM_PHS SG_ 452 ABAAPS_AccPos 452;
BA_REL_ "GenSigTimeoutTime" BU_SG_REL_ EBCM_PHS SG_ 452 ABAAPS_AccPos 250;
BA_REL_ "GenSigSuprvResp" BU_SG_REL_ EBCM_PHS SG_ 452 ABAAPS_AccPos 1;
BA_REL_ "GenSigTimeoutMsg" BU_SG_REL_ EBCM_PHS SG_ 452 ABAAPS_AccPos 452;
BA_REL_ "GenSigTimeoutTime" BU_SG_REL_ EBCM_PHS SG_ 452 ABAAPS_AccPos 250;
BA_REL_ "GenSigSuprvResp" BU_SG_REL_ EBCM_PHS SG_ 452 ABAAPS_AccPos 1;
BA_REL_ "GenSigTimeoutMsg" BU_SG_REL_ EBCM_PHS SG_ 452 ABAAPS_AccPos 452;
BA_REL_ "GenSigTimeoutTime" BU_SG_REL_ EBCM_PHS SG_ 452 ABAAPS_AccPos 250;
BA_REL_ "GenSigSuprvResp" BU_SG_REL_ EBCM_PHS SG_ 452 ABAAPS_AccPos 1;
BA_REL_ "GenSigTimeoutMsg" BU_SG_REL_ EBCM_PHS SG_ 452 ABAAPS_AccPos 452;
BA_REL_ "GenSigTimeoutTime" BU_SG_REL_ EBCM_PHS SG_ 452 ABAAPS_AccPos 250;
BA_REL_ "GenSigSuprvResp" BU_SG_REL_ EBCM_PHS SG_ 452 ABAAPS_AccPos 1;
BA_REL_ "GenSigTimeoutMsg" BU_SG_REL_ EBCM_PHS SG_ 452 ABAAPS_AccPos 452;
BA_REL_ "GenSigTimeoutTime" BU_SG_REL_ EBCM_PHS SG_ 452 ABAAPS_AccPos 250;
BA_REL_ "GenSigSuprvResp" BU_SG_REL_ EBCM_PHS SG_ 452 ABAAPS_AccPosV 1;
BA_REL_ "GenSigTimeoutMsg" BU_SG_REL_ EBCM_PHS SG_ 452 ABAAPS_AccPosV 452;
BA_REL_ "GenSigTimeoutTime" BU_SG_REL_ EBCM_PHS SG_ 452 ABAAPS_AccPosV 250;
BA_REL_ "GenSigSuprvResp" BU_SG_REL_ EBCM_PHS SG_ 452 ABAAPS_AccPosV 1;
BA_REL_ "GenSigTimeoutMsg" BU_SG_REL_ EBCM_PHS SG_ 452 ABAAPS_AccPosV 452;
BA_REL_ "GenSigTimeoutTime" BU_SG_REL_ EBCM_PHS SG_ 452 ABAAPS_AccPosV 250;
BA_REL_ "GenSigSuprvResp" BU_SG_REL_ EBCM_PHS SG_ 452 ABAAPS_AccPosV 1;
BA_REL_ "GenSigTimeoutMsg" BU_SG_REL_ EBCM_PHS SG_ 452 ABAAPS_AccPosV 452;
BA_REL_ "GenSigTimeoutTime" BU_SG_REL_ EBCM_PHS SG_ 452 ABAAPS_AccPosV 250;
BA_REL_ "GenSigSuprvResp" BU_SG_REL_ EBCM_PHS SG_ 452 ABAAPS_AccPosV 1;
BA_REL_ "GenSigTimeoutMsg" BU_SG_REL_ EBCM_PHS SG_ 452 ABAAPS_AccPosV 452;
BA_REL_ "GenSigTimeoutTime" BU_SG_REL_ EBCM_PHS SG_ 452 ABAAPS_AccPosV 250;
BA_REL_ "GenSigSuprvResp" BU_SG_REL_ EBCM_PHS SG_ 452 ABAAPS_AccPosV 1;
BA_REL_ "GenSigTimeoutMsg" BU_SG_REL_ EBCM_PHS SG_ 452 ABAAPS_AccPosV 452;
BA_REL_ "GenSigTimeoutTime" BU_SG_REL_ EBCM_PHS SG_ 452 ABAAPS_AccPosV 250;
BA_REL_ "GenSigSuprvResp" BU_SG_REL_ EBCM_PHS SG_ 452 AccPdlOvrrdAtv 1;
BA_REL_ "GenSigTimeoutMsg" BU_SG_REL_ EBCM_PHS SG_ 452 AccPdlOvrrdAtv 452;
BA_REL_ "GenSigTimeoutTime" BU_SG_REL_ EBCM_PHS SG_ 452 AccPdlOvrrdAtv 250;
BA_REL_ "GenSigSuprvResp" BU_SG_REL_ EBCM_PHS SG_ 298 ValetMdAct 1;
BA_REL_ "GenSigTimeoutMsg" BU_SG_REL_ EBCM_PHS SG_ 298 ValetMdAct 298;
BA_REL_ "GenSigTimeoutTime" BU_SG_REL_ EBCM_PHS SG_ 298 ValetMdAct 250;
BA_REL_ "GenSigSuprvResp" BU_SG_REL_ EBCM_PHS SG_ 298 TCSysDisSwAtvARC 1;
BA_REL_ "GenSigTimeoutMsg" BU_SG_REL_ EBCM_PHS SG_ 298 TCSysDisSwAtvARC 298;
BA_REL_ "GenSigTimeoutTime" BU_SG_REL_ EBCM_PHS SG_ 298 TCSysDisSwAtvARC 250;
BA_REL_ "GenSigVDAFailComment" BU_SG_REL_ EOCM2cp_IMX6_PHS SG_ 298 ChmAct "Chime Master VDA";
BA_REL_ "GenSigVDAFailResp" BU_SG_REL_ EOCM2cp_IMX6_PHS SG_ 298 ChmAct 1;
BA_REL_ "GenSigSuprvResp" BU_SG_REL_ EBCM_PHS SG_ 298 Ky_IdDevPr 1;
BA_REL_ "GenSigTimeoutMsg" BU_SG_REL_ EBCM_PHS SG_ 298 Ky_IdDevPr 298;
BA_REL_ "GenSigTimeoutTime" BU_SG_REL_ EBCM_PHS SG_ 298 Ky_IdDevPr 500;
BA_REL_ "GenSigVBitResp" BU_SG_REL_ EOCM2cp_IMX6_PHS SG_ 298 PsSbltAtc 1;
BA_REL_ "GenSigSuprvResp" BU_SG_REL_ EBCM_PHS SG_ 298 SusCustStngReq 1;
BA_REL_ "GenSigTimeoutMsg" BU_SG_REL_ EBCM_PHS SG_ 298 SusCustStngReq 298;
BA_REL_ "GenSigTimeoutTime" BU_SG_REL_ EBCM_PHS SG_ 298 SusCustStngReq 500;
BA_REL_ "GenSigSuprvResp" BU_SG_REL_ EBCM_PHS SG_ 298 StrCustStngReq 1;
BA_REL_ "GenSigTimeoutMsg" BU_SG_REL_ EBCM_PHS SG_ 298 StrCustStngReq 298;
BA_REL_ "GenSigTimeoutTime" BU_SG_REL_ EBCM_PHS SG_ 298 StrCustStngReq 500;
BA_REL_ "GenSigSuprvResp" BU_SG_REL_ EBCM_PHS SG_ 298 RstrCustFctrDef 1;
BA_REL_ "GenSigTimeoutMsg" BU_SG_REL_ EBCM_PHS SG_ 298 RstrCustFctrDef 298;
BA_REL_ "GenSigTimeoutTime" BU_SG_REL_ EBCM_PHS SG_ 298 RstrCustFctrDef 500;
BA_REL_ "GenSigSuprvResp" BU_SG_REL_ EBCM_PHS SG_ 298 DrvlnCustStngReq 1;
BA_REL_ "GenSigTimeoutMsg" BU_SG_REL_ EBCM_PHS SG_ 298 DrvlnCustStngReq 298;
BA_REL_ "GenSigTimeoutTime" BU_SG_REL_ EBCM_PHS SG_ 298 DrvlnCustStngReq 500;
BA_REL_ "GenSigSuprvResp" BU_SG_REL_ EBCM_PHS SG_ 298 DDAjrSwAtv 1;
BA_REL_ "GenSigTimeoutMsg" BU_SG_REL_ EBCM_PHS SG_ 298 DDAjrSwAtv 298;
BA_REL_ "GenSigTimeoutTime" BU_SG_REL_ EBCM_PHS SG_ 298 DDAjrSwAtv 500;
BA_REL_ "GenSigSuprvResp" BU_SG_REL_ EBCM_PHS SG_ 298 DrId 1;
BA_REL_ "GenSigTimeoutMsg" BU_SG_REL_ EBCM_PHS SG_ 298 DrId 298;
BA_REL_ "GenSigTimeoutTime" BU_SG_REL_ EBCM_PHS SG_ 298 DrId 250;
BA_REL_ "GenSigRxStartValue" BU_SG_REL_ EBOOST_OBD_PHS SG_ 298 EnrgMgtLdShdRq "No Load Shedding";
BA_REL_ "GenSigRxStartValue" BU_SG_REL_ EPSb_PHS SG_ 298 EnrgMgtLdShdRq "No Load Shedding";
BA_REL_ "GenSigRxStartValue" BU_SG_REL_ EBCM_PHS SG_ 298 EnrgMgtLdShdRq "No Load Shedding";
BA_REL_ "GenSigRxStartValue" BU_SG_REL_ EPSa_PHS SG_ 298 EnrgMgtLdShdRq "No Load Shedding";
BA_REL_ "GenSigVDAFailComment" BU_SG_REL_ EBCM_PHS SG_ 298 TrlrHtchSwAtv "Trailer Hardware Interface VDA";
BA_REL_ "GenSigVDAFailResp" BU_SG_REL_ EBCM_PHS SG_ 298 TrlrHtchSwAtv 1;
BA_REL_ "GenSigSuprvResp" BU_SG_REL_ EBCM_PHS SG_ 298 TrlrHtchSwAtv 1;
BA_REL_ "GenSigTimeoutMsg" BU_SG_REL_ EBCM_PHS SG_ 298 TrlrHtchSwAtv 298;
BA_REL_ "GenSigTimeoutTime" BU_SG_REL_ EBCM_PHS SG_ 298 TrlrHtchSwAtv 500;
BA_REL_ "GenSigSuprvResp" BU_SG_REL_ EBCM_PHS SG_ 298 TreInfMonSysRstReq 1;
BA_REL_ "GenSigTimeoutMsg" BU_SG_REL_ EBCM_PHS SG_ 298 TreInfMonSysRstReq 298;
BA_REL_ "GenSigTimeoutTime" BU_SG_REL_ EBCM_PHS SG_ 298 TreInfMonSysRstReq 500;
BA_REL_ "GenSigVBitResp" BU_SG_REL_ EOCM2cp_IMX6_PHS SG_ 298 BatVlt 1;
BA_REL_ "GenSigVBitResp" BU_SG_REL_ EOCM2cp_IMX6_PHS SG_ 298 DrSbltAtc 1;
BA_REL_ "GenSigVBitResp" BU_SG_REL_ EBCM_PHS SG_ 298 DrSbltAtc 1;
BA_REL_ "GenSigSuprvResp" BU_SG_REL_ EBCM_PHS SG_ 298 DrSbltAtc 1;
BA_REL_ "GenSigTimeoutMsg" BU_SG_REL_ EBCM_PHS SG_ 298 DrSbltAtc 298;
BA_REL_ "GenSigTimeoutTime" BU_SG_REL_ EBCM_PHS SG_ 298 DrSbltAtc 500;
VAL_ 386 AHAct 1 "true" 0 "false" ;
VAL_ 386 AHEnbld 1 "true" 0 "false" ;
VAL_ 386 ShfToPrkBfExtngIO 1 "true" 0 "false" ;
VAL_ 386 AHServcIO 1 "true" 0 "false" ;
VAL_ 386 AHAppBrkPedlIO 1 "true" 0 "false" ;
VAL_ 386 AHDisbldStbltIO 1 "true" 0 "false" ;
VAL_ 386 AHDisbldDrOpnIO 1 "true" 0 "false" ;
VAL_ 386 PMVSS_Disps 7 "Visualization Type 7" 6 "Visualization Type 6" 5 "Visualization Type 5" 4 "Visualization Type 4" 3 "Visualization Type 3" 2 "Visualization Type 2" 1 "Visualization Type 1" 0 "No Action" ;
VAL_ 386 PMVSS_Exhst 7 "Visualization Type 7" 6 "Visualization Type 6" 5 "Visualization Type 5" 4 "Visualization Type 4" 3 "Visualization Type 3" 2 "Visualization Type 2" 1 "Visualization Type 1" 0 "No Action" ;
VAL_ 386 PMVSS_PsngrSeat 7 "Visualization Type 7" 6 "Visualization Type 6" 5 "Visualization Type 5" 4 "Visualization Type 4" 3 "Visualization Type 3" 2 "Visualization Type 2" 1 "Visualization Type 1" 0 "No Action" ;
VAL_ 386 PMVSS_DrvrSeat 7 "Visualization Type 7" 6 "Visualization Type 6" 5 "Visualization Type 5" 4 "Visualization Type 4" 3 "Visualization Type 3" 2 "Visualization Type 2" 1 "Visualization Type 1" 0 "No Action" ;
VAL_ 386 PMVSS_AdptCrsCnt 7 "Visualization Type 7" 6 "Visualization Type 6" 5 "Visualization Type 5" 4 "Visualization Type 4" 3 "Visualization Type 3" 2 "Visualization Type 2" 1 "Visualization Type 1" 0 "No Action" ;
VAL_ 386 PMVSS_Drvln 7 "Visualization Type 7" 6 "Visualization Type 6" 5 "Visualization Type 5" 4 "Visualization Type 4" 3 "Visualization Type 3" 2 "Visualization Type 2" 1 "Visualization Type 1" 0 "No Action" ;
VAL_ 386 PMVSS_Susp 7 "Visualization Type 7" 6 "Visualization Type 6" 5 "Visualization Type 5" 4 "Visualization Type 4" 3 "Visualization Type 3" 2 "Visualization Type 2" 1 "Visualization Type 1" 0 "No Action" ;
VAL_ 386 PMVSS_Strng 7 "Visualization Type 7" 6 "Visualization Type 6" 5 "Visualization Type 5" 4 "Visualization Type 4" 3 "Visualization Type 3" 2 "Visualization Type 2" 1 "Visualization Type 1" 0 "No Action" ;
VAL_ 386 PMVSS_Trans 7 "Visualization Type 7" 6 "Visualization Type 6" 5 "Visualization Type 5" 4 "Visualization Type 4" 3 "Visualization Type 3" 2 "Visualization Type 2" 1 "Visualization Type 1" 0 "No Action" ;
VAL_ 386 PMVSS_Eng 7 "Visualization Type 7" 6 "Visualization Type 6" 5 "Visualization Type 5" 4 "Visualization Type 4" 3 "Visualization Type 3" 2 "Visualization Type 2" 1 "Visualization Type 1" 0 "No Action" ;
VAL_ 386 PMVSS_Snd 7 "Visualization Type 7" 6 "Visualization Type 6" 5 "Visualization Type 5" 4 "Visualization Type 4" 3 "Visualization Type 3" 2 "Visualization Type 2" 1 "Visualization Type 1" 0 "No Action" ;
VAL_ 386 AdptCruzCtrlStg 7 "Performance Mode 7" 6 "Performance Mode 6" 5 "Performance Mode 5" 4 "Performance Mode 4" 3 "Performance Mode 3" 2 "Performance Mode 2" 1 "Performance Mode 1" 0 "No Action" ;
VAL_ 386 AWDRecmndIO 1 "true" 0 "false" ;
VAL_ 386 EnvIdRspSt4 3 "Environment_id_request" 2 "Incorrect_immo_id" 1 "Info_valid" 0 "No_info" ;
VAL_ 560 ElecPrkBrkSwStatV 1 "Invalid" 0 "Valid" ;
VAL_ 560 ElecPrkBrkSwStat 3 "Active" 2 "Apply" 1 "Release" 0 "NotActive" ;
VAL_ 560 AllNodesVNA 1 "Activate Virtual Network" 0 "No Activation" ;
VAL_ 560 StpOnBrkToRelPBIndOn 1 "true" 0 "false" ;
VAL_ 560 EPBC_EPBrkAutBrkRq 1 "true" 0 "false" ;
VAL_ 560 EPBSysDspMsgReq 7 "Message #7" 6 "Message #6" 5 "Message #5" 4 "Message #4" 3 "Message #3" 2 "Message #2" 1 "Message #1" 0 "Off" ;
VAL_ 560 EPBSysAudWarnReq 2 "Warning #2" 1 "Warning #1" 0 "Off" ;
VAL_ 560 ElecPrkBrkStat 2 "Fault" 1 "Applied" 0 "Released" ;
VAL_ 560 EPBCrsCanRq 1 "true" 0 "false" ;
VAL_ 560 EPBSysStatIndReq 3 "Flash Rate 2 Indication" 2 "Flash Rate 1 Indication" 1 "Continuous Indication" 0 "No Indication" ;
VAL_ 560 EPBSysWrnIndReq 3 "Flash Rate #2 Indication" 2 "Flash Rate #1 Indication" 1 "Continuous Indication" 0 "No Indication" ;
VAL_ 560 EPBSysBrkLtsReq 1 "true" 0 "false" ;
VAL_ 1280 TireRRLowTracIO 1 "true" 0 "false" ;
VAL_ 1280 TireRFLowTracIO 1 "true" 0 "false" ;
VAL_ 1280 TireLRLowTracIO 1 "true" 0 "false" ;
VAL_ 1280 TireLFLowTracIO 1 "true" 0 "false" ;
VAL_ 761 BrkSysHRBkCtrlAvail 1 "true" 0 "false" ;
VAL_ 761 BrkSysHRBkCtrlStat 0 "Inactive" 1 "Control Target Vehicle Speed" 2 "Unused and Reserved 1" 3 "Unused and Reserved 2" ;
VAL_ 761 BrkSysHSAAval 1 "true" 0 "false" ;
VAL_ 761 BrkSysHSAStat 0 "Inactive" 1 "Brake Pressure Hold" 2 "Normal Pressure Decay" 3 "Drive-off Pressure Decay" ;
VAL_ 761 HillDscntCtrlStat 0 "Not Enabled" 1 "Enabled" 2 "Active" 3 "Unused" ;
VAL_ 761 ABFI_CollPrepSysInhbt 1 "true" 0 "false" ;
VAL_ 761 ABFI_RrVirtlBmprInh 1 "true" 0 "false" ;
VAL_ 761 BrkPdlDrvApplPresV 1 "Invalid" 0 "Valid" ;
VAL_ 761 AutoBrkPTReqStat 0 "Inactive" 1 "Active" 2 "Failed" 3 "Serial Communication Failure" 4 "Unused and Reserved 1" 5 "Unused and Reserved 2" 6 "Unused and Reserved 3" 7 "Unused and Reserved 4" ;
VAL_ 761 WhlSpdSnsgDTCStat 0 "Not Supported" 1 "Critically Disabled" 2 "No Status to Report" 3 "Diagnostic Passed" 4 "Diagnostic Failed" ;
VAL_ 761 SprTireSt 2 "Spare Detected" 1 "No Spare Detected" 0 "Undetermined" ;
VAL_ 453 DrvIntndAxlTrqV 1 "Invalid" 0 "Valid" ;
VAL_ 453 DrvIntndAxlTrqMinV 1 "Invalid" 0 "Valid" ;
VAL_ 453 DrvIntndAxlTrqMaxV 1 "Invalid" 0 "Valid" ;
VAL_ 463 FourWhlDrvIndReq 0 "No Indication" 1 "Indication 1" 2 "Indication 2" 3 "Indication 3" 4 "Indication 4" 5 "Indication 5" 6 "Indication 6" 7 "Indication 7" ;
VAL_ 463 SecAxlNonEmMalfIO 1 "true" 0 "false" ;
VAL_ 463 SecAxlOperMod 3 "Active All Wheel Drive (High)" 2 "4 Wheel Drive Low Locked" 1 "4 Wheel Drive High Locked" 0 "2 Wheel Drive High" 15 "Neutral" 14 "Unknown" 7 "2 Wheel Drive Low" 6 "Active All Wheel Drive (Low)" 5 "4 Wheel Drive Low Open" 4 "4 Wheel Drive High Open" ;
VAL_ 463 SecAxlTmpInhIO 1 "true" 0 "false" ;
VAL_ 419 ClrCGMLgsDgInf 1 "true" 0 "false" ;
VAL_ 419 EngRunng 1 "true" 0 "false" ;
VAL_ 707 CSTATRS_ReqStat 6 "Control System Failure Permanent" 5 "Control System Failure Temporary" 4 "Serial Data Failure Permanent" 3 "Serial Data Failure Temporary" 2 "Lost Arbitration" 1 "Request Honored" 0 "No Request" ;
VAL_ 707 CSTATRS_LmtgStat 3 "Rate and Value Limited" 2 "Value Limited" 1 "Rate Limited" 0 "Not Limited" ;
VAL_ 707 EngManfldAbsPrsV 1 "Invalid" 0 "Valid" ;
VAL_ 707 EngTrqMinExtRngV 1 "Invalid" 0 "Valid" ;
VAL_ 707 EngTrqMaxExtRngV 1 "Invalid" 0 "Valid" ;
VAL_ 707 TrqAthdCrsCntrlDsgRsn 17 "CiCRZC_RsmAccelSwTogether" 16 "CiCRZC_PCM_Inhibit" 15 "CiCRZC_OverSpeedTapDown" 14 "CiCRZC_OverSpeed" 13 "CiCRZC_SwOff" 12 "CiCRZC_None" 11 "CiCRZC_LowSpeed" 10 "CiCRZC_IllegalCruzMode" 9 "CiCRZC_HighSpeed" 8 "CiCRZC_HighDecel" 7 "CiCRZC_HighAccel" 6 "CiCRZC_ETC" 5 "CiCRZC_CoastInhibit" 4 "CiCRZC_CoastDisengage" 3 "CiCRZC_Clutch" 2 "CiCRZC_Cancel" 1 "CiCRZC_BrakeBeforeCruz" 0 "CiCRZC_Brake" 74 "CeCRZC_e_HybTorqSigTO" 73 "CeCRZC_e_LCC_SerialDataFault" 72 "CeCRZC_e_ACC_InvalidEngage" 71 "CeCRZC_e_ACC_Off" 70 "CeCRZC_e_ACC_Brake" 69 "CeCRZC_e_ACC_Cancel" 68 "CeCRZC_e_ACC_RedEngPwr" 67 "CiCRZC_VSESFaulted" 66 "CiCRZC_TCSFaulted" 65 "CeCRZC_e_ABS" 64 "CeCRZC_e_VSESOff" 63 "CeCRZC_e_TCSOff" 62 "CeCRZC_e_HybridCruiseDisengage" 61 "CeCRZC_e_HillDescentSerDatInhb" 60 "CeCRZC_e_HillDescentActive" 59 "CeCRZC_e_AutoBrkSerialDataFlt" 58 "CeCRZC_e_AutoBrkFailed" 57 "CeCRZC_e_NotUsed" 56 "CeCRZC_e_SLSW_SwitchOn" 55 "CeCRZC_e_BrkPdlDrvrAplyPressDet" 54 "CeCRZC_e_ManlGrChngWithoutClch" 53 "CeCRZC_e_4WD_LowDisable" 52 "CeCRZC_e_RateLimError" 51 "CeCRZC_e_BrkAplySnsrHomeNotLrnd" 50 "CeCRZC_e_ProcIntegFault" 49 "CeCRZC_e_RunningReset" 48 "CeCRZC_e_PTO" 47 "CeCRZC_e_ACC_CmdSerialDataError" 46 "CeCRZC_e_CntrlSysTypeError" 45 "CeCRZC_e_ACC_AutoBrkFailed" 44 "CeCRZC_e_ACC_Inhibited" 43 "CeCRZC_e_ParkBrakeActive" 42 "CeCRZC_e_BrakeApplyInvalid" 41 "CeCRZC_e_BrakeSerDatError" 40 "CeCRZC_e_TransGrDfltd" 39 "CeCRZC_e_RearAxleLow" 38 "CiCRZC_e_VehStabilityActive" 37 "CiCRZC_e_MetalOvertempActive" 36 "CiCRZC_e_SerialDataFault" 35 "CiCRZC_Sequence" 34 "CiCRZC_DrivenWhlSpdGreater" 33 "CiCRZC_UndrivenWhlSpdGreater" 32 "CiCRZC_HighIgnVoltage" 31 "CiCRZC_AnalogCruzOOR" 30 "CiCRZC_MPH_LimitedFuelEst" 29 "CiCRZC_ManlNeutCruz" 28 "CiCRZC_LowIgnVoltage" 27 "CiCRZC_PedGreaterThanCruz" 26 "CiCRZC_FirstGearDsbl" 25 "CiCRZC_InjectorDsbld" 24 "CiCRZC_Malf" 23 "CiCRZC_EngSpd" 22 "CiCRZC_EngRunTime" 21 "CiCRZC_BadMemory" 20 "CiCRZC_ALDL" 19 "CiCRZC_UnderSchedule" 18 "CiCRZC_TCS" ;
VAL_ 451 HillDscntCtrlSwStat 0 "No Activation" 1 "Increment" 2 "Decrement" 3 "Faulted" ;
VAL_ 451 GlwPlgCrnkDelAct 1 "true" 0 "false" ;
VAL_ 451 AuxHtrAlwd 1 "true" 0 "false" ;
VAL_ 451 AppCltchAutSrtIO 1 "true" 0 "false" ;
VAL_ 451 AccPosV 1 "Invalid" 0 "Valid" ;
VAL_ 451 EngTrqRdFlrSt 4 "Torq Reduction Communication Failed" 3 "Torque Reduction Limited" 2 "Torque Reduction Permanently Failed" 1 "Torque Reduction Temporarily Failed" 0 "Torque Reduction OK" ;
VAL_ 451 EngTrqDrRqdExtRngV 1 "Invalid" 0 "Valid" ;
VAL_ 451 EngTrqActExtRngV 1 "Invalid" 0 "Valid" ;
VAL_ 451 TrqAthdCrsCntrlAtv 1 "true" 0 "false" ;
VAL_ 451 CrsCntrlRsmSet 1 "true" 0 "false" ;
VAL_ 451 CrsCntrlSetSpdRtnd 1 "true" 0 "false" ;
VAL_ 451 CrsCntrlSet 1 "true" 0 "false" ;
VAL_ 241 NotEventStat 2 "Pretensioner Deployment Event" 1 "Near Deployment Event" 0 "No Event" 3 "Airbag Deployment Event" ;
VAL_ 241 BrkAppSnsrHmPosLrnd 1 "true" 0 "false" ;
VAL_ 241 BrkPedTrvlAchvd 1 "true" 0 "false" ;
VAL_ 241 BrkPedTrvlAchvdV 1 "Invalid" 0 "Valid" ;
VAL_ 241 BrkPdlModTrvlV 1 "Invalid" 0 "Valid" ;
VAL_ 241 BrkPdlModTrvl 1 "true" 0 "false" ;
VAL_ 844 IMUProtYawRtM 1 "Use Data" 0 "Don't Use Data" ;
VAL_ 844 IMUProtLonAccM 1 "Use Data" 0 "Don't Use Data" ;
VAL_ 844 IMUProtLatAccM 1 "Use Data" 0 "Don't Use Data" ;
VAL_ 844 IMUProtLonAccV 1 "Invalid" 0 "Valid" ;
VAL_ 844 StrAngSnsPolRat 0 "Not Passed" 1 "Passed" ;
VAL_ 501 ElcRngSelDrvAct 1 "true" 0 "false" ;
VAL_ 501 TmpDrvrShftCtlAct 1 "true" 0 "false" ;
VAL_ 501 EngRecDwnshftIO 1 "true" 0 "false" ;
VAL_ 501 TrnsPattSelEcnMdOCm 1 "true" 0 "false" ;
VAL_ 501 CltStartSwAtvV 1 "Invalid" 0 "Valid" ;
VAL_ 501 CltStartSwAtv 1 "true" 0 "false" ;
VAL_ 501 CltchPdlActPosV 1 "Invalid" 0 "Valid" ;
VAL_ 501 TrnsEngdStateV 1 "Invalid" 0 "Valid" ;
VAL_ 501 TrnsEngdState 3 "Operating State Not Reached" 2 "Transmission Engaged in Reverse" 1 "Transmission Engaged in Forward" 0 "Transmission Not Engaged" ;
VAL_ 501 TrnsShftLvrLckRqd 1 "true" 0 "false" ;
VAL_ 501 TransTUDMdStat 2 "Electronic Range Select Active" 1 "Driver Shift Control Active" 0 "No Activation" ;
VAL_ 501 TrnCrpMdAtv 1 "true" 0 "false" ;
VAL_ 501 TrnsSkpShftIO 1 "true" 0 "false" ;
VAL_ 501 TrnsSftMdStat 3 "Automatic Grade Braking Mode" 2 "Lift-Foot Cornering Mode" 1 "Performance Mode" 0 "No Override Mode" ;
VAL_ 501 TrnsRngInhbtStat 4 "Diagnostic Inhibit Active" 3 "Driveline Not Engaged" 2 "Transmission Range Re-Selection Req" 1 "Transmission Inhibit Active" 0 "No Range Inhibit Active" ;
VAL_ 501 TopTrvlCltchSwActV 1 "Invalid" 0 "Valid" ;
VAL_ 501 TopTrvlCltchSwAct 1 "true" 0 "false" ;
VAL_ 501 EngRecmndUpshftIO 1 "true" 0 "false" ;
VAL_ 501 DrvtShftCntrlTrgtGear 10 "Tenth Gear" 9 "Ninth Gear" 8 "Eighth Gear" 7 "Seventh Gear" 6 "Sixth Gear" 5 "Fifth Gear" 4 "Fourth Gear" 3 "Third Gear" 2 "Second Gear" 1 "First Gear" 0 "Not Supported" ;
VAL_ 501 DrShftCntrlReqDndIO 1 "true" 0 "false" ;
VAL_ 501 TrnShftPtrnActStat 6 "PT Protection Pattern Active" 5 "PT Non-Protection Pattern Active" 4 "Shift Pattern 4 Active" 3 "Shift Pattern 3 Active" 2 "Shift Pattern 2 Active" 1 "Shift Pattern 1 Active" 0 "Default Shift Pattern Active" ;
VAL_ 501 TrnsFldPrsPrsnt 1 "true" 0 "false" ;
VAL_ 501 TrnsShftLvrPos 13 "Forward Range J" 12 "Froward Range I" 15 "Lever Position Unknown" 11 "Forward Range H" 10 "Forward Range G" 9 "Forward Range F" 8 "Forward Range E" 7 "Forward Range D" 6 "Forward Range C" 5 "Forward Range B" 4 "Forward Range A" 3 "Neutral Range" 2 "Reverse Range" 1 "Park Range" 0 "Between Ranges" ;
VAL_ 501 TrnsShftLvrPosV 1 "Invalid" 0 "Valid" ;
VAL_ 501 TrnsTrqCnvCltCmndMd 7 "Not Supported" 3 "Locked" 2 "Controlled Slip" 1 "Transitioning" 0 "Unlocked" ;
VAL_ 501 AutoTransComndGear 9 "Ninth Gear" 15 "Park Gear" 14 "Reverse Gear" 13 "Neutral Gear" 12 "CVT Forward Gear" 11 "Unused and Reserved" 10 "Tenth Gear" 8 "Eighth Gear" 7 "Seventh Gear" 6 "Sixth Gear" 5 "Fifth Gear" 4 "Fourth Gear" 3 "Third Gear" 2 "Second Gear" 1 "First Gear" 0 "Not Supported" ;
VAL_ 501 AutoTransGrSftDirect 2 "Downshift in Progress" 1 "Upshift in Progress" 0 "No Shift in Progress" ;
VAL_ 501 TransEstGear 9 "Ninth Gear" 15 "Park Gear" 14 "Reverse Gear" 13 "Neutral Gear" 12 "CVT Forward Gear" 11 "Unused and Reserved" 10 "Tenth Gear" 8 "Eighth Gear" 7 "Seventh Gear" 6 "Sixth Gear" 5 "Fifth Gear" 4 "Fourth Gear" 3 "Third Gear" 2 "Second Gear" 1 "First Gear" 0 "Not Supported" ;
VAL_ 501 TransEstGearV 1 "Invalid" 0 "Valid" ;
VAL_ 211 ActAxleTrqV 1 "Invalid" 0 "Valid" ;
VAL_ 1265 IdlRecmndToClEngIO 1 "true" 0 "false" ;
VAL_ 1265 PTSysHzrdLghtReq 1 "true" 0 "false" ;
VAL_ 1265 EngOffTmPTV 1 "Invalid" 0 "Valid" ;
VAL_ 1265 EngOffTmPTM 1 "Use Data" 0 "Don't Use Data" ;
VAL_ 1322 TireRRPrsV 1 "Invalid" 0 "Valid" ;
VAL_ 1322 TireRRPrsStat 5 "High" 4 "Low - Extended Mobility" 3 "Low" 2 "Low - Service Now" 1 "Nominal" 0 "Unknown" ;
VAL_ 1322 TireRFPrsV 1 "Invalid" 0 "Valid" ;
VAL_ 1322 TireRFPrsStat 5 "High" 4 "Low - Extended Mobility" 3 "Low" 2 "Low - Service Now" 1 "Nominal" 0 "Unknown" ;
VAL_ 1322 TireLRPrsV 1 "Invalid" 0 "Valid" ;
VAL_ 1322 TireLRPrsStat 5 "High" 4 "Low - Extended Mobility" 3 "Low" 2 "Low - Service Now" 1 "Nominal" 0 "Unknown" ;
VAL_ 1322 TireLFPrsV 1 "Invalid" 0 "Valid" ;
VAL_ 1322 TireLFPrsStat 5 "High" 4 "Low - Extended Mobility" 3 "Low" 2 "Low - Service Now" 1 "Nominal" 0 "Unknown" ;
VAL_ 193 WRSLDWhlRotStatRst 1 "true" 0 "false" ;
VAL_ 193 WRSLDWhlDistVal 1 "Invalid" 0 "Valid" ;
VAL_ 193 WRSRDWhlRotStatRst 1 "true" 0 "false" ;
VAL_ 193 WRSRDWhlDistVal 1 "Invalid" 0 "Valid" ;
VAL_ 344 CSS_CoPilotCibAvail 1 "true" 0 "false" ;
VAL_ 344 CSS_CoPilotSysFltStat 5 "Copilot System Failure" 4 "Partial Function Fault Detected" 3 "Redundancy Fault Detected" 2 "Environmental Interference" 1 "Operational" 0 "Unknown" ;
VAL_ 344 CSS_CoPilotRvbAvail 1 "true" 0 "false" ;
VAL_ 344 CSS_CoPilotPcmAvail 1 "true" 0 "false" ;
VAL_ 344 CSS_CoPilotFcaAvail 1 "true" 0 "false" ;
VAL_ 344 CSS_CoPilotBrkExpctd 1 "true" 0 "false" ;
VAL_ 344 StrgAngTrqBsdEstSrfcMuConf 2 "Indeterminate" 1 "Use Data" 0 "Do Not Use Data" ;
VAL_ 344 StrgAngTrqBsdEstSrfcMuCapV 1 "Invalid" 0 "Valid" ;
VAL_ 533 ExtBrkReqStat 3 "External Brake Req Active" 2 "External Brake Req Available" 1 "External Brake Req Not Available" 0 "Unknown" ;
VAL_ 533 SecLongStabSysStatRed 3 "Failed" 2 "Active" 1 "Available" 0 "Unknown" ;
VAL_ 533 SecLatStabSysStatRed 3 "Failed" 2 "Active" 1 "Available" 0 "Unknown" ;
VAL_ 533 SecGrsHydLkDtctdRed 1 "true" 0 "false" ;
VAL_ 533 SecGrsHydCmpDtctdRed 1 "true" 0 "false" ;
VAL_ 533 RedBlkPedDet 1 "true" 0 "false" ;
VAL_ 533 RediBstStat 7 "iBooster Ready" 6 "iBooster PostRun Reduced" 5 "iBooster Reduced" 2 "iBooster Diagnosis" 1 "iBooster Failure iBoosterOff" 0 "Unknown" 3 "iBooster Autonomous Diagnosis" 4 "iBooster Standalone" ;
VAL_ 233 ACATC2_AutoCoPCntrlAct 1 "true" 0 "false" ;
VAL_ 347 EBstRnotPrsQlfr 2 "Faulted" 1 "Normal" 0 "Unknown" ;
VAL_ 347 BrkPedApdQlfr 2 "Faulted" 1 "Normal" 0 "Unknown" ;
VAL_ 347 BrkPedApd 1 "true" 0 "false" ;
VAL_ 347 SecBrkModStatRed 3 "Failed" 2 "Active" 1 "Available" 0 "Not Available" ;
VAL_ 347 SecAutoEstBrkTrqAppStatRed 2 "Valid" 1 "Reduced Accuracy" 0 "Invalid" ;
VAL_ 347 SecAutoBrkSysDrInfcStatRed 3 "Failed" 2 "Driver Intervention Not Detected" 1 "Driver Intervention Detected" 0 "Unknown" ;
VAL_ 479 EngAutoStpNotProb 1 "true" 0 "false" ;
VAL_ 479 EASSI_UnsdRsrvd2 1 "true" 0 "false" ;
VAL_ 479 EASSI_StlDetd 1 "true" 0 "false" ;
VAL_ 479 EASSI_TrqDetd 1 "true" 0 "false" ;
VAL_ 479 EASSI_FuelReqOn 1 "true" 0 "false" ;
VAL_ 479 EASSI_StrtTyp 7 "Type G" 6 "Type F" 5 "Type E" 4 "Type D" 3 "Type C" 2 "Type B" 1 "Type A" 0 "No Start" ;
VAL_ 479 EASSI_StrtStpSt 3 "Engine Stopping" 2 "Engine Starting" 1 "Engine Running" 0 "Engine Off" ;
VAL_ 479 EASSI_TorqDetdIndet 1 "true" 0 "false" ;
VAL_ 479 ASIRI_Indication08 1 "true" 0 "false" ;
VAL_ 479 ASIRI_Indication07 1 "true" 0 "false" ;
VAL_ 479 ASIRI_Indication06 1 "true" 0 "false" ;
VAL_ 479 ASIRI_Indication05 1 "true" 0 "false" ;
VAL_ 479 ASIRI_Indication04 1 "true" 0 "false" ;
VAL_ 479 ASIRI_Indication03 1 "true" 0 "false" ;
VAL_ 479 ASIRI_Indication02 1 "true" 0 "false" ;
VAL_ 479 ASIRI_Indication01 1 "true" 0 "false" ;
VAL_ 479 PTWrmgWtToShftIO 1 "true" 0 "false" ;
VAL_ 479 PrplsnSysAtv 1 "true" 0 "false" ;
VAL_ 479 PTShftLvrLckRqd 1 "true" 0 "false" ;
VAL_ 452 FSpRgACCSwADd 1 "true" 0 "false" ;
VAL_ 452 ABAAPS_AccPosV 1 "Invalid" 0 "Valid" ;
VAL_ 452 ACCATCS_LmtgStat 3 "Request Rate Limited" 2 "Request Value Limited Maximum" 1 "Request Value Limited Minimum" 0 "Request Not Limited" ;
VAL_ 452 ACCATCS_RqStat 4 "Request Suspended Till Driver Input" 3 "Request Denied" 2 "Lost Arbitration" 1 "Request Honored" 0 "No Request" ;
VAL_ 452 AccPdlOvrrdAtv 1 "true" 0 "false" ;
VAL_ 452 CPSATCS_ReqStatus 0 "No Request" 1 "Request Honored" 2 "Lost Arbitration" 3 "Serial Data Failure Temporary" 4 "Serial Data Failure Permanent" 5 "Control System Failure Temporary" 6 "Control System Failure Permanent" ;
VAL_ 452 CPSATCS_LmtngStatus 0 "Request Not Limited" 1 "Request Value Limited to Minimum" 2 "Request Value Limited to Maximum" 3 "Request Rate Limited" ;
VAL_ 452 RVBATCS_ReqStat 0 "No Request" 1 "Request Honored" 2 "Lost Arbitration" 3 "Serial Data Failure Temporary" 4 "Serial Data Failure Permanent" 5 "Control System Failure Temporary" 6 "Control System Failure Permanent" ;
VAL_ 452 RVBATCS_LmtngStat 0 "Request Not Limited" 1 "Request Value Limited to Minimum" 2 "Request Value Limited to Maximum" 3 "Request Rate Limited" ;
VAL_ 298 DrvrDrAjrSwVDA 1 "VirtualDeviceAvailable" 0 "VirtualDeviceUnavailable" ;
VAL_ 298 ValetMdAct 1 "true" 0 "false" ;
VAL_ 298 AutoMdSpdLmtCnfrmd 1 "true" 0 "false" ;
VAL_ 298 TCSysDisSwAtv_12A 1 "true" 0 "false" ;
VAL_ 298 ChmAct 1 "true" 0 "false" ;
VAL_ 298 Ky_IdDevPr 1 "true" 0 "false" ;
VAL_ 298 DDAjrSwAtvM 1 "Use Data" 0 "Don't Use Data" ;
VAL_ 298 PsSbltAtcV 1 "Invalid" 0 "Valid" ;
VAL_ 298 PsSbltAtc 1 "true" 0 "false" ;
VAL_ 298 TrlrBrkDsplyAct 1 "true" 0 "false" ;
VAL_ 298 RdSpdCatType 3 "all speed categories 0 - 50 km/h" 2 "all speed categories 51-80 km/h" 1 "all speed categories 81-130 km/h" 0 "all speed categories > 130 km/h" ;
VAL_ 298 LnCat 3 "Four Or More Lanes" 2 "Two Or Three Lanes" 1 "One lane" 0 "no info available" ;
VAL_ 298 FncRdClass 7 "COLLECTOR" 6 "ALLEY" 5 "ARTERIAL" 4 "HIGHWAY" 3 "PED-MALL" 2 "FREEWAY" 1 "SFREEWAY" 0 "LOCAL (Residential Road)" ;
VAL_ 298 SprtLnRd 1 "true" 0 "false" ;
VAL_ 298 CntrldAccRd 1 "true" 0 "false" ;
VAL_ 298 BldUpArDet 1 "true" 0 "false" ;
VAL_ 298 MpDataAvlbl 1 "true" 0 "false" ;
VAL_ 298 SusCustStngReq 4 "Performance Mode 4" 3 "Performance Mode 3" 2 "Performance Mode 2" 1 "Performance Mode 1" 0 "No Action" 7 "Auto" 6 "Performance Mode 6" 5 "Performance Mode 5" ;
VAL_ 298 StrCustStngReq 4 "Performance Mode 4" 3 "Performance Mode 3" 2 "Performance Mode 2" 1 "Performance Mode 1" 0 "No Action" 7 "Auto" 6 "Performance Mode 6" 5 "Performance Mode 5" ;
VAL_ 298 RstrCustFctrDef 1 "Restore Defaults" 0 "No Action" ;
VAL_ 298 DrvlnCustStngReq 4 "Performance Mode 4" 3 "Performance Mode 3" 2 "Performance Mode 2" 1 "Performance Mode 1" 0 "No Action" 7 "Auto" 6 "Performance Mode 6" 5 "Performance Mode 5" ;
VAL_ 298 ChmMstrVDA 1 "VirtualDeviceAvailable" 0 "VirtualDeviceUnavailable" ;
VAL_ 298 IPCVDA 1 "VirtualDeviceAvailable" 0 "VirtualDeviceUnavailable" ;
VAL_ 298 HeadUpDispVDA 1 "VirtualDeviceAvailable" 0 "VirtualDeviceUnavailable" ;
VAL_ 298 HapticSeatVDA 1 "VirtualDeviceAvailable" 0 "VirtualDeviceUnavailable" ;
VAL_ 298 RRDoorAjarSwAct 1 "true" 0 "false" ;
VAL_ 298 PDAjrSwAtv 1 "true" 0 "false" ;
VAL_ 298 DDAjrSwAtv 1 "true" 0 "false" ;
VAL_ 298 TrlrHWIntrfcVDA 1 "VirtualDeviceAvailable" 0 "VirtualDeviceUnavailable" ;
VAL_ 298 DrId 7 "Unknown" 6 "Driver #7" 5 "Driver #6" 4 "Driver #5" 3 "Driver #4" 2 "Driver #3" 1 "Driver #2" 0 "Driver #1" ;
VAL_ 298 EnrgMgtLdShdRq 4 "Load Shed Level 4" 3 "Load Shed Level 3" 2 "Load Shed Level 2" 1 "Load Shed Level 1" 0 "No Load Shedding" ;
VAL_ 298 DrSbltAtcV 1 "Invalid" 0 "Valid" ;
VAL_ 298 TrlrHtchSwAtv 1 "true" 0 "false" ;
VAL_ 298 TreInfMonSysRstReq 1 "true" 0 "false" ;
VAL_ 298 HUDActv 1 "true" 0 "false" ;
VAL_ 298 BatVltV 1 "Invalid" 0 "Valid" ;
VAL_ 298 RLDoorAjarSwAct 1 "true" 0 "false" ;
VAL_ 298 DrSbltAtc 1 "true" 0 "false" ;
SIG_GROUP_ 386 PerfMdVislztnScrnStat 1 : PMVSS_Disps PMVSS_Exhst PMVSS_PsngrSeat PMVSS_DrvrSeat PMVSS_AdptCrsCnt PMVSS_Drvln PMVSS_Susp PMVSS_Strng PMVSS_Trans PMVSS_Eng PMVSS_Snd;
SIG_GROUP_ 560 ElecPrkBrkCmd 1 : EPBC_EPBAccRq EPBC_EPBrkAutBrkRq;
SIG_GROUP_ 761 AutoBrkFeatInhbt 1 : ABFI_CollPrepSysInhbt ABFI_RrVirtlBmprInh;
SIG_GROUP_ 761 WhlSpdSnsLgsDiagStat 1 : WhlSpdSnsgDTCIndex WhlSpdSnsgDTCStat;
SIG_GROUP_ 707 ChsSysTtlAxleTrqRqSt 1 : CSTATRS_ReqStat CSTATRS_LmtgStat;
SIG_GROUP_ 241 BrkPedInitTrvlAchvdStat 1 : BrkPedTrvlAchvd BrkPedTrvlAchvdV;
SIG_GROUP_ 193 WhlRotatStatLftDrvn 1 : WRSLDWhlRotStatRst WRSLDWhlDisTpRC WRSLDSeqNum WRSLDWhlDistVal WRSLDWhlDistTmstm WRSLDWhlDistPlsCntr;
SIG_GROUP_ 193 WhlRotatStatRtDrvn 1 : WRSRDWhlDisTpRC WRSRDSeqNum WRSRDWhlRotStatRst WRSRDWhlDistVal WRSRDWhlDistTmstm WRSRDWhlDistPlsCntr;
SIG_GROUP_ 344 CoPilotSysStat 1 : CSS_CoPilotCibAvail CSS_CoPilotSysFltStat CSS_CoPilotRvbAvail CSS_CoPilotPcmAvail CSS_CoPilotFcaAvail CSS_CoPilotBrkExpctd;
SIG_GROUP_ 233 AutoCoPAxlTrqCmnd2 1 : ACATC2_AutoCoPCntrlAct ACATC2_CoPAxlTrqReq;
SIG_GROUP_ 479 EngAutoStrtStpInfo 1 : EASSI_UnsdRsrvd2 EASSI_StlDetd EASSI_TrqDetd EASSI_FuelReqOn EASSI_StrtTyp EASSI_StrtStpSt EASSI_TorqDetdIndet;
SIG_GROUP_ 479 AutoStpInhbtRsnInd 1 : ASIRI_Indication08 ASIRI_Indication07 ASIRI_Indication06 ASIRI_Indication05 ASIRI_Indication04 ASIRI_Indication03 ASIRI_Indication02 ASIRI_Indication01;
SIG_GROUP_ 452 AutBrkAccActPsSt 1 : ABAAPS_AccPos ABAAPS_AccPosV;
SIG_GROUP_ 452 ACCAxlTrqCmdStat 1 : ACCATCS_LmtgStat ACCATCS_RqStat;
SIG_GROUP_ 452 ColPrSysAxlTrqCmdStat 1 : CPSATCS_ReqStatus CPSATCS_LmtngStatus;
SIG_GROUP_ 452 RrVrtBmpAxlTrqCmdStat 1 : RVBATCS_ReqStat RVBATCS_LmtngStat;
